VERSION ""

NS_ :

BS_:

BU_:

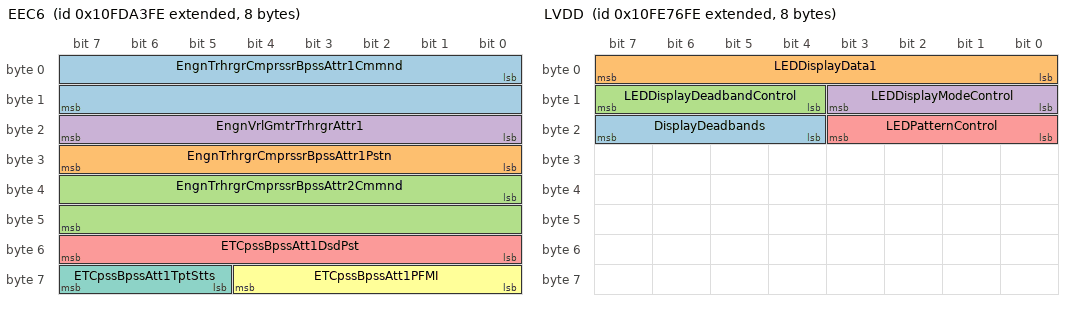
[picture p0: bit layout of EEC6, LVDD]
BO_ 2432541694 EEC6: 8 Vector__XXX
 SG_ EngnTrhrgrCmprssrBpssAttr1Cmmnd : 0|16@1+ (0.0025,0) [0|160.6375] "%" Vector__XXX
 SG_ EngnTrhrgrCmprssrBpssAttr1Pstn : 24|8@1+ (0.4,0) [0|100] "%" Vector__XXX
 SG_ EngnTrhrgrCmprssrBpssAttr2Cmmnd : 32|16@1+ (0.0025,0) [0|160.6375] "%" Vector__XXX
 SG_ EngnVrlGmtrTrhrgrAttr1 : 16|8@1+ (0.4,0) [0|100] "%" Vector__XXX
 SG_ ETCpssBpssAtt1DsdPst : 48|8@1+ (0.4,0) [0|100] "%" Vector__XXX
 SG_ ETCpssBpssAtt1PFMI : 56|5@1+ (1,0) [0|31] "binary" Vector__XXX
 SG_ ETCpssBpssAtt1TptStts : 61|3@1+ (1,0) [0|7] "" Vector__XXX

BO_ 2432593918 ACC1: 8 Vector__XXX
 SG_ ACCDistanceAlertSignal : 52|2@1+ (1,0) [0|3] "" Vector__XXX
 SG_ ACCSystemShutoffWarning : 50|2@1+ (1,0) [0|3] "" Vector__XXX
 SG_ ACCTargetDetected : 48|2@1+ (1,0) [0|3] "" Vector__XXX
 SG_ AdaptiveCruiseControlMode : 24|3@1+ (1,0) [0|7] "" Vector__XXX
 SG_ AdaptiveCruiseControlSetSpeed : 16|8@1+ (1,0) [0|250] "km/h" Vector__XXX
 SG_ Adptvrsntrlstdstnmd : 27|3@1+ (1,0) [0|7] "" Vector__XXX
 SG_ Distancetoforwardvehicle : 8|8@1+ (1,0) [0|250] "m" Vector__XXX
 SG_ ForwardCollisionWarning : 54|2@1+ (1,0) [0|3] "" Vector__XXX
 SG_ Roadcurvature : 32|16@1+ (0.0078125,-250) [-250|251.992] "1/km" Vector__XXX
 SG_ Speedofforwardvehicle : 0|8@1+ (1,0) [0|250] "km/h" Vector__XXX

BO_ 2432595710 LVDD: 8 Vector__XXX
 SG_ DisplayDeadbands : 20|4@1+ (1,0) [0|15] "" Vector__XXX
 SG_ LEDDisplayData1 : 0|8@1+ (1,0) [0|255] "" Vector__XXX
 SG_ LEDDisplayDeadbandControl : 12|4@1+ (1,0) [0|15] "" Vector__XXX
 SG_ LEDDisplayModeControl : 8|4@1+ (1,0) [0|15] "" Vector__XXX
 SG_ LEDPatternControl : 16|4@1+ (1,0) [0|15] "" Vector__XXX

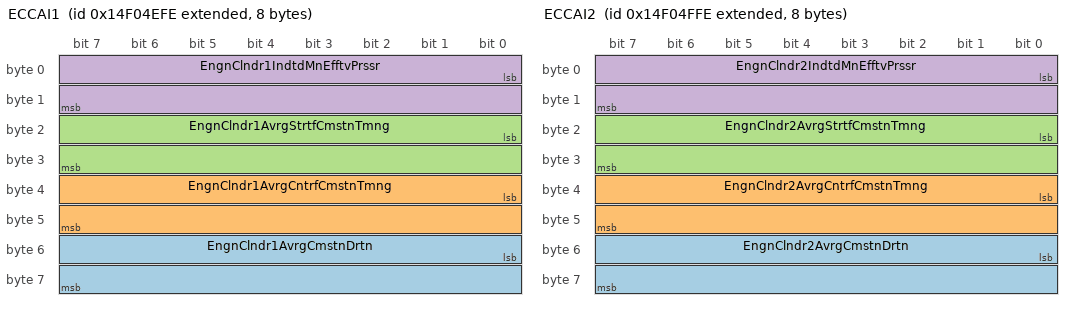
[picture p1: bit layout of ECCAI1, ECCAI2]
BO_ 2498776830 ECCAI1: 8 Vector__XXX
 SG_ EngnClndr1AvrgCmstnDrtn : 48|16@1+ (0.0078125,0) [0|501.99] "deg" Vector__XXX
 SG_ EngnClndr1AvrgCntrfCmstnTmng : 32|16@1+ (0.0078125,-250) [-250|250.992] "deg" Vector__XXX
 SG_ EngnClndr1AvrgStrtfCmstnTmng : 16|16@1+ (0.0078125,-250) [-250|250.992] "deg" Vector__XXX
 SG_ EngnClndr1IndtdMnEfftvPrssr : 0|16@1+ (0.0001220703125,-1) [-1|6.84362793] "MPa" Vector__XXX

BO_ 2498777086 ECCAI2: 8 Vector__XXX
 SG_ EngnClndr2AvrgCmstnDrtn : 48|16@1+ (0.0078125,0) [0|501.99] "deg" Vector__XXX
 SG_ EngnClndr2AvrgCntrfCmstnTmng : 32|16@1+ (0.0078125,-250) [-250|250.992] "deg" Vector__XXX
 SG_ EngnClndr2AvrgStrtfCmstnTmng : 16|16@1+ (0.0078125,-250) [-250|250.992] "deg" Vector__XXX
 SG_ EngnClndr2IndtdMnEfftvPrssr : 0|16@1+ (0.0001220703125,-1) [-1|6.84362793] "MPa" Vector__XXX

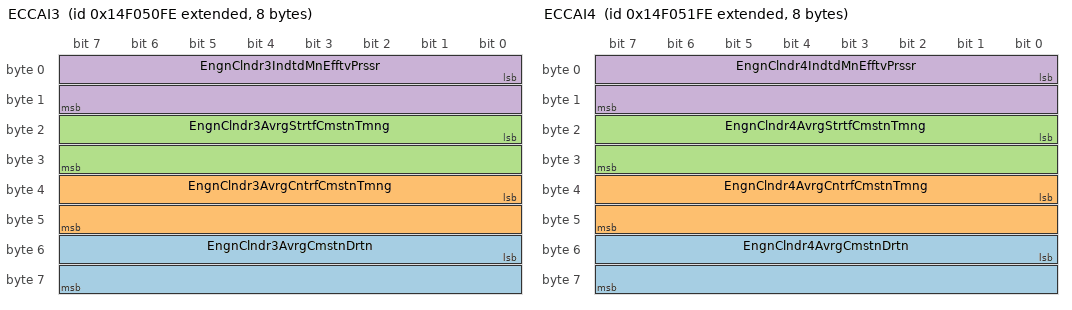
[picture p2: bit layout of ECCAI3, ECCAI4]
BO_ 2498777342 ECCAI3: 8 Vector__XXX
 SG_ EngnClndr3AvrgCmstnDrtn : 48|16@1+ (0.0078125,0) [0|501.99] "deg" Vector__XXX
 SG_ EngnClndr3AvrgCntrfCmstnTmng : 32|16@1+ (0.0078125,-250) [-250|250.992] "deg" Vector__XXX
 SG_ EngnClndr3AvrgStrtfCmstnTmng : 16|16@1+ (0.0078125,-250) [-250|250.992] "deg" Vector__XXX
 SG_ EngnClndr3IndtdMnEfftvPrssr : 0|16@1+ (0.0001220703125,-1) [-1|6.84362793] "MPa" Vector__XXX

BO_ 2498777598 ECCAI4: 8 Vector__XXX
 SG_ EngnClndr4AvrgCmstnDrtn : 48|16@1+ (0.0078125,0) [0|501.99] "deg" Vector__XXX
 SG_ EngnClndr4AvrgCntrfCmstnTmng : 32|16@1+ (0.0078125,-250) [-250|250.992] "deg" Vector__XXX
 SG_ EngnClndr4AvrgStrtfCmstnTmng : 16|16@1+ (0.0078125,-250) [-250|250.992] "deg" Vector__XXX
 SG_ EngnClndr4IndtdMnEfftvPrssr : 0|16@1+ (0.0001220703125,-1) [-1|6.84362793] "MPa" Vector__XXX

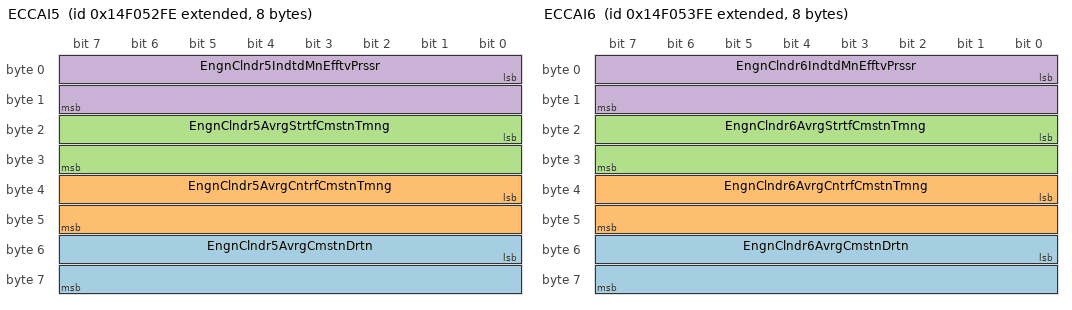
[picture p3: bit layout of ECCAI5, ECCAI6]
BO_ 2498777854 ECCAI5: 8 Vector__XXX
 SG_ EngnClndr5AvrgCmstnDrtn : 48|16@1+ (0.0078125,0) [0|501.99] "deg" Vector__XXX
 SG_ EngnClndr5AvrgCntrfCmstnTmng : 32|16@1+ (0.0078125,-250) [-250|250.992] "deg" Vector__XXX
 SG_ EngnClndr5AvrgStrtfCmstnTmng : 16|16@1+ (0.0078125,-250) [-250|250.992] "deg" Vector__XXX
 SG_ EngnClndr5IndtdMnEfftvPrssr : 0|16@1+ (0.0001220703125,-1) [-1|6.84362793] "MPa" Vector__XXX

BO_ 2498778110 ECCAI6: 8 Vector__XXX
 SG_ EngnClndr6AvrgCmstnDrtn : 48|16@1+ (0.0078125,0) [0|501.99] "deg" Vector__XXX
 SG_ EngnClndr6AvrgCntrfCmstnTmng : 32|16@1+ (0.0078125,-250) [-250|250.992] "deg" Vector__XXX
 SG_ EngnClndr6AvrgStrtfCmstnTmng : 16|16@1+ (0.0078125,-250) [-250|250.992] "deg" Vector__XXX
 SG_ EngnClndr6IndtdMnEfftvPrssr : 0|16@1+ (0.0001220703125,-1) [-1|6.84362793] "MPa" Vector__XXX

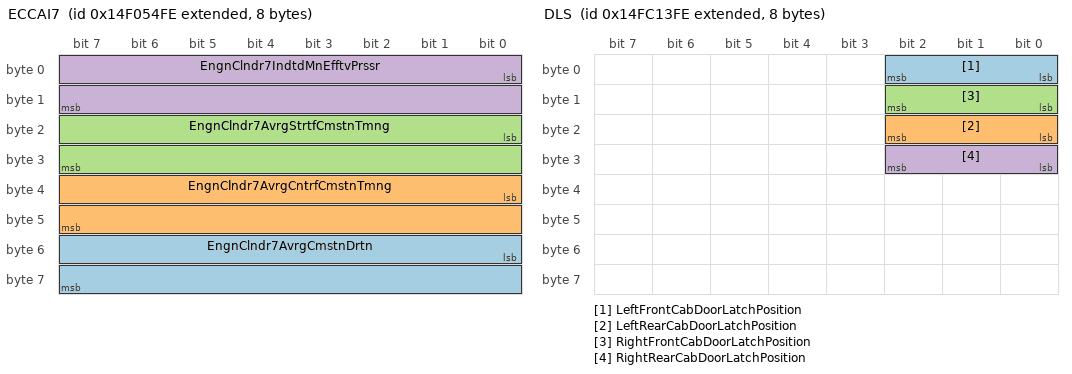
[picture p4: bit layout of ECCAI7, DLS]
BO_ 2498778366 ECCAI7: 8 Vector__XXX
 SG_ EngnClndr7AvrgCmstnDrtn : 48|16@1+ (0.0078125,0) [0|501.99] "deg" Vector__XXX
 SG_ EngnClndr7AvrgCntrfCmstnTmng : 32|16@1+ (0.0078125,-250) [-250|250.992] "deg" Vector__XXX
 SG_ EngnClndr7AvrgStrtfCmstnTmng : 16|16@1+ (0.0078125,-250) [-250|250.992] "deg" Vector__XXX
 SG_ EngnClndr7IndtdMnEfftvPrssr : 0|16@1+ (0.0001220703125,-1) [-1|6.84362793] "MPa" Vector__XXX

BO_ 2498778622 ECCAI8: 8 Vector__XXX
 SG_ EngnClndr8AvrgCmstnDrtn : 48|16@1+ (0.0078125,0) [0|501.99] "deg" Vector__XXX
 SG_ EngnClndr8AvrgCntrfCmstnTmng : 32|16@1+ (0.0078125,-250) [-250|250.992] "deg" Vector__XXX
 SG_ EngnClndr8AvrgStrtfCmstnTmng : 16|16@1+ (0.0078125,-250) [-250|250.992] "deg" Vector__XXX
 SG_ EngnClndr8IndtdMnEfftvPrssr : 0|16@1+ (0.0001220703125,-1) [-1|6.84362793] "MPa" Vector__XXX

BO_ 2498778878 ECCAI9: 8 Vector__XXX
 SG_ EngnClndr9AvrgCmstnDrtn : 48|16@1+ (0.0078125,0) [0|501.99] "deg" Vector__XXX
 SG_ EngnClndr9AvrgCntrfCmstnTmng : 32|16@1+ (0.0078125,-250) [-250|250.992] "deg" Vector__XXX
 SG_ EngnClndr9AvrgStrtfCmstnTmng : 16|16@1+ (0.0078125,-250) [-250|250.992] "deg" Vector__XXX
 SG_ EngnClndr9IndtdMnEfftvPrssr : 0|16@1+ (0.0001220703125,-1) [-1|6.84362793] "MPa" Vector__XXX

BO_ 2498779134 ECCAI10: 8 Vector__XXX
 SG_ EngnClndr10AvrgCmstnDrtn : 48|16@1+ (0.0078125,0) [0|501.99] "deg" Vector__XXX
 SG_ EngnClndr10AvrgCntrfCmstnTmng : 32|16@1+ (0.0078125,-250) [-250|250.992] "deg" Vector__XXX
 SG_ EngnClndr10AvrgStrtfCmstnTmng : 16|16@1+ (0.0078125,-250) [-250|250.992] "deg" Vector__XXX
 SG_ EngnClndr10IndtdMnEfftvPrssr : 0|16@1+ (0.0001220703125,-1) [-1|6.84362793] "MPa" Vector__XXX

BO_ 2498779390 ECCAI11: 8 Vector__XXX
 SG_ EngnClndr11AvrgCmstnDrtn : 48|16@1+ (0.0078125,0) [0|501.99] "deg" Vector__XXX
 SG_ EngnClndr11AvrgCntrfCmstnTmng : 32|16@1+ (0.0078125,-250) [-250|250.992] "deg" Vector__XXX
 SG_ EngnClndr11AvrgStrtfCmstnTmng : 16|16@1+ (0.0078125,-250) [-250|250.992] "deg" Vector__XXX
 SG_ EngnClndr11IndtdMnEfftvPrssr : 0|16@1+ (0.0001220703125,-1) [-1|6.84362793] "MPa" Vector__XXX

BO_ 2498779646 ECCAI12: 8 Vector__XXX
 SG_ EngnClndr12AvrgCmstnDrtn : 48|16@1+ (0.0078125,0) [0|501.99] "deg" Vector__XXX
 SG_ EngnClndr12AvrgCntrfCmstnTmng : 32|16@1+ (0.0078125,-250) [-250|250.992] "deg" Vector__XXX
 SG_ EngnClndr12AvrgStrtfCmstnTmng : 16|16@1+ (0.0078125,-250) [-250|250.992] "deg" Vector__XXX
 SG_ EngnClndr12IndtdMnEfftvPrssr : 0|16@1+ (0.0001220703125,-1) [-1|6.84362793] "MPa" Vector__XXX

BO_ 2498779902 ECCAI13: 8 Vector__XXX
 SG_ EngnClndr13AvrgCmstnDrtn : 48|16@1+ (0.0078125,0) [0|501.99] "deg" Vector__XXX
 SG_ EngnClndr13AvrgCntrfCmstnTmng : 32|16@1+ (0.0078125,-250) [-250|250.992] "deg" Vector__XXX
 SG_ EngnClndr13AvrgStrtfCmstnTmng : 16|16@1+ (0.0078125,-250) [-250|250.992] "deg" Vector__XXX
 SG_ EngnClndr13IndtdMnEfftvPrssr : 0|16@1+ (0.0001220703125,-1) [-1|6.84362793] "MPa" Vector__XXX

BO_ 2498780158 ECCAI14: 8 Vector__XXX
 SG_ EngnClndr14AvrgCmstnDrtn : 48|16@1+ (0.0078125,0) [0|501.99] "deg" Vector__XXX
 SG_ EngnClndr14AvrgCntrfCmstnTmng : 32|16@1+ (0.0078125,-250) [-250|250.992] "deg" Vector__XXX
 SG_ EngnClndr14AvrgStrtfCmstnTmng : 16|16@1+ (0.0078125,-250) [-250|250.992] "deg" Vector__XXX
 SG_ EngnClndr14IndtdMnEfftvPrssr : 0|16@1+ (0.0001220703125,-1) [-1|6.84362793] "MPa" Vector__XXX

BO_ 2498780414 ECCAI15: 8 Vector__XXX
 SG_ EngnClndr15AvrgCmstnDrtn : 48|16@1+ (0.0078125,0) [0|501.99] "deg" Vector__XXX
 SG_ EngnClndr15AvrgCntrfCmstnTmng : 32|16@1+ (0.0078125,-250) [-250|250.992] "deg" Vector__XXX
 SG_ EngnClndr15AvrgStrtfCmstnTmng : 16|16@1+ (0.0078125,-250) [-250|250.992] "deg" Vector__XXX
 SG_ EngnClndr15IndtdMnEfftvPrssr : 0|16@1+ (0.0001220703125,-1) [-1|6.84362793] "MPa" Vector__XXX

BO_ 2498780670 ECCAI16: 8 Vector__XXX
 SG_ EngnClndr16AvrgCmstnDrtn : 48|16@1+ (0.0078125,0) [0|501.99] "deg" Vector__XXX
 SG_ EngnClndr16AvrgCntrfCmstnTmng : 32|16@1+ (0.0078125,-250) [-250|250.992] "deg" Vector__XXX
 SG_ EngnClndr16AvrgStrtfCmstnTmng : 16|16@1+ (0.0078125,-250) [-250|250.992] "deg" Vector__XXX
 SG_ EngnClndr16IndtdMnEfftvPrssr : 0|16@1+ (0.0001220703125,-1) [-1|6.84362793] "MPa" Vector__XXX

BO_ 2498780926 ECCAI17: 8 Vector__XXX
 SG_ EngnClndr17AvrgCmstnDrtn : 48|16@1+ (0.0078125,0) [0|501.99] "deg" Vector__XXX
 SG_ EngnClndr17AvrgCntrfCmstnTmng : 32|16@1+ (0.0078125,-250) [-250|250.992] "deg" Vector__XXX
 SG_ EngnClndr17AvrgStrtfCmstnTmng : 16|16@1+ (0.0078125,-250) [-250|250.992] "deg" Vector__XXX
 SG_ EngnClndr17IndtdMnEfftvPrssr : 0|16@1+ (0.0001220703125,-1) [-1|6.84362793] "MPa" Vector__XXX

BO_ 2498781182 ECCAI18: 8 Vector__XXX
 SG_ EngnClndr18AvrgCmstnDrtn : 48|16@1+ (0.0078125,0) [0|501.99] "deg" Vector__XXX
 SG_ EngnClndr18AvrgCntrfCmstnTmng : 32|16@1+ (0.0078125,-250) [-250|250.992] "deg" Vector__XXX
 SG_ EngnClndr18AvrgStrtfCmstnTmng : 16|16@1+ (0.0078125,-250) [-250|250.992] "deg" Vector__XXX
 SG_ EngnClndr18IndtdMnEfftvPrssr : 0|16@1+ (0.0001220703125,-1) [-1|6.84362793] "MPa" Vector__XXX

BO_ 2498781438 ECCAI19: 8 Vector__XXX
 SG_ EngnClndr19AvrgCmstnDrtn : 48|16@1+ (0.0078125,0) [0|501.99] "deg" Vector__XXX
 SG_ EngnClndr19AvrgCntrfCmstnTmng : 32|16@1+ (0.0078125,-250) [-250|250.992] "deg" Vector__XXX
 SG_ EngnClndr19AvrgStrtfCmstnTmng : 16|16@1+ (0.0078125,-250) [-250|250.992] "deg" Vector__XXX
 SG_ EngnClndr19IndtdMnEfftvPrssr : 0|16@1+ (0.0001220703125,-1) [-1|6.84362793] "MPa" Vector__XXX

BO_ 2498781694 ECCAI20: 8 Vector__XXX
 SG_ EngnClndr20AvrgCmstnDrtn : 48|16@1+ (0.0078125,0) [0|501.99] "deg" Vector__XXX
 SG_ EngnClndr20AvrgCntrfCmstnTmng : 32|16@1+ (0.0078125,-250) [-250|250.992] "deg" Vector__XXX
 SG_ EngnClndr20AvrgStrtfCmstnTmng : 16|16@1+ (0.0078125,-250) [-250|250.992] "deg" Vector__XXX
 SG_ EngnClndr20IndtdMnEfftvPrssr : 0|16@1+ (0.0001220703125,-1) [-1|6.84362793] "MPa" Vector__XXX

BO_ 2498825982 DTBI1: 8 Vector__XXX
 SG_ DmpBdRsPstnRltvtRmmnddMxmm : 32|16@1+ (0.005,-150) [-150|171.275] "%" Vector__XXX
 SG_ DumpBodyEjectorBladePosition : 48|8@1+ (0.4,0) [0|100] "%" Vector__XXX
 SG_ DumpBodyRaiseAngle : 16|16@1+ (0.0078125,-200) [-200|301.99] "deg" Vector__XXX
 SG_ DumpBodyRollAngle : 0|16@1+ (0.0078125,-200) [-200|301.99] "deg" Vector__XXX

BO_ 2499547902 CDC: 8 Vector__XXX
 SG_ CabDoorsLockActuationCommand : 0|3@1+ (1,0) [0|7] "" Vector__XXX
 SG_ LeftFrontWindowPositionCommand : 16|3@1+ (1,0) [0|7] "" Vector__XXX
 SG_ LeftRearWindowPositionCommand : 24|3@1+ (1,0) [0|7] "" Vector__XXX
 SG_ MirrorLeft1HeatCommand : 48|2@1+ (1,0) [0|3] "" Vector__XXX
 SG_ MirrorLeft1HorizontalCommand : 32|2@1+ (1,0) [0|3] "" Vector__XXX
 SG_ MirrorLeft1VerticalCommand : 34|2@1+ (1,0) [0|3] "" Vector__XXX
 SG_ MirrorLeft2HeatCommand : 52|2@1+ (1,0) [0|3] "" Vector__XXX
 SG_ MirrorLeft2HorizontalCommand : 40|2@1+ (1,0) [0|3] "" Vector__XXX
 SG_ MirrorLeft2VerticalCommand : 42|2@1+ (1,0) [0|3] "" Vector__XXX
 SG_ MirrorRight1HeatCommand : 50|2@1+ (1,0) [0|3] "" Vector__XXX
 SG_ MirrorRight1HorizontalCommand : 36|2@1+ (1,0) [0|3] "" Vector__XXX
 SG_ MirrorRight1VerticalCommand : 38|2@1+ (1,0) [0|3] "" Vector__XXX
 SG_ MirrorRight2HeatCommand : 54|2@1+ (1,0) [0|3] "" Vector__XXX
 SG_ MirrorRight2HorizontalCommand : 44|2@1+ (1,0) [0|3] "" Vector__XXX
 SG_ MirrorRight2VerticalCommand : 46|2@1+ (1,0) [0|3] "" Vector__XXX
 SG_ RemoteCabDoorLockRequest : 8|3@1+ (1,0) [0|7] "" Vector__XXX
 SG_ RightFrontWindowPositionCommand : 19|3@1+ (1,0) [0|7] "" Vector__XXX
 SG_ RightRearWindowPositionCommand : 27|3@1+ (1,0) [0|7] "" Vector__XXX

BO_ 2499548158 DLS: 8 Vector__XXX
 SG_ LeftFrontCabDoorLatchPosition : 0|3@1+ (1,0) [0|7] "" Vector__XXX
 SG_ LeftRearCabDoorLatchPosition : 16|3@1+ (1,0) [0|7] "" Vector__XXX
 SG_ RightFrontCabDoorLatchPosition : 8|3@1+ (1,0) [0|7] "" Vector__XXX
 SG_ RightRearCabDoorLatchPosition : 24|3@1+ (1,0) [0|7] "" Vector__XXX

BO_ 2499548670 VEP6: 8 Vector__XXX
 SG_ BatteryPotentialPowerInput3 : 0|16@1+ (0.05,0) [0|3212.75] "V" Vector__XXX
 SG_ BatteryPotentialPowerInput4 : 16|16@1+ (0.05,0) [0|3212.75] "V" Vector__XXX
 SG_ SLIBattery3NetCurrent : 32|16@1+ (0.05,-1600) [-1600|1612.75] "A" Vector__XXX
 SG_ SLIBattery4NetCurrent : 48|16@1+ (0.05,-1600) [-1600|1612.75] "A" Vector__XXX

BO_ 2499548926 PLT2: 8 Vector__XXX
 SG_ PayloadTemperature5 : 0|16@1+ (0.03125,-273) [-273|1734.96875] "degC" Vector__XXX

BO_ 2499549182 PLT1: 8 Vector__XXX
 SG_ PayloadTemperature1 : 0|16@1+ (0.03125,-273) [-273|1734.96875] "degC" Vector__XXX
 SG_ PayloadTemperature2 : 16|16@1+ (0.03125,-273) [-273|1734.96875] "degC" Vector__XXX
 SG_ PayloadTemperature3 : 32|16@1+ (0.03125,-273) [-273|1734.96875] "degC" Vector__XXX
 SG_ PayloadTemperature4 : 48|16@1+ (0.03125,-273) [-273|1734.96875] "degC" Vector__XXX

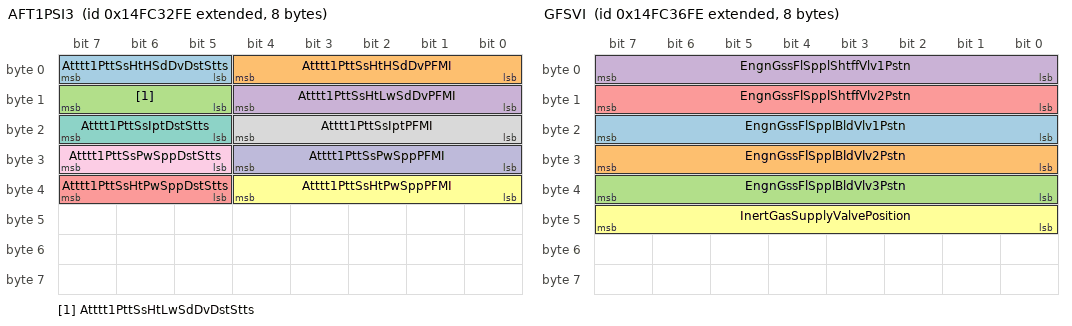
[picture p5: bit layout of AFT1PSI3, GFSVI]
BO_ 2499556094 AFT1PSI3: 8 Vector__XXX
 SG_ Atttt1PttSsHtHSdDvDstStts : 5|3@1+ (1,0) [0|7] "" Vector__XXX
 SG_ Atttt1PttSsHtHSdDvPFMI : 0|5@1+ (1,0) [0|31] "" Vector__XXX
 SG_ Atttt1PttSsHtLwSdDvDstStts : 13|3@1+ (1,0) [0|7] "" Vector__XXX
 SG_ Atttt1PttSsHtLwSdDvPFMI : 8|5@1+ (1,0) [0|31] "" Vector__XXX
 SG_ Atttt1PttSsHtPwSppDstStts : 37|3@1+ (1,0) [0|7] "" Vector__XXX
 SG_ Atttt1PttSsHtPwSppPFMI : 32|5@1+ (1,0) [0|31] "" Vector__XXX
 SG_ Atttt1PttSsIptDstStts : 21|3@1+ (1,0) [0|7] "" Vector__XXX
 SG_ Atttt1PttSsIptPFMI : 16|5@1+ (1,0) [0|31] "" Vector__XXX
 SG_ Atttt1PttSsPwSppDstStts : 29|3@1+ (1,0) [0|7] "" Vector__XXX
 SG_ Atttt1PttSsPwSppPFMI : 24|5@1+ (1,0) [0|31] "" Vector__XXX

BO_ 2499556350 EFIMRPI3: 8 Vector__XXX
 SG_ EngnFl1InjtrMtrngRl1DsrdPrssr : 0|16@1+ (5,0) [0|321275] "kPa" Vector__XXX
 SG_ EngnFl1InjtrMtrngRl2DsrdPrssr : 16|16@1+ (5,0) [0|321275] "kPa" Vector__XXX

BO_ 2499556606 EFIMRPI2: 8 Vector__XXX
 SG_ EF1ItMtR1Pss1ExtddR : 0|16@1+ (5,0) [0|321275] "kPa" Vector__XXX
 SG_ EF1ItMtR1Pss2ExtddR : 16|16@1+ (5,0) [0|321275] "kPa" Vector__XXX
 SG_ EF1ItMtR2Pss1ExtddR : 32|16@1+ (5,0) [0|321275] "kPa" Vector__XXX
 SG_ EF1ItMtR2Pss2ExtddR : 48|16@1+ (5,0) [0|321275] "kPa" Vector__XXX

BO_ 2499557118 GFSVI: 8 Vector__XXX
 SG_ EngnGssFlSpplBldVlv1Pstn : 16|8@1+ (0.4,0) [0|100] "%" Vector__XXX
 SG_ EngnGssFlSpplBldVlv2Pstn : 24|8@1+ (0.4,0) [0|100] "%" Vector__XXX
 SG_ EngnGssFlSpplBldVlv3Pstn : 32|8@1+ (0.4,0) [0|100] "%" Vector__XXX
 SG_ EngnGssFlSpplShtffVlv1Pstn : 0|8@1+ (0.4,0) [0|100] "%" Vector__XXX
 SG_ EngnGssFlSpplShtffVlv2Pstn : 8|8@1+ (0.4,0) [0|100] "%" Vector__XXX
 SG_ InertGasSupplyValvePosition : 40|8@1+ (0.4,0) [0|100] "%" Vector__XXX

BO_ 2499557374 EOMDI2: 8 Vector__XXX
 SG_ EngineOilMist10Concentration : 8|8@1+ (1,0) [0|250] "%" Vector__XXX
 SG_ EngineOilMist9Concentration : 0|8@1+ (1,0) [0|250] "%" Vector__XXX

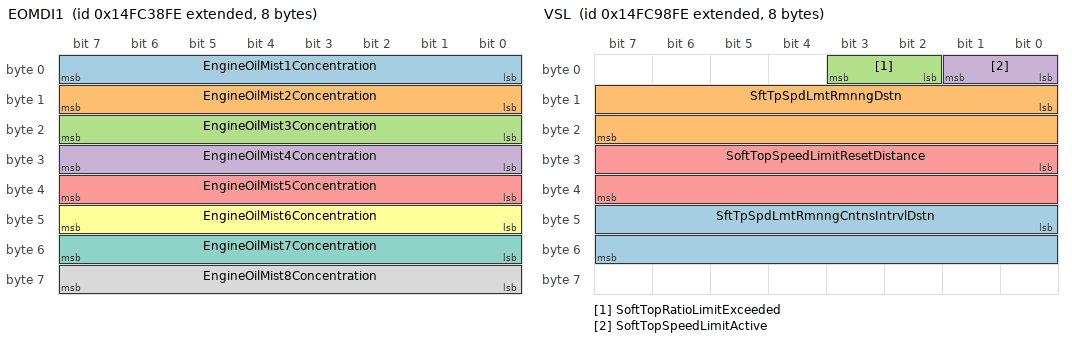
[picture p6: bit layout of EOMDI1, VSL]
BO_ 2499557630 EOMDI1: 8 Vector__XXX
 SG_ EngineOilMist1Concentration : 0|8@1+ (1,0) [0|250] "%" Vector__XXX
 SG_ EngineOilMist2Concentration : 8|8@1+ (1,0) [0|250] "%" Vector__XXX
 SG_ EngineOilMist3Concentration : 16|8@1+ (1,0) [0|250] "%" Vector__XXX
 SG_ EngineOilMist4Concentration : 24|8@1+ (1,0) [0|250] "%" Vector__XXX
 SG_ EngineOilMist5Concentration : 32|8@1+ (1,0) [0|250] "%" Vector__XXX
 SG_ EngineOilMist6Concentration : 40|8@1+ (1,0) [0|250] "%" Vector__XXX
 SG_ EngineOilMist7Concentration : 48|8@1+ (1,0) [0|250] "%" Vector__XXX
 SG_ EngineOilMist8Concentration : 56|8@1+ (1,0) [0|250] "%" Vector__XXX

BO_ 2499557886 GFSP2: 8 Vector__XXX
 SG_ PlntGssFlSpplOtltPrssr : 0|16@1+ (0.5,0) [0|32127.5] "kPa" Vector__XXX
 SG_ PlntInrtGsSpplOtltPrssr : 16|16@1+ (0.5,0) [0|32127.5] "kPa" Vector__XXX

BO_ 2499558142 GFSP1: 8 Vector__XXX
 SG_ EngnGssFlSpplPrssr2 : 0|16@1+ (0.5,0) [0|32127.5] "kPa" Vector__XXX
 SG_ EngnGssFlSpplShtffVlv1IntkPrssr : 32|16@1+ (0.5,0) [0|32127.5] "kPa" Vector__XXX
 SG_ EngnGssFlSpplShtffVlv2IntkPrssr : 48|16@1+ (0.5,0) [0|32127.5] "kPa" Vector__XXX
 SG_ EngnGssFlSpplUntIntkPrssr : 16|16@1+ (0.5,0) [0|32127.5] "kPa" Vector__XXX

BO_ 2499580158 EFIMRPI1: 8 Vector__XXX
 SG_ EngnFl1InjtrMtrngRl1Prssr1 : 0|16@1+ (0.00390625,0) [0|250.996] "MPa" Vector__XXX
 SG_ EngnFl1InjtrMtrngRl1Prssr2 : 16|16@1+ (0.00390625,0) [0|250.996] "MPa" Vector__XXX
 SG_ EngnFl1InjtrMtrngRl2Prssr1 : 32|16@1+ (0.00390625,0) [0|250.996] "MPa" Vector__XXX
 SG_ EngnFl1InjtrMtrngRl2Prssr2 : 48|16@1+ (0.00390625,0) [0|250.996] "MPa" Vector__XXX

BO_ 2499582206 VSL: 8 Vector__XXX
 SG_ SftTpSpdLmtRmnngCntnsIntrvlDstn : 40|16@1+ (1,0) [0|64255] "km" Vector__XXX
 SG_ SftTpSpdLmtRmnngDstn : 8|16@1+ (1,0) [0|64255] "km" Vector__XXX
 SG_ SoftTopRatioLimitExceeded : 2|2@1+ (1,0) [0|3] "" Vector__XXX
 SG_ SoftTopSpeedLimitActive : 0|2@1+ (1,0) [0|3] "" Vector__XXX
 SG_ SoftTopSpeedLimitResetDistance : 24|16@1+ (1,0) [0|64255] "km" Vector__XXX

BO_ 2499583486 ETAPC: 8 Vector__XXX
 SG_ EngnTmngAttr1PstnCmmnd : 0|3@1+ (1,0) [0|7] "" Vector__XXX
 SG_ EngnTmngAttr2PstnCmmnd : 3|3@1+ (1,0) [0|7] "" Vector__XXX

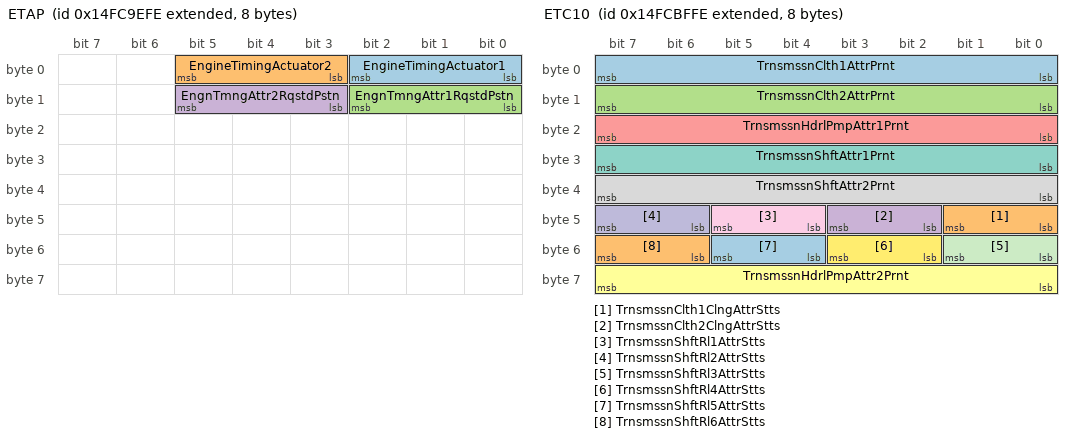
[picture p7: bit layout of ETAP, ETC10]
BO_ 2499583742 ETAP: 8 Vector__XXX
 SG_ EngineTimingActuator1 : 0|3@1+ (1,0) [0|7] "" Vector__XXX
 SG_ EngineTimingActuator2 : 3|3@1+ (1,0) [0|7] "" Vector__XXX
 SG_ EngnTmngAttr1RqstdPstn : 8|3@1+ (1,0) [0|7] "" Vector__XXX
 SG_ EngnTmngAttr2RqstdPstn : 11|3@1+ (1,0) [0|7] "" Vector__XXX

BO_ 2499592190 ETC10: 8 Vector__XXX
 SG_ TrnsmssnClth1AttrPrnt : 0|8@1+ (0.4,0) [0|100] "%" Vector__XXX
 SG_ TrnsmssnClth1ClngAttrStts : 40|2@1+ (1,0) [0|3] "" Vector__XXX
 SG_ TrnsmssnClth2AttrPrnt : 8|8@1+ (0.4,0) [0|100] "%" Vector__XXX
 SG_ TrnsmssnClth2ClngAttrStts : 42|2@1+ (1,0) [0|3] "" Vector__XXX
 SG_ TrnsmssnHdrlPmpAttr1Prnt : 16|8@1+ (0.4,0) [0|100] "%" Vector__XXX
 SG_ TrnsmssnHdrlPmpAttr2Prnt : 56|8@1+ (0.4,0) [0|100] "%" Vector__XXX
 SG_ TrnsmssnShftAttr1Prnt : 24|8@1+ (0.4,0) [0|100] "%" Vector__XXX
 SG_ TrnsmssnShftAttr2Prnt : 32|8@1+ (0.4,0) [0|100] "%" Vector__XXX
 SG_ TrnsmssnShftRl1AttrStts : 44|2@1+ (1,0) [0|3] "" Vector__XXX
 SG_ TrnsmssnShftRl2AttrStts : 46|2@1+ (1,0) [0|3] "" Vector__XXX
 SG_ TrnsmssnShftRl3AttrStts : 48|2@1+ (1,0) [0|3] "" Vector__XXX
 SG_ TrnsmssnShftRl4AttrStts : 50|2@1+ (1,0) [0|3] "" Vector__XXX
 SG_ TrnsmssnShftRl5AttrStts : 52|2@1+ (1,0) [0|3] "" Vector__XXX
 SG_ TrnsmssnShftRl6AttrStts : 54|2@1+ (1,0) [0|3] "" Vector__XXX

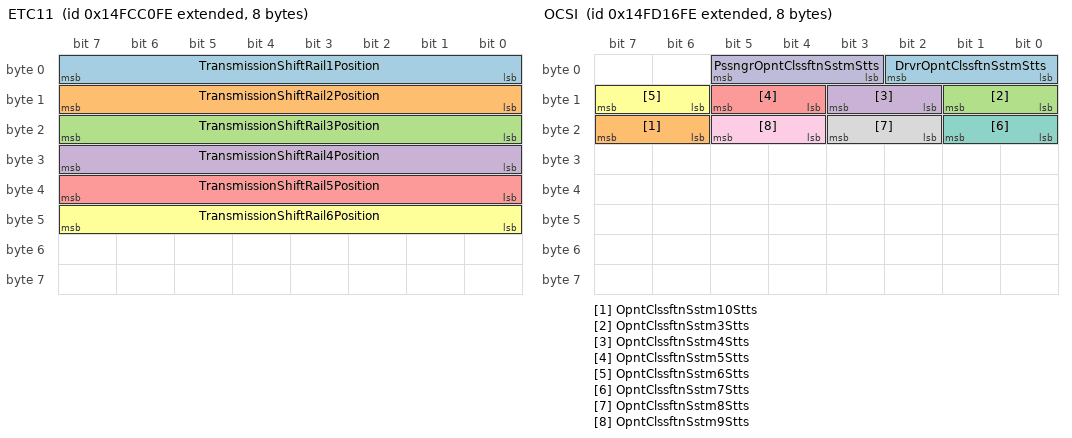
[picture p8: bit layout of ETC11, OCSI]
BO_ 2499592446 ETC11: 8 Vector__XXX
 SG_ TransmissionShiftRail1Position : 0|8@1+ (0.4,0) [0|100] "%" Vector__XXX
 SG_ TransmissionShiftRail2Position : 8|8@1+ (0.4,0) [0|100] "%" Vector__XXX
 SG_ TransmissionShiftRail3Position : 16|8@1+ (0.4,0) [0|100] "%" Vector__XXX
 SG_ TransmissionShiftRail4Position : 24|8@1+ (0.4,0) [0|100] "%" Vector__XXX
 SG_ TransmissionShiftRail5Position : 32|8@1+ (0.4,0) [0|100] "%" Vector__XXX
 SG_ TransmissionShiftRail6Position : 40|8@1+ (0.4,0) [0|100] "%" Vector__XXX

BO_ 2499604222 LLRE: 8 Vector__XXX
 SG_ BladeElevationDeviationLeft : 0|16@1+ (1,-32000) [-32000|32255] "mm" Vector__XXX
 SG_ BladeElevationDeviationRight : 16|16@1+ (1,-32000) [-32000|32255] "mm" Vector__XXX
 SG_ BldRfrnElvtnOffstLft : 32|16@1+ (1,-32000) [-32000|32255] "mm" Vector__XXX
 SG_ BldRfrnElvtnOffstRght : 48|16@1+ (1,-32000) [-32000|32255] "mm" Vector__XXX

BO_ 2499604478 EFLP11: 8 Vector__XXX
 SG_ EExstGsRt1OttAstPssHRst : 16|16@1+ (0.1,0) [0|6425.5] "kPa" Vector__XXX
 SG_ EFDvPssHRstExtddR : 48|16@1+ (0.1,0) [0|6425.5] "kPa" Vector__XXX
 SG_ EngnExhstGsRrltn1IntkAsltPrssr : 0|16@1+ (0.1,0) [0|6425.5] "kPa" Vector__XXX
 SG_ EngnOlPrssrHghRsltnExtnddRng : 32|16@1+ (0.1,0) [0|6425.5] "kPa" Vector__XXX

BO_ 2499607550 EMAP: 8 Vector__XXX
 SG_ EExstMdB1FwBVvAttPst : 0|16@1+ (0.0025,0) [0|160.6375] "%" Vector__XXX
 SG_ EExstMdB2FwBVvAttPst : 16|16@1+ (0.0025,0) [0|160.6375] "%" Vector__XXX

BO_ 2499614462 OCSI: 8 Vector__XXX
 SG_ DrvrOpntClssftnSstmStts : 0|3@1+ (1,0) [0|7] "" Vector__XXX
 SG_ OpntClssftnSstm10Stts : 22|2@1+ (1,0) [0|3] "" Vector__XXX
 SG_ OpntClssftnSstm3Stts : 8|2@1+ (1,0) [0|3] "" Vector__XXX
 SG_ OpntClssftnSstm4Stts : 10|2@1+ (1,0) [0|3] "" Vector__XXX
 SG_ OpntClssftnSstm5Stts : 12|2@1+ (1,0) [0|3] "" Vector__XXX
 SG_ OpntClssftnSstm6Stts : 14|2@1+ (1,0) [0|3] "" Vector__XXX
 SG_ OpntClssftnSstm7Stts : 16|2@1+ (1,0) [0|3] "" Vector__XXX
 SG_ OpntClssftnSstm8Stts : 18|2@1+ (1,0) [0|3] "" Vector__XXX
 SG_ OpntClssftnSstm9Stts : 20|2@1+ (1,0) [0|3] "" Vector__XXX
 SG_ PssngrOpntClssftnSstmStts : 3|3@1+ (1,0) [0|7] "" Vector__XXX

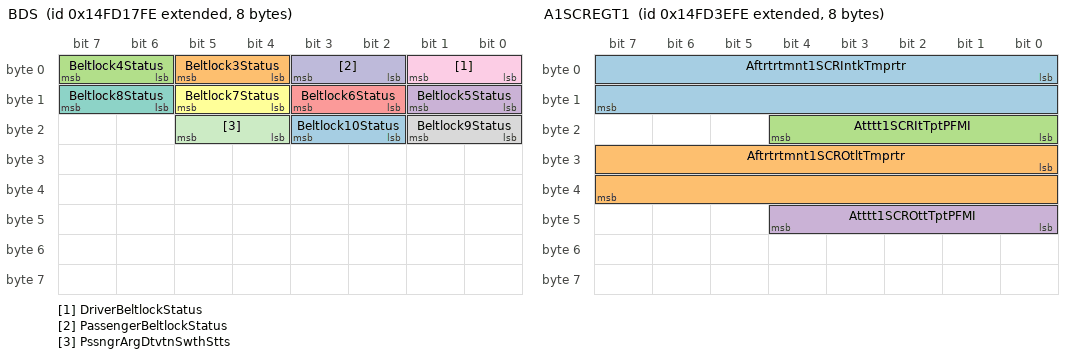
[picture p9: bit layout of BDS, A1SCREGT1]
BO_ 2499614718 BDS: 8 Vector__XXX
 SG_ Beltlock10Status : 18|2@1+ (1,0) [0|3] "" Vector__XXX
 SG_ Beltlock3Status : 4|2@1+ (1,0) [0|3] "" Vector__XXX
 SG_ Beltlock4Status : 6|2@1+ (1,0) [0|3] "" Vector__XXX
 SG_ Beltlock5Status : 8|2@1+ (1,0) [0|3] "" Vector__XXX
 SG_ Beltlock6Status : 10|2@1+ (1,0) [0|3] "" Vector__XXX
 SG_ Beltlock7Status : 12|2@1+ (1,0) [0|3] "" Vector__XXX
 SG_ Beltlock8Status : 14|2@1+ (1,0) [0|3] "" Vector__XXX
 SG_ Beltlock9Status : 16|2@1+ (1,0) [0|3] "" Vector__XXX
 SG_ DriverBeltlockStatus : 0|2@1+ (1,0) [0|3] "" Vector__XXX
 SG_ PassengerBeltlockStatus : 2|2@1+ (1,0) [0|3] "" Vector__XXX
 SG_ PssngrArgDtvtnSwthStts : 20|2@1+ (1,0) [0|3] "" Vector__XXX

BO_ 2499624702 A1SCREGT1: 8 Vector__XXX
 SG_ Aftrtrtmnt1SCRIntkTmprtr : 0|16@1+ (0.03125,-273) [-273|1734.96875] "degC" Vector__XXX
 SG_ Aftrtrtmnt1SCROtltTmprtr : 24|16@1+ (0.03125,-273) [-273|1734.96875] "degC" Vector__XXX
 SG_ Atttt1SCRItTptPFMI : 16|5@1+ (1,0) [0|31] "" Vector__XXX
 SG_ Atttt1SCROttTptPFMI : 40|5@1+ (1,0) [0|31] "" Vector__XXX

BO_ 2499630078 EAI: 8 Vector__XXX
 SG_ EngineExhaustTemperatureAverage : 0|16@1+ (0.03125,-273) [-273|1734.96875] "degC" Vector__XXX
 SG_ EngnExhstBnk1TmprtrAvrg : 16|16@1+ (0.03125,-273) [-273|1734.96875] "degC" Vector__XXX
 SG_ EngnExhstBnk2TmprtrAvrg : 32|16@1+ (0.03125,-273) [-273|1734.96875] "degC" Vector__XXX

BO_ 2499635454 GCVW: 8 Vector__XXX
 SG_ GrossCombinationWeight : 0|24@1+ (2,0) [0|3E+07] "kg" Vector__XXX
 SG_ NetVehicleWeightChange : 24|24@1+ (2,-16449535) [-16449535|1.64495E+07] "kg" Vector__XXX

BO_ 2499635966 AGW: 8 Vector__XXX
 SG_ AdditionalAxleGroupLocation : 4|4@1+ (1,0) [0|15] "" Vector__XXX
 SG_ AxleGroupLocation : 0|4@1+ (1,0) [0|15] "" Vector__XXX
 SG_ AxleGroupWeight : 8|16@1+ (2,0) [0|128510] "kg" Vector__XXX

BO_ 2499641854 EGRBV: 8 Vector__XXX
 SG_ EExstGsRt1CBpssAttPst : 0|8@1+ (0.4,0) [0|100] "%" Vector__XXX

BO_ 2550660862 GPV4: 8 Vector__XXX
 SG_ ValveAssemblyLoadsensePressure : 24|16@1+ (5,0) [0|321275] "kPa" Vector__XXX
 SG_ ValveAssemblySupplyPressure : 40|16@1+ (5,0) [0|321275] "kPa" Vector__XXX
 SG_ ValveLoadSensePressure : 0|16@1+ (5,0) [0|321275] "kPa" Vector__XXX
 SG_ ValvePilotPressure : 16|8@1+ (16,0) [0|4000] "kPa" Vector__XXX

BO_ 2550988542 EEC16: 8 Vector__XXX
 SG_ EngineClutchEngageRequestStatus : 10|2@1+ (1,0) [0|3] "" Vector__XXX
 SG_ ReadyForClutchEngagementStatus : 8|2@1+ (1,0) [0|3] "" Vector__XXX
 SG_ AcceleratorPedal3Position : 0|8@1+ (0.4,0) [0|100] "%" Vector__XXX

BO_ 2557214462 WSPSCC: 8 Vector__XXX
 SG_ WSttPpDsPssCtStPtCd : 8|4@1+ (1,0) [0|15] "" Vector__XXX
 SG_ WSttPpStPssCtStPtCd : 0|4@1+ (1,0) [0|15] "" Vector__XXX

BO_ 2557345534 WSPT1: 19 Vector__XXX
 SG_ WllStmltnPmpPlngrFrngOrdr : 144|4@1+ (1,0) [0|15] "" Vector__XXX
 SG_ WllStmltnPmpRdLdHghThrshld : 128|16@1+ (5,0) [0|321275] "kN" Vector__XXX
 SG_ WllStmltnPmpStnPrssrHghThrshld : 64|16@1+ (0.1,-3212.7) [-3212.7|3212.8] "kPa" Vector__XXX
 SG_ WllStmltnPmpStnPrssrLwThrshld : 48|16@1+ (0.1,-3212.7) [-3212.7|3212.8] "kPa" Vector__XXX
 SG_ WSttPpCstSpdHTsd : 112|16@1+ (0.125,0) [0|8031.875] "rpm" Vector__XXX
 SG_ WSttPpCstSpdLwTsd : 96|16@1+ (0.125,0) [0|8031.875] "rpm" Vector__XXX
 SG_ WSttPpDsPssHTsd : 80|16@1+ (5,0) [0|321275] "kPa" Vector__XXX
 SG_ WSttPpGBxOPssHTsd : 16|16@1+ (0.1,0) [0|6425.5] "kPa" Vector__XXX
 SG_ WSttPpGBxOPssLwTsd : 0|16@1+ (0.1,0) [0|6425.5] "kPa" Vector__XXX
 SG_ WSttPpGBxOTptHTsd : 40|8@1+ (1,-40) [-40|210] "degC" Vector__XXX
 SG_ WSttPpGBxOTptLwTsd : 32|8@1+ (1,-40) [-40|210] "degC" Vector__XXX

BO_ 2557673214 ODMCC: 37 Vector__XXX
 SG_ OlDrsMntrCnfgrtnIdntftnNmr : 0|8@1+ (1,0) [0|250] "count" Vector__XXX
 SG_ OlDrsMntrFrrsBn1CntCmmnd : 8|24@1+ (1,0) [0|1.64495E+07] "count" Vector__XXX
 SG_ OlDrsMntrFrrsBn2CntCmmnd : 32|24@1+ (1,0) [0|1.64495E+07] "count" Vector__XXX
 SG_ OlDrsMntrFrrsBn3CntCmmnd : 56|24@1+ (1,0) [0|1.64495E+07] "count" Vector__XXX
 SG_ OlDrsMntrFrrsBn4CntCmmnd : 80|24@1+ (1,0) [0|1.64495E+07] "count" Vector__XXX
 SG_ OlDrsMntrFrrsBn5CntCmmnd : 104|24@1+ (1,0) [0|1.64495E+07] "count" Vector__XXX
 SG_ OlDrsMntrFrrsBn6CntCmmnd : 128|24@1+ (1,0) [0|1.64495E+07] "count" Vector__XXX
 SG_ OlDrsMntrNnFrrsBn1CntCmmnd : 152|24@1+ (1,0) [0|1.64495E+07] "count" Vector__XXX
 SG_ OlDrsMntrNnFrrsBn2CntCmmnd : 176|24@1+ (1,0) [0|1.64495E+07] "count" Vector__XXX
 SG_ OlDrsMntrNnFrrsBn3CntCmmnd : 200|24@1+ (1,0) [0|1.64495E+07] "count" Vector__XXX
 SG_ OlDrsMntrNnFrrsBn4CntCmmnd : 224|24@1+ (1,0) [0|1.64495E+07] "count" Vector__XXX
 SG_ OlDrsMntrNnFrrsBn5CntCmmnd : 248|24@1+ (1,0) [0|1.64495E+07] "count" Vector__XXX
 SG_ OlDrsMntrNnFrrsBn6CntCmmnd : 272|24@1+ (1,0) [0|1.64495E+07] "count" Vector__XXX

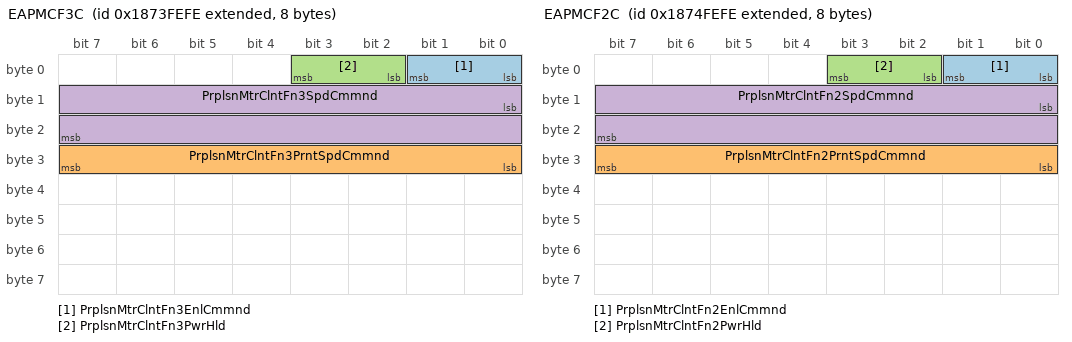
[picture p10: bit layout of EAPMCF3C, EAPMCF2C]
BO_ 2557738750 EAPMCF3C: 8 Vector__XXX
 SG_ PrplsnMtrClntFn3EnlCmmnd : 0|2@1+ (1,0) [0|3] "" Vector__XXX
 SG_ PrplsnMtrClntFn3PrntSpdCmmnd : 24|8@1+ (0.5,0) [0|125] "%" Vector__XXX
 SG_ PrplsnMtrClntFn3PwrHld : 2|2@1+ (1,0) [0|3] "" Vector__XXX
 SG_ PrplsnMtrClntFn3SpdCmmnd : 8|16@1+ (0.5,0) [0|32127.5] "rpm" Vector__XXX

BO_ 2557804286 EAPMCF2C: 8 Vector__XXX
 SG_ PrplsnMtrClntFn2EnlCmmnd : 0|2@1+ (1,0) [0|3] "" Vector__XXX
 SG_ PrplsnMtrClntFn2PrntSpdCmmnd : 24|8@1+ (0.5,0) [0|125] "%" Vector__XXX
 SG_ PrplsnMtrClntFn2PwrHld : 2|2@1+ (1,0) [0|3] "" Vector__XXX
 SG_ PrplsnMtrClntFn2SpdCmmnd : 8|16@1+ (0.5,0) [0|32127.5] "rpm" Vector__XXX

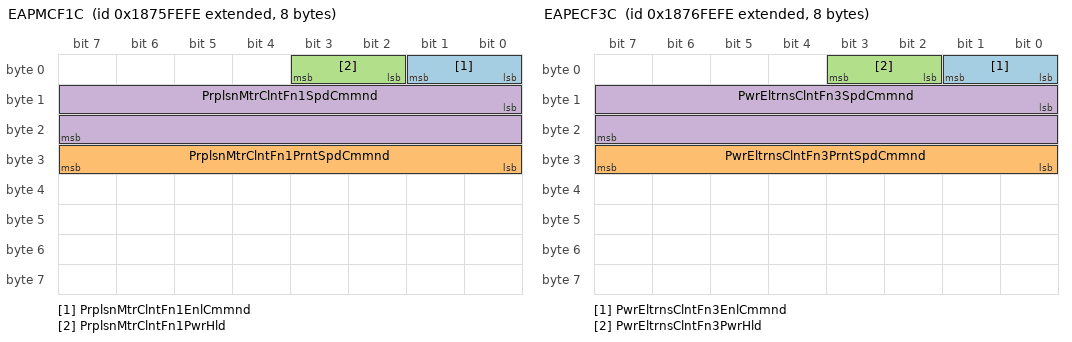
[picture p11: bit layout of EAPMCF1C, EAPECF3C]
BO_ 2557869822 EAPMCF1C: 8 Vector__XXX
 SG_ PrplsnMtrClntFn1EnlCmmnd : 0|2@1+ (1,0) [0|3] "" Vector__XXX
 SG_ PrplsnMtrClntFn1PrntSpdCmmnd : 24|8@1+ (0.5,0) [0|125] "%" Vector__XXX
 SG_ PrplsnMtrClntFn1PwrHld : 2|2@1+ (1,0) [0|3] "" Vector__XXX
 SG_ PrplsnMtrClntFn1SpdCmmnd : 8|16@1+ (0.5,0) [0|32127.5] "rpm" Vector__XXX

BO_ 2557935358 EAPECF3C: 8 Vector__XXX
 SG_ PwrEltrnsClntFn3EnlCmmnd : 0|2@1+ (1,0) [0|3] "" Vector__XXX
 SG_ PwrEltrnsClntFn3PrntSpdCmmnd : 24|8@1+ (0.5,0) [0|125] "%" Vector__XXX
 SG_ PwrEltrnsClntFn3PwrHld : 2|2@1+ (1,0) [0|3] "" Vector__XXX
 SG_ PwrEltrnsClntFn3SpdCmmnd : 8|16@1+ (0.5,0) [0|32127.5] "rpm" Vector__XXX

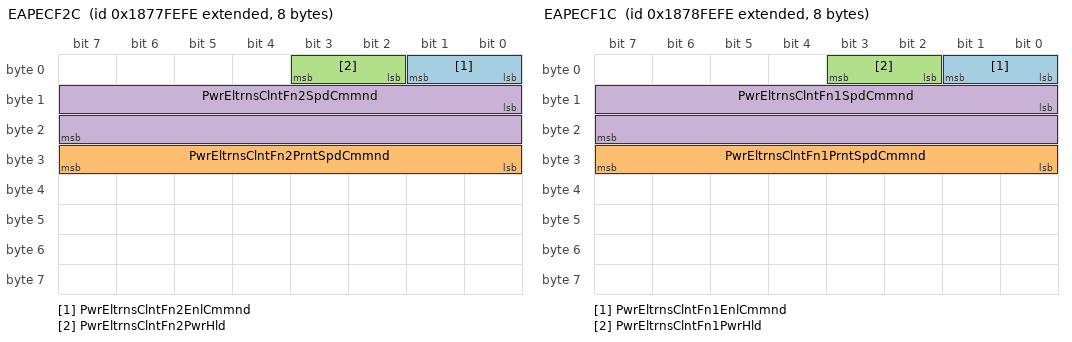
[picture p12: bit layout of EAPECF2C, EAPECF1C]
BO_ 2558000894 EAPECF2C: 8 Vector__XXX
 SG_ PwrEltrnsClntFn2EnlCmmnd : 0|2@1+ (1,0) [0|3] "" Vector__XXX
 SG_ PwrEltrnsClntFn2PrntSpdCmmnd : 24|8@1+ (0.5,0) [0|125] "%" Vector__XXX
 SG_ PwrEltrnsClntFn2PwrHld : 2|2@1+ (1,0) [0|3] "" Vector__XXX
 SG_ PwrEltrnsClntFn2SpdCmmnd : 8|16@1+ (0.5,0) [0|32127.5] "rpm" Vector__XXX

BO_ 2558066430 EAPECF1C: 8 Vector__XXX
 SG_ PwrEltrnsClntFn1EnlCmmnd : 0|2@1+ (1,0) [0|3] "" Vector__XXX
 SG_ PwrEltrnsClntFn1PrntSpdCmmnd : 24|8@1+ (0.5,0) [0|125] "%" Vector__XXX
 SG_ PwrEltrnsClntFn1PwrHld : 2|2@1+ (1,0) [0|3] "" Vector__XXX
 SG_ PwrEltrnsClntFn1SpdCmmnd : 8|16@1+ (0.5,0) [0|32127.5] "rpm" Vector__XXX

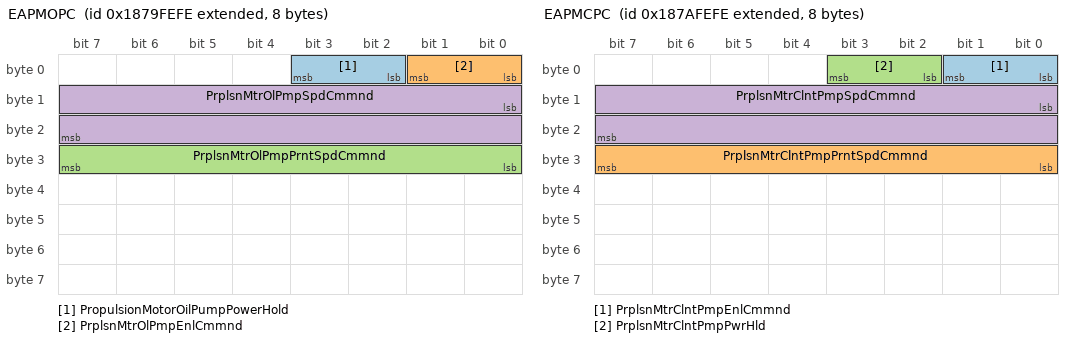
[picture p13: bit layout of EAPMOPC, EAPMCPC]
BO_ 2558131966 EAPMOPC: 8 Vector__XXX
 SG_ PropulsionMotorOilPumpPowerHold : 2|2@1+ (1,0) [0|3] "" Vector__XXX
 SG_ PrplsnMtrOlPmpEnlCmmnd : 0|2@1+ (1,0) [0|3] "" Vector__XXX
 SG_ PrplsnMtrOlPmpPrntSpdCmmnd : 24|8@1+ (0.5,0) [0|125] "%" Vector__XXX
 SG_ PrplsnMtrOlPmpSpdCmmnd : 8|16@1+ (0.5,0) [0|32127.5] "rpm" Vector__XXX

BO_ 2558197502 EAPMCPC: 8 Vector__XXX
 SG_ PrplsnMtrClntPmpEnlCmmnd : 0|2@1+ (1,0) [0|3] "" Vector__XXX
 SG_ PrplsnMtrClntPmpPrntSpdCmmnd : 24|8@1+ (0.5,0) [0|125] "%" Vector__XXX
 SG_ PrplsnMtrClntPmpPwrHld : 2|2@1+ (1,0) [0|3] "" Vector__XXX
 SG_ PrplsnMtrClntPmpSpdCmmnd : 8|16@1+ (0.5,0) [0|32127.5] "rpm" Vector__XXX

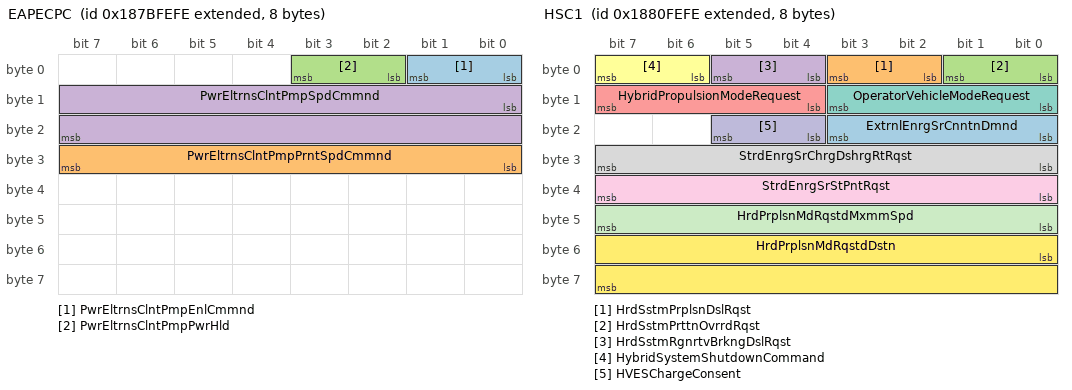
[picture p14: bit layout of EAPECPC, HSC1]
BO_ 2558263038 EAPECPC: 8 Vector__XXX
 SG_ PwrEltrnsClntPmpEnlCmmnd : 0|2@1+ (1,0) [0|3] "" Vector__XXX
 SG_ PwrEltrnsClntPmpPrntSpdCmmnd : 24|8@1+ (0.5,0) [0|125] "%" Vector__XXX
 SG_ PwrEltrnsClntPmpPwrHld : 2|2@1+ (1,0) [0|3] "" Vector__XXX
 SG_ PwrEltrnsClntPmpSpdCmmnd : 8|16@1+ (0.5,0) [0|32127.5] "rpm" Vector__XXX

BO_ 2558394110 EAMC: 8 Vector__XXX
 SG_ EltrfdAssrMtrEnlCmmnd : 0|2@1+ (1,0) [0|3] "" Vector__XXX
 SG_ EltrfdAssrMtrPrntSpdCmmnd : 24|8@1+ (0.5,0) [0|125] "%" Vector__XXX
 SG_ EltrfdAssrMtrPwrHld : 2|2@1+ (1,0) [0|3] "" Vector__XXX
 SG_ EltrfdAssrMtrSpdCmmnd : 8|16@1+ (0.5,0) [0|32127.5] "rpm" Vector__XXX
 SG_ ElectrifiedAccessoryMotor1 : 32|1@1+ (1,0) [0|1] "" Vector__XXX
 SG_ ElectrifiedAccessoryMotor2 : 33|1@1+ (1,0) [0|1] "" Vector__XXX
 SG_ ElectrifiedAccessoryMotor3 : 34|1@1+ (1,0) [0|1] "" Vector__XXX
 SG_ ElectrifiedAccessoryMotor4 : 35|1@1+ (1,0) [0|1] "" Vector__XXX
 SG_ ElectrifiedAccessoryMotor5 : 36|1@1+ (1,0) [0|1] "" Vector__XXX
 SG_ ElectrifiedAccessoryMotor6 : 37|1@1+ (1,0) [0|1] "" Vector__XXX
 SG_ ElectrifiedAccessoryMotor7 : 38|1@1+ (1,0) [0|1] "" Vector__XXX
 SG_ ElectrifiedAccessoryMotor8 : 39|1@1+ (1,0) [0|1] "" Vector__XXX
 SG_ ElectrifiedAccessoryMotor9 : 40|1@1+ (1,0) [0|1] "" Vector__XXX
 SG_ ElectrifiedAccessoryMotor10 : 41|1@1+ (1,0) [0|1] "" Vector__XXX
 SG_ ElectrifiedAccessoryMotor11 : 42|1@1+ (1,0) [0|1] "" Vector__XXX
 SG_ ElectrifiedAccessoryMotor12 : 43|1@1+ (1,0) [0|1] "" Vector__XXX
 SG_ ElectrifiedAccessoryMotor13 : 44|1@1+ (1,0) [0|1] "" Vector__XXX
 SG_ ElectrifiedAccessoryMotor14 : 45|1@1+ (1,0) [0|1] "" Vector__XXX
 SG_ ElectrifiedAccessoryMotor15 : 46|1@1+ (1,0) [0|1] "" Vector__XXX

BO_ 2558459646 ESRRBR: 8 Vector__XXX
 SG_ RqstdEngnSpdAlrtnRtLmt : 0|16@1+ (1,0) [0|64255] "rpm/s" Vector__XXX
 SG_ RqstdEngnSpdDlrtnRtLmt : 16|16@1+ (1,0) [0|64255] "rpm/s" Vector__XXX

BO_ 2558525182 TSIC: 200 Vector__XXX
 SG_ NumberofTireSensors : 0|8@1+ (1,0) [0|250] "count" Vector__XXX
 SG_ TireLocation : 16|8@1+ (8,0) [0|0] "bit-mapped" Vector__XXX
 SG_ TireNumber : 8|8@1+ (1,0) [0|250] "count" Vector__XXX
 SG_ TireSensorIdentificationNumber : 24|8@1+ (1,0) [0|255] "ASCII" Vector__XXX

BO_ 2558590718 HSC1: 8 Vector__XXX
 SG_ ExtrnlEnrgSrCnntnDmnd : 16|4@1+ (1,0) [0|15] "" Vector__XXX
 SG_ HrdSstmPrplsnDslRqst : 2|2@1+ (1,0) [0|3] "" Vector__XXX
 SG_ HrdSstmPrttnOvrrdRqst : 0|2@1+ (1,0) [0|3] "" Vector__XXX
 SG_ HrdSstmRgnrtvBrkngDslRqst : 4|2@1+ (1,0) [0|3] "" Vector__XXX
 SG_ HybridPropulsionModeRequest : 12|4@1+ (1,0) [0|15] "" Vector__XXX
 SG_ HybridSystemShutdownCommand : 6|2@1+ (1,0) [0|3] "" Vector__XXX
 SG_ OperatorVehicleModeRequest : 8|4@1+ (1,0) [0|15] "" Vector__XXX
 SG_ StrdEnrgSrChrgDshrgRtRqst : 24|8@1+ (0.4,0) [0|100] "%" Vector__XXX
 SG_ StrdEnrgSrStPntRqst : 32|8@1+ (0.4,0) [0|100] "%" Vector__XXX
 SG_ HVESChargeConsent : 20|2@1+ (1,0) [0|3] "" Vector__XXX
 SG_ HrdPrplsnMdRqstdMxmmSpd : 40|8@1+ (1,0) [0|250] "km/h" Vector__XXX
 SG_ HrdPrplsnMdRqstdDstn : 48|16@1+ (0.03125,0) [0|2007.96875] "km" Vector__XXX

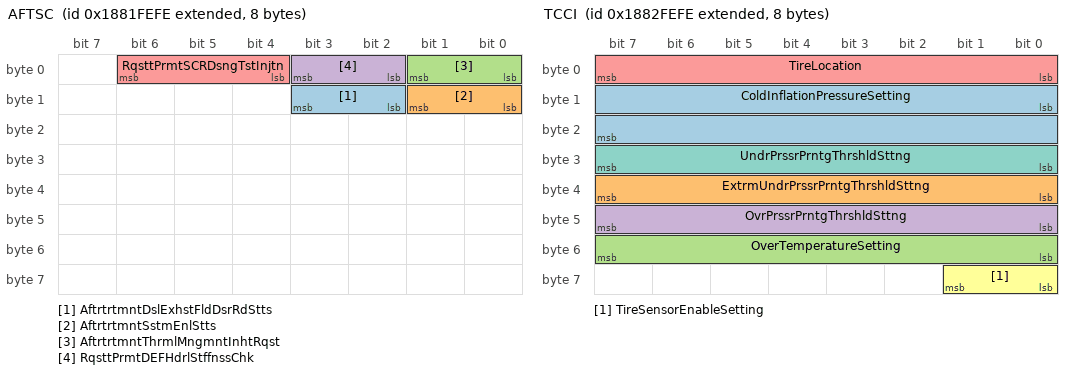
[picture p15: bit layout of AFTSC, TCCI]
BO_ 2558656254 AFTSC: 8 Vector__XXX
 SG_ AftrtrtmntDslExhstFldDsrRdStts : 10|2@1+ (1,0) [0|3] "" Vector__XXX
 SG_ AftrtrtmntSstmEnlStts : 8|2@1+ (1,0) [0|3] "" Vector__XXX
 SG_ AftrtrtmntThrmlMngmntInhtRqst : 0|2@1+ (1,0) [0|3] "" Vector__XXX
 SG_ RqsttPrmtDEFHdrlStffnssChk : 2|2@1+ (1,0) [0|3] "" Vector__XXX
 SG_ RqsttPrmtSCRDsngTstInjtn : 4|3@1+ (1,0) [0|7] "" Vector__XXX

BO_ 2558721790 TCCI: 8 Vector__XXX
 SG_ ColdInflationPressureSetting : 8|16@1+ (1,0) [0|64255] "kPa" Vector__XXX
 SG_ ExtrmUndrPrssrPrntgThrshldSttng : 32|8@1+ (0.5,0) [0|125] "%" Vector__XXX
 SG_ OverTemperatureSetting : 48|8@1+ (1,-40) [-40|210] "degC" Vector__XXX
 SG_ OvrPrssrPrntgThrshldSttng : 40|8@1+ (0.5,0) [0|125] "%" Vector__XXX
 SG_ TireLocation : 0|8@1+ (8,0) [0|0] "bit-mapped" Vector__XXX
 SG_ TireSensorEnableSetting : 56|2@1+ (1,0) [0|3] "" Vector__XXX
 SG_ UndrPrssrPrntgThrshldSttng : 24|8@1+ (0.5,0) [0|125] "%" Vector__XXX

BO_ 2558787326 PCIC: 8 Vector__XXX
 SG_ PayloadCorrectionFactorCommand : 24|8@1+ (1,-125) [-125|125] "%" Vector__XXX
 SG_ PldClrtnCmmnddWght : 8|16@1+ (2,0) [0|128510] "kg" Vector__XXX
 SG_ PldClrtnStPntCmmnd : 0|4@1+ (1,0) [0|15] "" Vector__XXX

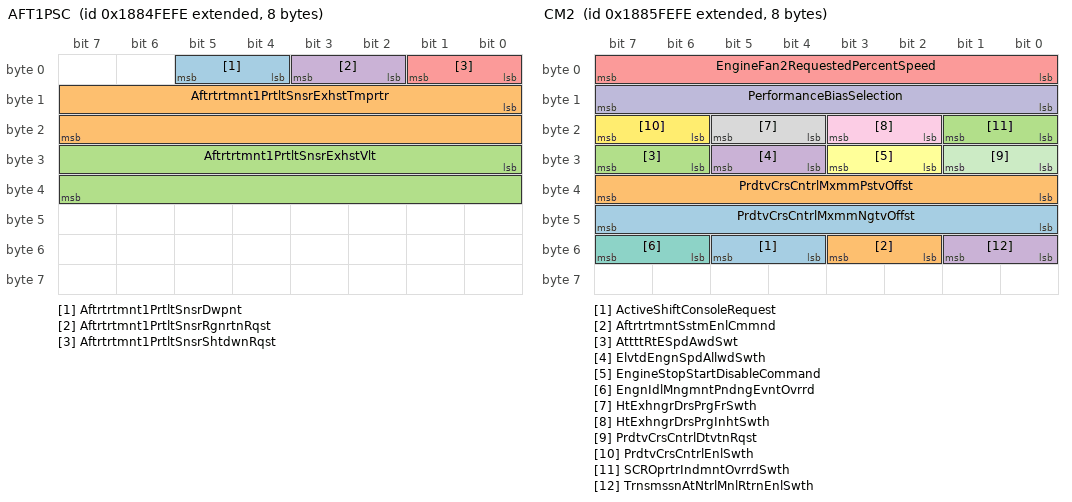
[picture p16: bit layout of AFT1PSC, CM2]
BO_ 2558852862 AFT1PSC: 8 Vector__XXX
 SG_ Aftrtrtmnt1PrtltSnsrDwpnt : 4|2@1+ (1,0) [0|3] "" Vector__XXX
 SG_ Aftrtrtmnt1PrtltSnsrExhstTmprtr : 8|16@1+ (0.03125,-273) [-273|1734.96875] "degC" Vector__XXX
 SG_ Aftrtrtmnt1PrtltSnsrExhstVlt : 24|16@1+ (0.00390625,0) [0|250.996] "km/h" Vector__XXX
 SG_ Aftrtrtmnt1PrtltSnsrRgnrtnRqst : 2|2@1+ (1,0) [0|3] "" Vector__XXX
 SG_ Aftrtrtmnt1PrtltSnsrShtdwnRqst : 0|2@1+ (1,0) [0|3] "" Vector__XXX

BO_ 2558918398 CM2: 8 Vector__XXX
 SG_ ActiveShiftConsoleRequest : 52|2@1+ (1,0) [0|3] "" Vector__XXX
 SG_ AftrtrtmntSstmEnlCmmnd : 50|2@1+ (1,0) [0|3] "" Vector__XXX
 SG_ AttttRtESpdAwdSwt : 30|2@1+ (1,0) [0|3] "" Vector__XXX
 SG_ ElvtdEngnSpdAllwdSwth : 28|2@1+ (1,0) [0|3] "" Vector__XXX
 SG_ EngineFan2RequestedPercentSpeed : 0|8@1+ (0.4,0) [0|100] "%" Vector__XXX
 SG_ EngineStopStartDisableCommand : 26|2@1+ (1,0) [0|3] "" Vector__XXX
 SG_ EngnIdlMngmntPndngEvntOvrrd : 54|2@1+ (1,0) [0|3] "" Vector__XXX
 SG_ HtExhngrDrsPrgFrSwth : 20|2@1+ (1,0) [0|3] "" Vector__XXX
 SG_ HtExhngrDrsPrgInhtSwth : 18|2@1+ (1,0) [0|3] "" Vector__XXX
 SG_ PerformanceBiasSelection : 8|8@1+ (0.4,0) [0|100] "%" Vector__XXX
 SG_ PrdtvCrsCntrlDtvtnRqst : 24|2@1+ (1,0) [0|3] "" Vector__XXX
 SG_ PrdtvCrsCntrlEnlSwth : 22|2@1+ (1,0) [0|3] "" Vector__XXX
 SG_ PrdtvCrsCntrlMxmmNgtvOffst : 40|8@1+ (0.125,-31.25) [-31.25|0] "km/h" Vector__XXX
 SG_ PrdtvCrsCntrlMxmmPstvOffst : 32|8@1+ (0.125,0) [0|31.25] "km/h" Vector__XXX
 SG_ SCROprtrIndmntOvrrdSwth : 16|2@1+ (1,0) [0|3] "" Vector__XXX
 SG_ TrnsmssnAtNtrlMnlRtrnEnlSwth : 48|2@1+ (1,0) [0|3] "" Vector__XXX

BO_ 2558983934 SPOC: 8 Vector__XXX
 SG_ SwitchedPowerOutput10Command : 20|2@1+ (1,0) [0|3] "" Vector__XXX
 SG_ SwitchedPowerOutput11Command : 18|2@1+ (1,0) [0|3] "" Vector__XXX
 SG_ SwitchedPowerOutput12Command : 16|2@1+ (1,0) [0|3] "" Vector__XXX
 SG_ SwitchedPowerOutput13Command : 30|2@1+ (1,0) [0|3] "" Vector__XXX
 SG_ SwitchedPowerOutput14Command : 28|2@1+ (1,0) [0|3] "" Vector__XXX
 SG_ SwitchedPowerOutput15Command : 26|2@1+ (1,0) [0|3] "" Vector__XXX
 SG_ SwitchedPowerOutput16Command : 24|2@1+ (1,0) [0|3] "" Vector__XXX
 SG_ SwitchedPowerOutput17Command : 38|2@1+ (1,0) [0|3] "" Vector__XXX
 SG_ SwitchedPowerOutput18Command : 36|2@1+ (1,0) [0|3] "" Vector__XXX
 SG_ SwitchedPowerOutput19Command : 34|2@1+ (1,0) [0|3] "" Vector__XXX
 SG_ SwitchedPowerOutput1Command : 6|2@1+ (1,0) [0|3] "" Vector__XXX
 SG_ SwitchedPowerOutput20Command : 32|2@1+ (1,0) [0|3] "" Vector__XXX
 SG_ SwitchedPowerOutput21Command : 46|2@1+ (1,0) [0|3] "" Vector__XXX
 SG_ SwitchedPowerOutput22Command : 44|2@1+ (1,0) [0|3] "" Vector__XXX
 SG_ SwitchedPowerOutput23Command : 42|2@1+ (1,0) [0|3] "" Vector__XXX
 SG_ SwitchedPowerOutput24Command : 40|2@1+ (1,0) [0|3] "" Vector__XXX
 SG_ SwitchedPowerOutput25Command : 54|2@1+ (1,0) [0|3] "" Vector__XXX
 SG_ SwitchedPowerOutput26Command : 52|2@1+ (1,0) [0|3] "" Vector__XXX
 SG_ SwitchedPowerOutput27Command : 50|2@1+ (1,0) [0|3] "" Vector__XXX
 SG_ SwitchedPowerOutput28Command : 48|2@1+ (1,0) [0|3] "" Vector__XXX
 SG_ SwitchedPowerOutput29Command : 62|2@1+ (1,0) [0|3] "" Vector__XXX
 SG_ SwitchedPowerOutput2Command : 4|2@1+ (1,0) [0|3] "" Vector__XXX
 SG_ SwitchedPowerOutput30Command : 60|2@1+ (1,0) [0|3] "" Vector__XXX
 SG_ SwitchedPowerOutput31Command : 58|2@1+ (1,0) [0|3] "" Vector__XXX
 SG_ SwitchedPowerOutput32Command : 56|2@1+ (1,0) [0|3] "" Vector__XXX
 SG_ SwitchedPowerOutput3Command : 2|2@1+ (1,0) [0|3] "" Vector__XXX
 SG_ SwitchedPowerOutput4Command : 0|2@1+ (1,0) [0|3] "" Vector__XXX
 SG_ SwitchedPowerOutput5Command : 14|2@1+ (1,0) [0|3] "" Vector__XXX
 SG_ SwitchedPowerOutput6Command : 12|2@1+ (1,0) [0|3] "" Vector__XXX
 SG_ SwitchedPowerOutput7Command : 10|2@1+ (1,0) [0|3] "" Vector__XXX
 SG_ SwitchedPowerOutput8Command : 8|2@1+ (1,0) [0|3] "" Vector__XXX
 SG_ SwitchedPowerOutput9Command : 22|2@1+ (1,0) [0|3] "" Vector__XXX

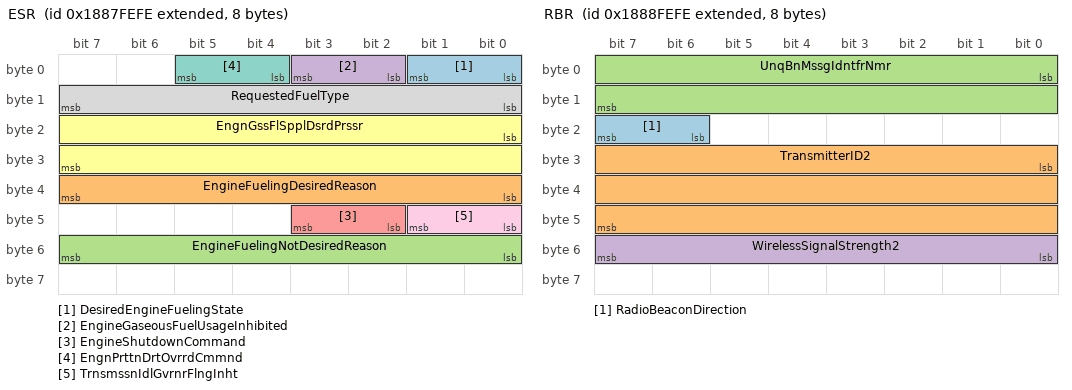
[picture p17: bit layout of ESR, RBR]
BO_ 2559049470 ESR: 8 Vector__XXX
 SG_ DesiredEngineFuelingState : 0|2@1+ (1,0) [0|3] "" Vector__XXX
 SG_ EngineFuelingDesiredReason : 32|8@1+ (1,0) [0|255] "" Vector__XXX
 SG_ EngineFuelingNotDesiredReason : 48|8@1+ (1,0) [0|255] "" Vector__XXX
 SG_ EngineGaseousFuelUsageInhibited : 2|2@1+ (1,0) [0|3] "" Vector__XXX
 SG_ EngineShutdownCommand : 42|2@1+ (1,0) [0|3] "" Vector__XXX
 SG_ EngnGssFlSpplDsrdPrssr : 16|16@1+ (0.5,0) [0|32127.5] "kPa" Vector__XXX
 SG_ EngnPrttnDrtOvrrdCmmnd : 4|2@1+ (1,0) [0|3] "" Vector__XXX
 SG_ RequestedFuelType : 8|8@1+ (1,0) [0|255] "" Vector__XXX
 SG_ TrnsmssnIdlGvrnrFlngInht : 40|2@1+ (1,0) [0|3] "" Vector__XXX

BO_ 2559115006 RBR: 8 Vector__XXX
 SG_ RadioBeaconDirection : 22|2@1+ (1,0) [0|3] "" Vector__XXX
 SG_ TransmitterID2 : 24|24@1+ (1,0) [0|1.64496E+07] "ID" Vector__XXX
 SG_ UnqBnMssgIdntfrNmr : 0|16@1+ (1,0) [0|64255] "count" Vector__XXX
 SG_ WirelessSignalStrength2 : 48|8@1+ (0.5,-125) [-125|0] "dBm" Vector__XXX

BO_ 2559573758 ECC: 8 Vector__XXX
 SG_ CtLvEPttStdwOvdCd : 0|2@1+ (1,0) [0|3] "" Vector__XXX

BO_ 2559639294 SFC: 8 Vector__XXX
 SG_ SupplementalFanDirectionCommand : 2|2@1+ (1,0) [0|3] "" Vector__XXX
 SG_ SupplementalFanEnableCommand : 0|2@1+ (1,0) [0|3] "" Vector__XXX
 SG_ SupplementalFanPowerHold : 24|2@1+ (1,0) [0|3] "" Vector__XXX
 SG_ SupplementalFanSpeedCommand : 8|16@1+ (0.5,0) [0|32127.5] "rpm" Vector__XXX

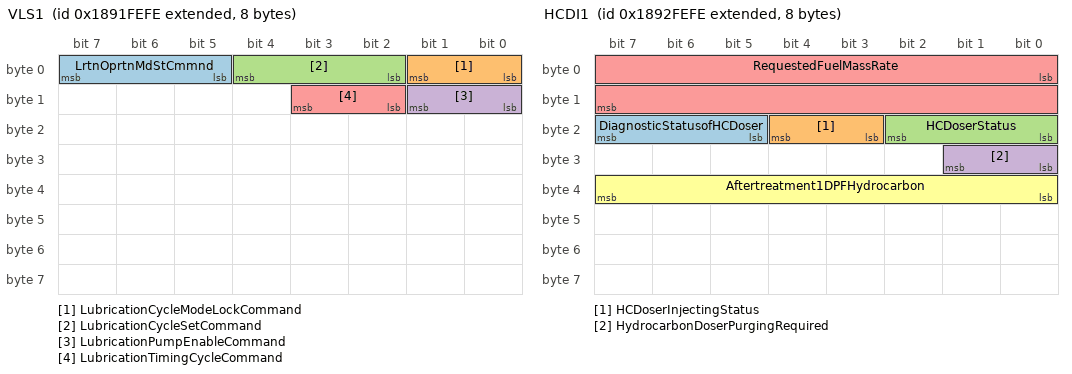
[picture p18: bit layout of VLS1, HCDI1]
BO_ 2559704830 VLS1: 8 Vector__XXX
 SG_ LrtnOprtnMdStCmmnd : 5|3@1+ (1,0) [0|7] "" Vector__XXX
 SG_ LubricationCycleModeLockCommand : 0|2@1+ (1,0) [0|3] "" Vector__XXX
 SG_ LubricationCycleSetCommand : 2|3@1+ (1,0) [0|7] "" Vector__XXX
 SG_ LubricationPumpEnableCommand : 8|2@1+ (1,0) [0|3] "" Vector__XXX
 SG_ LubricationTimingCycleCommand : 10|2@1+ (1,0) [0|3] "" Vector__XXX

BO_ 2559770366 HCDI1: 8 Vector__XXX
 SG_ DiagnosticStatusofHCDoser : 21|3@1+ (1,0) [0|7] "" Vector__XXX
 SG_ HCDoserInjectingStatus : 19|2@1+ (1,0) [0|3] "" Vector__XXX
 SG_ HCDoserStatus : 16|3@1+ (1,0) [0|7] "" Vector__XXX
 SG_ HydrocarbonDoserPurgingRequired : 24|2@1+ (1,0) [0|3] "" Vector__XXX
 SG_ RequestedFuelMassRate : 0|16@1+ (0.05,0) [0|3212.75] "g/min" Vector__XXX
 SG_ Aftertreatment1DPFHydrocarbon : 32|8@1+ (0.5,0) [0|125] "%" Vector__XXX

BO_ 2559901438 AT1DPFSSC: 8 Vector__XXX
 SG_ Atttt1DsPttFtStMCtOst : 0|16@1+ (0.0025,0) [0|160.6375] "%" Vector__XXX
 SG_ Atttt1DsPttFtStStddDvtCtOst : 16|16@1+ (0.0025,0) [0|160.6375] "%" Vector__XXX

BO_ 2559966974 AT2DPFSSC: 8 Vector__XXX
 SG_ Atttt2DsPttFtStMCtOst : 0|16@1+ (0.0025,0) [0|160.6375] "%" Vector__XXX
 SG_ Atttt2DsPttFtStStddDvtCtOst : 16|16@1+ (0.0025,0) [0|160.6375] "%" Vector__XXX

BO_ 2560032510 LVDSOM: 8 Vector__XXX
 SG_ LwVltgDsnntDsrdOprtngMd : 0|4@1+ (1,0) [0|15] "" Vector__XXX

BO_ 2560098046 NCS: 8 Vector__XXX
 SG_ CabNoiseControlStatus : 0|2@1+ (1,0) [0|3] "" Vector__XXX
 SG_ CabNoiseControlTuningStatus : 2|4@1+ (1,0) [0|15] "" Vector__XXX

BO_ 2560163582 NC1: 8 Vector__XXX
 SG_ CabNoiseControlCommand : 0|2@1+ (1,0) [0|3] "" Vector__XXX
 SG_ CabNoiseControlTuningCommand : 2|3@1+ (1,0) [0|7] "" Vector__XXX

BO_ 2560360190 PMI: 8 Vector__XXX
 SG_ DataDictionaryManufacturerCode : 0|11@1+ (1,0) [0|2047] "" Vector__XXX
 SG_ DataDictionaryMethod : 11|21@1+ (1,0) [0|2.09715E+06] "" Vector__XXX

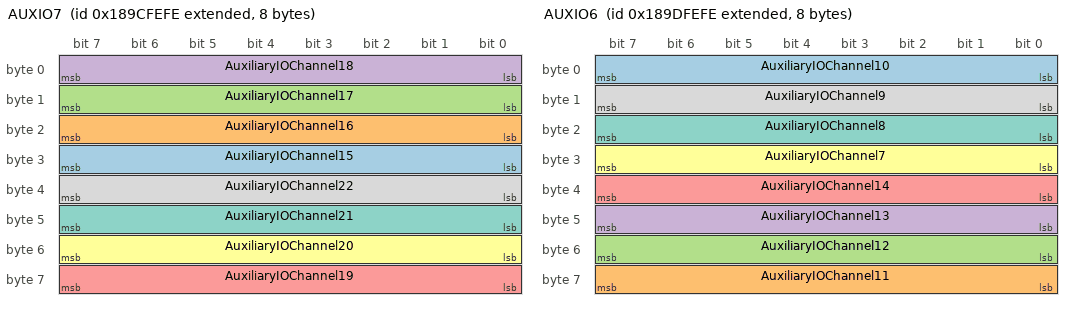
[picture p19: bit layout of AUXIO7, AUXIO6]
BO_ 2560425726 AUXIO7: 8 Vector__XXX
 SG_ AuxiliaryIOChannel15 : 24|8@1+ (1,0) [0|250] "count" Vector__XXX
 SG_ AuxiliaryIOChannel16 : 16|8@1+ (1,0) [0|250] "count" Vector__XXX
 SG_ AuxiliaryIOChannel17 : 8|8@1+ (1,0) [0|250] "count" Vector__XXX
 SG_ AuxiliaryIOChannel18 : 0|8@1+ (1,0) [0|250] "count" Vector__XXX
 SG_ AuxiliaryIOChannel19 : 56|8@1+ (1,0) [0|250] "count" Vector__XXX
 SG_ AuxiliaryIOChannel20 : 48|8@1+ (1,0) [0|250] "count" Vector__XXX
 SG_ AuxiliaryIOChannel21 : 40|8@1+ (1,0) [0|250] "count" Vector__XXX
 SG_ AuxiliaryIOChannel22 : 32|8@1+ (1,0) [0|250] "count" Vector__XXX

BO_ 2560491262 AUXIO6: 8 Vector__XXX
 SG_ AuxiliaryIOChannel10 : 0|8@1+ (1,0) [0|250] "count" Vector__XXX
 SG_ AuxiliaryIOChannel11 : 56|8@1+ (1,0) [0|250] "count" Vector__XXX
 SG_ AuxiliaryIOChannel12 : 48|8@1+ (1,0) [0|250] "count" Vector__XXX
 SG_ AuxiliaryIOChannel13 : 40|8@1+ (1,0) [0|250] "count" Vector__XXX
 SG_ AuxiliaryIOChannel14 : 32|8@1+ (1,0) [0|250] "count" Vector__XXX
 SG_ AuxiliaryIOChannel7 : 24|8@1+ (1,0) [0|250] "count" Vector__XXX
 SG_ AuxiliaryIOChannel8 : 16|8@1+ (1,0) [0|250] "count" Vector__XXX
 SG_ AuxiliaryIOChannel9 : 8|8@1+ (1,0) [0|250] "count" Vector__XXX

BO_ 2561015550 AUXIO4: 8 Vector__XXX
 SG_ AuxiliaryIO100 : 32|2@1+ (1,0) [0|3] "" Vector__XXX
 SG_ AuxiliaryIO101 : 46|2@1+ (1,0) [0|3] "" Vector__XXX
 SG_ AuxiliaryIO102 : 44|2@1+ (1,0) [0|3] "" Vector__XXX
 SG_ AuxiliaryIO103 : 42|2@1+ (1,0) [0|3] "" Vector__XXX
 SG_ AuxiliaryIO104 : 40|2@1+ (1,0) [0|3] "" Vector__XXX
 SG_ AuxiliaryIO105 : 54|2@1+ (1,0) [0|3] "" Vector__XXX
 SG_ AuxiliaryIO106 : 52|2@1+ (1,0) [0|3] "" Vector__XXX
 SG_ AuxiliaryIO107 : 50|2@1+ (1,0) [0|3] "" Vector__XXX
 SG_ AuxiliaryIO108 : 48|2@1+ (1,0) [0|3] "" Vector__XXX
 SG_ AuxiliaryIO109 : 62|2@1+ (1,0) [0|3] "" Vector__XXX
 SG_ AuxiliaryIO110 : 60|2@1+ (1,0) [0|3] "" Vector__XXX
 SG_ AuxiliaryIO111 : 58|2@1+ (1,0) [0|3] "" Vector__XXX
 SG_ AuxiliaryIO112 : 56|2@1+ (1,0) [0|3] "" Vector__XXX
 SG_ AuxiliaryIO81 : 6|2@1+ (1,0) [0|3] "" Vector__XXX
 SG_ AuxiliaryIO82 : 4|2@1+ (1,0) [0|3] "" Vector__XXX
 SG_ AuxiliaryIO83 : 2|2@1+ (1,0) [0|3] "" Vector__XXX
 SG_ AuxiliaryIO84 : 0|2@1+ (1,0) [0|3] "" Vector__XXX
 SG_ AuxiliaryIO85 : 14|2@1+ (1,0) [0|3] "" Vector__XXX
 SG_ AuxiliaryIO86 : 12|2@1+ (1,0) [0|3] "" Vector__XXX
 SG_ AuxiliaryIO87 : 10|2@1+ (1,0) [0|3] "" Vector__XXX
 SG_ AuxiliaryIO88 : 8|2@1+ (1,0) [0|3] "" Vector__XXX
 SG_ AuxiliaryIO89 : 22|2@1+ (1,0) [0|3] "" Vector__XXX
 SG_ AuxiliaryIO90 : 20|2@1+ (1,0) [0|3] "" Vector__XXX
 SG_ AuxiliaryIO91 : 18|2@1+ (1,0) [0|3] "" Vector__XXX
 SG_ AuxiliaryIO92 : 16|2@1+ (1,0) [0|3] "" Vector__XXX
 SG_ AuxiliaryIO93 : 30|2@1+ (1,0) [0|3] "" Vector__XXX
 SG_ AuxiliaryIO94 : 28|2@1+ (1,0) [0|3] "" Vector__XXX
 SG_ AuxiliaryIO95 : 26|2@1+ (1,0) [0|3] "" Vector__XXX
 SG_ AuxiliaryIO96 : 24|2@1+ (1,0) [0|3] "" Vector__XXX
 SG_ AuxiliaryIO97 : 38|2@1+ (1,0) [0|3] "" Vector__XXX
 SG_ AuxiliaryIO98 : 36|2@1+ (1,0) [0|3] "" Vector__XXX
 SG_ AuxiliaryIO99 : 34|2@1+ (1,0) [0|3] "" Vector__XXX

BO_ 2561081086 AUXIO3: 8 Vector__XXX
 SG_ AuxiliaryIO49 : 6|2@1+ (1,0) [0|3] "" Vector__XXX
 SG_ AuxiliaryIO50 : 4|2@1+ (1,0) [0|3] "" Vector__XXX
 SG_ AuxiliaryIO51 : 2|2@1+ (1,0) [0|3] "" Vector__XXX
 SG_ AuxiliaryIO52 : 0|2@1+ (1,0) [0|3] "" Vector__XXX
 SG_ AuxiliaryIO53 : 14|2@1+ (1,0) [0|3] "" Vector__XXX
 SG_ AuxiliaryIO54 : 12|2@1+ (1,0) [0|3] "" Vector__XXX
 SG_ AuxiliaryIO55 : 10|2@1+ (1,0) [0|3] "" Vector__XXX
 SG_ AuxiliaryIO56 : 8|2@1+ (1,0) [0|3] "" Vector__XXX
 SG_ AuxiliaryIO57 : 22|2@1+ (1,0) [0|3] "" Vector__XXX
 SG_ AuxiliaryIO58 : 20|2@1+ (1,0) [0|3] "" Vector__XXX
 SG_ AuxiliaryIO59 : 18|2@1+ (1,0) [0|3] "" Vector__XXX
 SG_ AuxiliaryIO60 : 16|2@1+ (1,0) [0|3] "" Vector__XXX
 SG_ AuxiliaryIO61 : 30|2@1+ (1,0) [0|3] "" Vector__XXX
 SG_ AuxiliaryIO62 : 28|2@1+ (1,0) [0|3] "" Vector__XXX
 SG_ AuxiliaryIO63 : 26|2@1+ (1,0) [0|3] "" Vector__XXX
 SG_ AuxiliaryIO64 : 24|2@1+ (1,0) [0|3] "" Vector__XXX
 SG_ AuxiliaryIO65 : 38|2@1+ (1,0) [0|3] "" Vector__XXX
 SG_ AuxiliaryIO66 : 36|2@1+ (1,0) [0|3] "" Vector__XXX
 SG_ AuxiliaryIO67 : 34|2@1+ (1,0) [0|3] "" Vector__XXX
 SG_ AuxiliaryIO68 : 32|2@1+ (1,0) [0|3] "" Vector__XXX
 SG_ AuxiliaryIO69 : 46|2@1+ (1,0) [0|3] "" Vector__XXX
 SG_ AuxiliaryIO70 : 44|2@1+ (1,0) [0|3] "" Vector__XXX
 SG_ AuxiliaryIO71 : 42|2@1+ (1,0) [0|3] "" Vector__XXX
 SG_ AuxiliaryIO72 : 40|2@1+ (1,0) [0|3] "" Vector__XXX
 SG_ AuxiliaryIO73 : 54|2@1+ (1,0) [0|3] "" Vector__XXX
 SG_ AuxiliaryIO74 : 52|2@1+ (1,0) [0|3] "" Vector__XXX
 SG_ AuxiliaryIO75 : 50|2@1+ (1,0) [0|3] "" Vector__XXX
 SG_ AuxiliaryIO76 : 48|2@1+ (1,0) [0|3] "" Vector__XXX
 SG_ AuxiliaryIO77 : 62|2@1+ (1,0) [0|3] "" Vector__XXX
 SG_ AuxiliaryIO78 : 60|2@1+ (1,0) [0|3] "" Vector__XXX
 SG_ AuxiliaryIO79 : 58|2@1+ (1,0) [0|3] "" Vector__XXX
 SG_ AuxiliaryIO80 : 56|2@1+ (1,0) [0|3] "" Vector__XXX

CM_ BO_ 2432541694 "Electronic Engine Controller 6";
CM_ SG_ 2432541694 EngnTrhrgrCmprssrBpssAttr1Cmmnd "The command to a compressor bypass actuator, normalized to percent, where 0% nominally represents fully closed and 100% represents fully open.  Typically, the t…";
CM_ SG_ 2432541694 EngnTrhrgrCmprssrBpssAttr1Pstn "Measures the position of the turbocharger compressor bypass actuator, where 0% represents bypass fully closed and 100% represents bypass fully open.  Typically,…";
CM_ SG_ 2432541694 EngnTrhrgrCmprssrBpssAttr2Cmmnd "The command to a compressor bypass actuator 2, normalized to percent, where 0% nominally represents fully closed and 100% represents fully open. Typically, the …";
CM_ SG_ 2432541694 EngnVrlGmtrTrhrgrAttr1 "Actuator that controls the variable geometry turbocharger geometry.The control command to the actuator, normalized to percent, where 0% nominally represents ful…";
CM_ SG_ 2432541694 ETCpssBpssAtt1DsdPst "The requested position of the Engine Turbocharger Compressor Bypass actuator by the engine ECU, where 0% represents bypass fully closed and 100% represents bypa…";
CM_ SG_ 2432541694 ETCpssBpssAtt1PFMI "Used to identify the applicable J1939-73 FMI detected in the Engine Turbocharger Compressor Bypass Actuator 1 by the manufacturers software.  When there is mult…";
CM_ SG_ 2432541694 ETCpssBpssAtt1TptStts "Used to identify the status of the Engine Turbocharger Compresssor Bypass Actuator 1 drive circuitry temperature.  Temperature excursions may affect the torque …";
CM_ BO_ 2432593918 "Adaptive Cruise Control 1";
CM_ SG_ 2432593918 ACCDistanceAlertSignal "Signal to indicate to the operator that the ACC system is not able to maintain the distance to the target. Example: Target stopping rapidly. This signal may be …";
CM_ SG_ 2432593918 ACCSystemShutoffWarning "Signal to warn the driver of system deactivation due to non-driver actions. Example: Attempting to control vehicle speed below or above limits of ACC. This sign…";
CM_ SG_ 2432593918 ACCTargetDetected "Signal to indicate to the driver that the ACC system has detected a target. 00b = No targets detected01b = Target detected10b = Reserved11b = Take no action…";
CM_ SG_ 2432593918 AdaptiveCruiseControlMode "This parameter is used to indicate the current state, or mode, of operation by the Adaptive Cruise Control (ACC) device. The states characterize independent sys…";
CM_ SG_ 2432593918 AdaptiveCruiseControlSetSpeed "Value of the desired (chosen) velocity of the adaptive cruise control system.…";
CM_ SG_ 2432593918 Adptvrsntrlstdstnmd "Selected distance mode for adaptive cruise control. 000b = ACC Distance mode #1 (largest distance)001b = ACC Distance mode #2010b = ACC Distance mode #3011b = A…";
CM_ SG_ 2432593918 Distancetoforwardvehicle "Distance to the preceding vehicle situated within 250 m in the same lane and moving in the same direction.…";
CM_ SG_ 2432593918 ForwardCollisionWarning "This parameter indicates if a collision is imminent and strong driver reaction either by braking hard or by an avoidance maneuver are imperative to prevent a co…";
CM_ SG_ 2432593918 Roadcurvature "Estimated value of the current road curvature for use by the adaptive cruise control system.  Positive values are used for left curves.  Curvature is the invers…";
CM_ SG_ 2432593918 Speedofforwardvehicle "Absolute velocity of the preceding vehicle situated within 250 m in the same lane and moving in the same direction.…";
CM_ BO_ 2432595710 "Laser Leveling System Vertical Position Display Data";
CM_ SG_ 2432595710 DisplayDeadbands "Sets Display Deadbands mode.0000b = Narrow = +/- 4.5mm0001b = Standard = +/- 12mm0010b = Wide = +/- 24mm0011b to 1110b = Reserved1111b = Not Available…";
CM_ SG_ 2432595710 LEDDisplayData1 "Informs display devices how to display the current vertical position.Values which are less than 128 decimal are bit-mapped values and any combination of these v…";
CM_ SG_ 2432595710 LEDDisplayDeadbandControl "This parameter informs the system what the selected Display deadband will be.0000b = +/- 4.5 mm  (0.015 feet, 0.18 inches)0001b = +/- 12 mm   (0.040 feet, 0.45 …";
CM_ SG_ 2432595710 LEDDisplayModeControl "This parameter informs the system what the selected Display mode will be.0000b = Center On-Grade Display Mode 1 ( 5 CHANNEL )0001b = Offset On-Grade Display Mod…";
CM_ SG_ 2432595710 LEDPatternControl "Sets LED Pattern control mode on laser leveling systems.0000b = 5 Channel0001b = Offset0010b = 7 Channel0011b to 1110b = Reserved1111b = Not Available…";
CM_ BO_ 2498776830 "Engine Cylinder 1 Combustion Average Information";
CM_ SG_ 2498776830 EngnClndr1AvrgCmstnDrtn "Average duration of combustion calculated over defined number of combustion cycles for engine cylinder 1 with reference to the crank angle.  Combustion duration…";
CM_ SG_ 2498776830 EngnClndr1AvrgCntrfCmstnTmng "Average timing calculated over defined number of combustion cycles for the center of combustion in engine cylinder 1 with reference to the crank angle.  Center …";
CM_ SG_ 2498776830 EngnClndr1AvrgStrtfCmstnTmng "Average start of combustion timing calculated over defined number of combustion cycles for engine cylinder 1 with reference to the crank angle.  When the combus…";
CM_ SG_ 2498776830 EngnClndr1IndtdMnEfftvPrssr "Average cylinder pressure calculated over defined number of combustion cycles for engine cylinder 1.   Negative range is to cover thermodynamic behavior during …";
CM_ BO_ 2498777086 "Engine Cylinder 2 Combustion Average Information";
CM_ SG_ 2498777086 EngnClndr2AvrgCmstnDrtn "Average duration of combustion calculated over defined number of combustion cycles for engine cylinder 2 with reference to the crank angle.  Combustion duration…";
CM_ SG_ 2498777086 EngnClndr2AvrgCntrfCmstnTmng "Average timing calculated over defined number of combustion cycles for the center of combustion in engine cylinder 2 with reference to the crank angle.  Center …";
CM_ SG_ 2498777086 EngnClndr2AvrgStrtfCmstnTmng "Average start of combustion timing calculated over defined number of combustion cycles for engine cylinder 2 with reference to the crank angle.  When the combus…";
CM_ SG_ 2498777086 EngnClndr2IndtdMnEfftvPrssr "Average cylinder pressure calculated over defined number of combustion cycles for engine cylinder 2.  Negative range is to cover thermodynamic behavior during m…";
CM_ BO_ 2498777342 "Engine Cylinder 3 Combustion Average Information";
CM_ SG_ 2498777342 EngnClndr3AvrgCmstnDrtn "Average duration of combustion calculated over defined number of combustion cycles for engine cylinder 3 with reference to the crank angle.  Combustion duration…";
CM_ SG_ 2498777342 EngnClndr3AvrgCntrfCmstnTmng "Average timing calculated over defined number of combustion cycles for the center of combustion in engine cylinder 3 with reference to the crank angle.  Center …";
CM_ SG_ 2498777342 EngnClndr3AvrgStrtfCmstnTmng "Average start of combustion timing calculated over defined number of combustion cycles for engine cylinder 3 with reference to the crank angle.  When the combus…";
CM_ SG_ 2498777342 EngnClndr3IndtdMnEfftvPrssr "Average cylinder pressure calculated over defined number of combustion cycles for engine cylinder 3.  Negative range is to cover thermodynamic behavior during m…";
CM_ BO_ 2498777598 "Engine Cylinder 4 Combustion Average Information";
CM_ SG_ 2498777598 EngnClndr4AvrgCmstnDrtn "Average duration of combustion calculated over defined number of combustion cycles for engine cylinder 4 with reference to the crank angle.  Combustion duration…";
CM_ SG_ 2498777598 EngnClndr4AvrgCntrfCmstnTmng "Average timing calculated over defined number of combustion cycles for the center of combustion in engine cylinder 4 with reference to the crank angle.  Center …";
CM_ SG_ 2498777598 EngnClndr4AvrgStrtfCmstnTmng "Average start of combustion timing calculated over defined number of combustion cycles for engine cylinder 4 with reference to the crank angle.  When the combus…";
CM_ SG_ 2498777598 EngnClndr4IndtdMnEfftvPrssr "Average cylinder pressure calculated over defined number of combustion cycles for engine cylinder 4.  Negative range is to cover thermodynamic behavior during m…";
CM_ BO_ 2498777854 "Engine Cylinder 5 Combustion Average Information";
CM_ SG_ 2498777854 EngnClndr5AvrgCmstnDrtn "Average duration of combustion calculated over defined number of combustion cycles for engine cylinder 5 with reference to the crank angle.  Combustion duration…";
CM_ SG_ 2498777854 EngnClndr5AvrgCntrfCmstnTmng "Average timing calculated over defined number of combustion cycles for the center of combustion in engine cylinder 5 with reference to the crank angle.  Center …";
CM_ SG_ 2498777854 EngnClndr5AvrgStrtfCmstnTmng "Average start of combustion timing calculated over defined number of combustion cycles for engine cylinder 5 with reference to the crank angle.  When the combus…";
CM_ SG_ 2498777854 EngnClndr5IndtdMnEfftvPrssr "Average cylinder pressure calculated over defined number of combustion cycles for engine cylinder 5.  Negative range is to cover thermodynamic behavior during m…";
CM_ BO_ 2498778110 "Engine Cylinder 6 Combustion Average Information";
CM_ SG_ 2498778110 EngnClndr6AvrgCmstnDrtn "Average duration of combustion calculated over defined number of combustion cycles for engine cylinder 6 with reference to the crank angle.  Combustion duration…";
CM_ SG_ 2498778110 EngnClndr6AvrgCntrfCmstnTmng "Average timing calculated over defined number of combustion cycles for the center of combustion in engine cylinder 6 with reference to the crank angle.  Center …";
CM_ SG_ 2498778110 EngnClndr6AvrgStrtfCmstnTmng "Average start of combustion timing calculated over defined number of combustion cycles for engine cylinder 6 with reference to the crank angle.  When the combus…";
CM_ SG_ 2498778110 EngnClndr6IndtdMnEfftvPrssr "Average cylinder pressure calculated over defined number of combustion cycles for engine cylinder 6.  Negative range is to cover thermodynamic behavior during m…";
CM_ BO_ 2498778366 "Engine Cylinder 7 Combustion Average Information";
CM_ SG_ 2498778366 EngnClndr7AvrgCmstnDrtn "Average duration of combustion calculated over defined number of combustion cycles for engine cylinder 7 with reference to the crank angle.  Combustion duration…";
CM_ SG_ 2498778366 EngnClndr7AvrgCntrfCmstnTmng "Average timing calculated over defined number of combustion cycles for the center of combustion in engine cylinder 7 with reference to the crank angle.  Center …";
CM_ SG_ 2498778366 EngnClndr7AvrgStrtfCmstnTmng "Average start of combustion timing calculated over defined number of combustion cycles for engine cylinder 7 with reference to the crank angle.  When the combus…";
CM_ SG_ 2498778366 EngnClndr7IndtdMnEfftvPrssr "Average cylinder pressure calculated over defined number of combustion cycles for engine cylinder 7.  Negative range is to cover thermodynamic behavior during m…";
CM_ BO_ 2498778622 "Engine Cylinder 8 Combustion Average Information";
CM_ SG_ 2498778622 EngnClndr8AvrgCmstnDrtn "Average duration of combustion calculated over defined number of combustion cycles for engine cylinder 8 with reference to the crank angle.  Combustion duration…";
CM_ SG_ 2498778622 EngnClndr8AvrgCntrfCmstnTmng "Average timing calculated over defined number of combustion cycles for the center of combustion in engine cylinder 8 with reference to the crank angle.  Center …";
CM_ SG_ 2498778622 EngnClndr8AvrgStrtfCmstnTmng "Average start of combustion timing calculated over defined number of combustion cycles for engine cylinder 8 with reference to the crank angle.  When the combus…";
CM_ SG_ 2498778622 EngnClndr8IndtdMnEfftvPrssr "Average cylinder pressure calculated over defined number of combustion cycles for engine cylinder 8.  Negative range is to cover thermodynamic behavior during m…";
CM_ BO_ 2498778878 "Engine Cylinder 9 Combustion Average Information";
CM_ SG_ 2498778878 EngnClndr9AvrgCmstnDrtn "Average duration of combustion calculated over defined number of combustion cycles for engine cylinder 9 with reference to the crank angle.  Combustion duration…";
CM_ SG_ 2498778878 EngnClndr9AvrgCntrfCmstnTmng "Average timing calculated over defined number of combustion cycles for the center of combustion in engine cylinder 9 with reference to the crank angle.  Center …";
CM_ SG_ 2498778878 EngnClndr9AvrgStrtfCmstnTmng "Average start of combustion timing calculated over defined number of combustion cycles for engine cylinder 9 with reference to the crank angle.  When the combus…";
CM_ SG_ 2498778878 EngnClndr9IndtdMnEfftvPrssr "Average cylinder pressure calculated over defined number of combustion cycles for engine cylinder 9.  Negative range is to cover thermodynamic behavior during m…";
CM_ BO_ 2498779134 "Engine Cylinder 10 Combustion Average Information";
CM_ SG_ 2498779134 EngnClndr10AvrgCmstnDrtn "Average duration of combustion calculated over defined number of combustion cycles for engine cylinder 10 with reference to the crank angle.  Combustion duratio…";
CM_ SG_ 2498779134 EngnClndr10AvrgCntrfCmstnTmng "Average timing calculated over defined number of combustion cycles for the center of combustion in engine cylinder 10 with reference to the crank angle.  Center…";
CM_ SG_ 2498779134 EngnClndr10AvrgStrtfCmstnTmng "Average start of combustion timing calculated over defined number of combustion cycles for engine cylinder 10 with reference to the crank angle.  When the combu…";
CM_ SG_ 2498779134 EngnClndr10IndtdMnEfftvPrssr "Average cylinder pressure calculated over defined number of combustion cycles for engine cylinder 10.  Negative range is to cover thermodynamic behavior during …";
CM_ BO_ 2498779390 "Engine Cylinder 11 Combustion Average Information";
CM_ SG_ 2498779390 EngnClndr11AvrgCmstnDrtn "Average duration of combustion calculated over defined number of combustion cycles for engine cylinder 11 with reference to the crank angle.  Combustion duratio…";
CM_ SG_ 2498779390 EngnClndr11AvrgCntrfCmstnTmng "Average timing calculated over defined number of combustion cycles for the center of combustion in engine cylinder 11 with reference to the crank angle.  Center…";
CM_ SG_ 2498779390 EngnClndr11AvrgStrtfCmstnTmng "Average start of combustion timing calculated over defined number of combustion cycles for engine cylinder 11 with reference to the crank angle.  When the combu…";
CM_ SG_ 2498779390 EngnClndr11IndtdMnEfftvPrssr "Average cylinder pressure calculated over defined number of combustion cycles for engine cylinder 11.  Negative range is to cover thermodynamic behavior during …";
CM_ BO_ 2498779646 "Engine Cylinder 12 Combustion Average Information";
CM_ SG_ 2498779646 EngnClndr12AvrgCmstnDrtn "Average duration of combustion calculated over defined number of combustion cycles for engine cylinder 12 with reference to the crank angle.  Combustion duratio…";
CM_ SG_ 2498779646 EngnClndr12AvrgCntrfCmstnTmng "Average timing calculated over defined number of combustion cycles for the center of combustion in engine cylinder 12 with reference to the crank angle.  Center…";
CM_ SG_ 2498779646 EngnClndr12AvrgStrtfCmstnTmng "Average start of combustion timing calculated over defined number of combustion cycles for engine cylinder 12 with reference to the crank angle.  When the combu…";
CM_ SG_ 2498779646 EngnClndr12IndtdMnEfftvPrssr "Average cylinder pressure calculated over defined number of combustion cycles for engine cylinder 12.  Negative range is to cover thermodynamic behavior during …";
CM_ BO_ 2498779902 "Engine Cylinder 13 Combustion Average Information";
CM_ SG_ 2498779902 EngnClndr13AvrgCmstnDrtn "Average duration of combustion calculated over defined number of combustion cycles for engine cylinder 13 with reference to the crank angle.  Combustion duratio…";
CM_ SG_ 2498779902 EngnClndr13AvrgCntrfCmstnTmng "Average timing calculated over defined number of combustion cycles for the center of combustion in engine cylinder 13 with reference to the crank angle.  Center…";
CM_ SG_ 2498779902 EngnClndr13AvrgStrtfCmstnTmng "Average start of combustion timing calculated over defined number of combustion cycles for engine cylinder 13 with reference to the crank angle.  When the combu…";
CM_ SG_ 2498779902 EngnClndr13IndtdMnEfftvPrssr "Average cylinder pressure calculated over defined number of combustion cycles for engine cylinder 13.  Negative range is to cover thermodynamic behavior during …";
CM_ BO_ 2498780158 "Engine Cylinder 14 Combustion Average Information";
CM_ SG_ 2498780158 EngnClndr14AvrgCmstnDrtn "Average duration of combustion calculated over defined number of combustion cycles for engine cylinder 14 with reference to the crank angle.  Combustion duratio…";
CM_ SG_ 2498780158 EngnClndr14AvrgCntrfCmstnTmng "Average timing calculated over defined number of combustion cycles for the center of combustion in engine cylinder 14 with reference to the crank angle.  Center…";
CM_ SG_ 2498780158 EngnClndr14AvrgStrtfCmstnTmng "Average start of combustion timing calculated over defined number of combustion cycles for engine cylinder 14 with reference to the crank angle.  When the combu…";
CM_ SG_ 2498780158 EngnClndr14IndtdMnEfftvPrssr "Average cylinder pressure calculated over defined number of combustion cycles for engine cylinder 14.  Negative range is to cover thermodynamic behavior during …";
CM_ BO_ 2498780414 "Engine Cylinder 15 Combustion Average Information";
CM_ SG_ 2498780414 EngnClndr15AvrgCmstnDrtn "Average duration of combustion calculated over defined number of combustion cycles for engine cylinder 15 with reference to the crank angle.  Combustion duratio…";
CM_ SG_ 2498780414 EngnClndr15AvrgCntrfCmstnTmng "Average timing calculated over defined number of combustion cycles for the center of combustion in engine cylinder 15 with reference to the crank angle.  Center…";
CM_ SG_ 2498780414 EngnClndr15AvrgStrtfCmstnTmng "Average start of combustion timing calculated over defined number of combustion cycles for engine cylinder 15 with reference to the crank angle.  When the combu…";
CM_ SG_ 2498780414 EngnClndr15IndtdMnEfftvPrssr "Average cylinder pressure calculated over defined number of combustion cycles for engine cylinder 15.  Negative range is to cover thermodynamic behavior during …";
CM_ BO_ 2498780670 "Engine Cylinder 16 Combustion Average Information";
CM_ SG_ 2498780670 EngnClndr16AvrgCmstnDrtn "Average duration of combustion calculated over defined number of combustion cycles for engine cylinder 16 with reference to the crank angle.  Combustion duratio…";
CM_ SG_ 2498780670 EngnClndr16AvrgCntrfCmstnTmng "Average timing calculated over defined number of combustion cycles for the center of combustion in engine cylinder 16 with reference to the crank angle.  Center…";
CM_ SG_ 2498780670 EngnClndr16AvrgStrtfCmstnTmng "Average start of combustion timing calculated over defined number of combustion cycles for engine cylinder 16 with reference to the crank angle.  When the combu…";
CM_ SG_ 2498780670 EngnClndr16IndtdMnEfftvPrssr "Average cylinder pressure calculated over defined number of combustion cycles for engine cylinder 16.  Negative range is to cover thermodynamic behavior during …";
CM_ BO_ 2498780926 "Engine Cylinder 17 Combustion Average Information";
CM_ SG_ 2498780926 EngnClndr17AvrgCmstnDrtn "Average duration of combustion calculated over defined number of combustion cycles for engine cylinder 17 with reference to the crank angle.  Combustion duratio…";
CM_ SG_ 2498780926 EngnClndr17AvrgCntrfCmstnTmng "Average timing calculated over defined number of combustion cycles for the center of combustion in engine cylinder 17 with reference to the crank angle.  Center…";
CM_ SG_ 2498780926 EngnClndr17AvrgStrtfCmstnTmng "Average start of combustion timing calculated over defined number of combustion cycles for engine cylinder 17 with reference to the crank angle.  When the combu…";
CM_ SG_ 2498780926 EngnClndr17IndtdMnEfftvPrssr "Average cylinder pressure calculated over defined number of combustion cycles for engine cylinder 17.  Negative range is to cover thermodynamic behavior during …";
CM_ BO_ 2498781182 "Engine Cylinder 18 Combustion Average Information";
CM_ SG_ 2498781182 EngnClndr18AvrgCmstnDrtn "Average duration of combustion calculated over defined number of combustion cycles for engine cylinder 18 with reference to the crank angle.  Combustion duratio…";
CM_ SG_ 2498781182 EngnClndr18AvrgCntrfCmstnTmng "Average timing calculated over defined number of combustion cycles for the center of combustion in engine cylinder 18 with reference to the crank angle.  Center…";
CM_ SG_ 2498781182 EngnClndr18AvrgStrtfCmstnTmng "Average start of combustion timing calculated over defined number of combustion cycles for engine cylinder 18 with reference to the crank angle.  When the combu…";
CM_ SG_ 2498781182 EngnClndr18IndtdMnEfftvPrssr "Average cylinder pressure calculated over defined number of combustion cycles for engine cylinder 18.  Negative range is to cover thermodynamic behavior during …";
CM_ BO_ 2498781438 "Engine Cylinder 19 Combustion Average Information";
CM_ SG_ 2498781438 EngnClndr19AvrgCmstnDrtn "Average duration of combustion calculated over defined number of combustion cycles for engine cylinder 19 with reference to the crank angle.  Combustion duratio…";
CM_ SG_ 2498781438 EngnClndr19AvrgCntrfCmstnTmng "Average timing calculated over defined number of combustion cycles for the center of combustion in engine cylinder 19 with reference to the crank angle.  Center…";
CM_ SG_ 2498781438 EngnClndr19AvrgStrtfCmstnTmng "Average start of combustion timing calculated over defined number of combustion cycles for engine cylinder 19 with reference to the crank angle.  When the combu…";
CM_ SG_ 2498781438 EngnClndr19IndtdMnEfftvPrssr "Average cylinder pressure calculated over defined number of combustion cycles for engine cylinder 19.  Negative range is to cover thermodynamic behavior during …";
CM_ BO_ 2498781694 "Engine Cylinder 20 Combustion Average Information";
CM_ SG_ 2498781694 EngnClndr20AvrgCmstnDrtn "Average duration of combustion calculated over defined number of combustion cycles for engine cylinder 20 with reference to the crank angle.  Combustion duratio…";
CM_ SG_ 2498781694 EngnClndr20AvrgCntrfCmstnTmng "Average timing calculated over defined number of combustion cycles for the center of combustion in engine cylinder 20 with reference to the crank angle.  Center…";
CM_ SG_ 2498781694 EngnClndr20AvrgStrtfCmstnTmng "Average start of combustion timing calculated over defined number of combustion cycles for engine cylinder 20 with reference to the crank angle.  When the combu…";
CM_ SG_ 2498781694 EngnClndr20IndtdMnEfftvPrssr "Average cylinder pressure calculated over defined number of combustion cycles for engine cylinder 20.  Negative range is to cover thermodynamic behavior during …";
CM_ BO_ 2498825982 "Dump Truck Body Information";
CM_ SG_ 2498825982 DmpBdRsPstnRltvtRmmnddMxmm "The angular position of the dump body expressed as a percentage of the maximum recommended body raised position. 100% represents the maximum default raised posi…";
CM_ SG_ 2498825982 DumpBodyEjectorBladePosition "The dump body ejector blade is used to push material out of the dump body of a dump truck. 0% represents the fully retracted position and 100% represents the fu…";
CM_ SG_ 2498825982 DumpBodyRaiseAngle "The angular position of the dump body referenced to the vehicle chassis. 0 degrees represents the body in its resting position.…";
CM_ SG_ 2498825982 DumpBodyRollAngle "The angle between the dump body y-axis and the ground plane (i.e. rotation about the X-axis). The roll angle for a roll to the right is reported with a positive…";
CM_ BO_ 2499547902 "Cab Door Control";
CM_ SG_ 2499547902 CabDoorsLockActuationCommand "Commands cab door latch state change: lock or unlock.000b = Unlock left front cab door latch (driver door on LH steer vehicles)001b = Unlock right front cab doo…";
CM_ SG_ 2499547902 LeftFrontWindowPositionCommand "Commands position change of left front window (driver door window on left-hand steer vehicles).000b = Window move up001b = Window move down010b = Window auto up…";
CM_ SG_ 2499547902 LeftRearWindowPositionCommand "Commands position change of left rear window.000b = Window move up001b = Window move down010b = Window auto up011b = Window auto down100b = Reserved101b = Reser…";
CM_ SG_ 2499547902 MirrorLeft1HeatCommand "Command to activate heater for primary mirror on the left side (driver side for left-hand steer vehicle).  Mirror heat may be expected to latch in the on state …";
CM_ SG_ 2499547902 MirrorLeft1HorizontalCommand "Commands horizontal position change of the primary mirror on the left side (driver side for left-hand steer vehicles).00b = Move left01b = Move right10b = Reser…";
CM_ SG_ 2499547902 MirrorLeft1VerticalCommand "Commands vertical position change of the primary mirror on the left side (driver side for left-hand steer vehicles).00b = Move up01b = Move down10b = Reserved11…";
CM_ SG_ 2499547902 MirrorLeft2HeatCommand "Command to activate heater for second mirror on the left side (driver side for left-hand steer vehicle).  Mirror heat may be expected to latch in the on state u…";
CM_ SG_ 2499547902 MirrorLeft2HorizontalCommand "Commands horizontal position change of the second mirror on the left side (driver side for left-hand steer vehicles).00b = Move left01b = Move right10b = Reserv…";
CM_ SG_ 2499547902 MirrorLeft2VerticalCommand "Commands vertical position change of the second mirror on the left side (driver side for left-hand steer vehicles). 00b = Move up01b = Move down10b = Reserved11…";
CM_ SG_ 2499547902 MirrorRight1HeatCommand "Command to activate heater for primary mirror on the right side (passenger side for left-hand steer vehicle).  Mirror heat may be expected to latch in the on st…";
CM_ SG_ 2499547902 MirrorRight1HorizontalCommand "Commands horizontal position change of the primary mirror on the right side (passenger side for lefthand steer vehicles).00b = Move left01b = Move right10b = Re…";
CM_ SG_ 2499547902 MirrorRight1VerticalCommand "Commands vertical position change of the primary mirror on the right side (passenger side for lefthand steer vehicles).00b = Move up01b = Move down10b = Reserve…";
CM_ SG_ 2499547902 MirrorRight2HeatCommand "Command to activate heater for second mirror on the right side (passenger side for left-hand steer vehicle).  Mirror heat may be expected to latch in the on sta…";
CM_ SG_ 2499547902 MirrorRight2HorizontalCommand "Commands horizontal position change of the second mirror on the right side (passenger side for lefthand steer vehicles).00b = Move left01b = Move right10b = Res…";
CM_ SG_ 2499547902 MirrorRight2VerticalCommand "Commands vertical position change of the second mirror on the right side (passenger side for lefthand steer vehicles).00b = Move up01b = Move down10b = Reserved…";
CM_ SG_ 2499547902 RemoteCabDoorLockRequest "Request to the cab door lock controller from Remote Keyless Entry or or other external device to lock or unlock doors.This parameter is different from Cab Doors…";
CM_ SG_ 2499547902 RightFrontWindowPositionCommand "Commands position change of right front window (passenger door window on left-hand steer vehicles).000b = Window move up001b = Window move down010b = Window aut…";
CM_ SG_ 2499547902 RightRearWindowPositionCommand "Commands position change of the right rear window.000b = Window move up001b = Window move down010b = Window auto up011b = Window auto down100b = Reserved101b = …";
CM_ BO_ 2499548158 "Door Latch Status";
CM_ SG_ 2499548158 LeftFrontCabDoorLatchPosition "Status of the left front cab door latch (driver door for left-hand steer vehicles). Door latches may have 3 positions indicating fully open, 1st detent or ajar,…";
CM_ SG_ 2499548158 LeftRearCabDoorLatchPosition "Status of the left rear cab door latch. Door latches may have 3 positions indicating fully open, 1st detent or ajar, and 2nd detent or fully closed.000b = Door …";
CM_ SG_ 2499548158 RightFrontCabDoorLatchPosition "Status of the right front cab door latch (passenger door for left-hand steer vehicles). Door latches may have 3 positions indicating fully open, 1st detent or a…";
CM_ SG_ 2499548158 RightRearCabDoorLatchPosition "Status of the right rear cab door latch. Door latches may have 3 positions indicating fully open, 1st detent or ajar, and 2nd detent or fully closed.000b = Door…";
CM_ BO_ 2499548670 "Vehicle Electrical Power 6";
CM_ SG_ 2499548670 BatteryPotentialPowerInput3 "This parameter measures the third source of battery potential as measured at the input of the ECU/actuator etc. coming from one or more batteries, irrespective …";
CM_ SG_ 2499548670 BatteryPotentialPowerInput4 "This parameter measures the fourth source of battery potential as measured at the input of the ECU/actuator etc. coming from one or more batteries, irrespective…";
CM_ SG_ 2499548670 SLIBattery3NetCurrent "Net flow of electrical current into/out of the third battery or third set of batteries used for starting the engine, for lighting, and for ignition (SLI).…";
CM_ SG_ 2499548670 SLIBattery4NetCurrent "Net flow of electrical current into/out of the fourth battery or fourth set of batteries used for starting the engine, for lighting, and for ignition (SLI).…";
CM_ BO_ 2499548926 "Payload Temperature 2";
CM_ SG_ 2499548926 PayloadTemperature5 "Temperature of payload at measurement point 5.Measurement position is manufacturer or regulation specific.…";
CM_ BO_ 2499549182 "Payload Temperature 1";
CM_ SG_ 2499549182 PayloadTemperature1 "Temperature of payload at measurement point 1.Measurement position is manufacturer or regulation specific.…";
CM_ SG_ 2499549182 PayloadTemperature2 "Temperature of payload at measurement point 2.Measurement position is manufacturer or regulation specific.…";
CM_ SG_ 2499549182 PayloadTemperature3 "Temperature of payload at measurement point 3.Measurement position is manufacturer or regulation specific.…";
CM_ SG_ 2499549182 PayloadTemperature4 "Temperature of payload at measurement point 4.Measurement position is manufacturer or regulation specific.…";
CM_ BO_ 2499556094 "Aftertreatment 1 Particulate Sensor Information 3";
CM_ SG_ 2499556094 Atttt1PttSsHtHSdDvDstStts "The value of this parameter is not retained when power is removed from the particulate sensor.000b = Tests monitored continuously. There are no enable or pause …";
CM_ SG_ 2499556094 Atttt1PttSsHtHSdDvPFMI "Used to identify the applicable J1939-73 FMI detected in the aftertreatment particulate sensor heater high side driver by the manufacturer’s sensor control soft…";
CM_ SG_ 2499556094 Atttt1PttSsHtLwSdDvDstStts "The value of this parameter is not retained when power is removed from the particulate sensor.000b = Tests monitored continuously. There are no enable or pause …";
CM_ SG_ 2499556094 Atttt1PttSsHtLwSdDvPFMI "Used to identify the applicable J1939-73 FMI detected in the aftertreatment particulate sensor heater high side driver by the manufacturer’s sensor control soft…";
CM_ SG_ 2499556094 Atttt1PttSsHtPwSppDstStts "The value of this parameter is not retained when power is removed from the particulate sensor.000b = Tests monitored continuously. There are no enable or pause …";
CM_ SG_ 2499556094 Atttt1PttSsHtPwSppPFMI "Used to identify the applicable J1939-73 FMI detected in the aftertreatment particulate sensor heater power supply by the manufacturer’s sensor control software…";
CM_ SG_ 2499556094 Atttt1PttSsIptDstStts "The value of this parameter is not retained when power is removed from the particulate sensor.000b = Tests monitored continuously. There are no enable or pause …";
CM_ SG_ 2499556094 Atttt1PttSsIptPFMI "Used to identify the applicable J1939-73 FMI detected in the aftertreatment particulate sensor input by the manufacturer’s sensor control software in exhaust ba…";
CM_ SG_ 2499556094 Atttt1PttSsPwSppDstStts "The value of this parameter is not retained when power is removed from the particulate sensor.000b = Tests monitored continuously. There are no enable or pause …";
CM_ SG_ 2499556094 Atttt1PttSsPwSppPFMI "Used to identify the applicable J1939-73 FMI detected in the aftertreatment particulate sensor power supply by the manufacturer’s sensor control software in exh…";
CM_ BO_ 2499556350 "Engine Fuel Injector Metering Rail Pressure Information 3";
CM_ SG_ 2499556350 EngnFl1InjtrMtrngRl1DsrdPrssr "The desired pressure of fuel in the primary, or first, metering rail as delivered from the supply pump to the injector metering intake.…";
CM_ SG_ 2499556350 EngnFl1InjtrMtrngRl2DsrdPrssr "The desired pressure of fuel in metering rail 2 as delivered from the supply pump to the injector metering intake.…";
CM_ BO_ 2499556606 "Engine Fuel Injector Metering Rail Pressure Information 2";
CM_ SG_ 2499556606 EF1ItMtR1Pss1ExtddR "The pressure of fuel measured by first rail pressure sensor in the primary, or first, metering rail as delivered from the supply pump to the injector metering i…";
CM_ SG_ 2499556606 EF1ItMtR1Pss2ExtddR "The pressure of fuel measured by the second rail pressure sensor in the primary, or first, metering rail as delivered from the supply pump to the injector meter…";
CM_ SG_ 2499556606 EF1ItMtR2Pss1ExtddR "The pressure of fuel measured by first rail pressure sensor in the metering rail 2 as delivered from the supply pump to the injector metering intake.…";
CM_ SG_ 2499556606 EF1ItMtR2Pss2ExtddR "The pressure of fuel measured by second rail pressure sensor in the metering rail 2 as delivered from the supply pump to the injector metering intake.…";
CM_ BO_ 2499557118 "Gaseous Fuel Supply Valve Information";
CM_ SG_ 2499557118 EngnGssFlSpplBldVlv1Pstn "Position of bleed valve 1, which is used to control the flow of gaseous fuel through the fuel supply unit. 0% represents valve fully closed and 100% represents …";
CM_ SG_ 2499557118 EngnGssFlSpplBldVlv2Pstn "Position of bleed valve 2, which is used to control the flow of gaseous fuel through the fuel supply unit. 0% represents valve fully closed and 100% represents …";
CM_ SG_ 2499557118 EngnGssFlSpplBldVlv3Pstn "Position of bleed valve 3, which is used to control the flow of gaseous fuel through the fuel supply unit. 0% represents valve fully closed and 100% represents …";
CM_ SG_ 2499557118 EngnGssFlSpplShtffVlv1Pstn "Position of shutoff valve 1, which is used to control the flow of gaseous fuel through the fuel supply unit. 0% represents valve fully closed and 100% represent…";
CM_ SG_ 2499557118 EngnGssFlSpplShtffVlv2Pstn "Position of shutoff valve 2, which is used to control the flow of gaseous fuel through the fuel supply unit. 0% represents valve fully closed and 100% represent…";
CM_ SG_ 2499557118 InertGasSupplyValvePosition "Position of inert gas supply valve used to control the flow of inert gas into the engine to purge the system.0% represents valve fully closed and 100% represent…";
CM_ BO_ 2499557374 "Engine Oil Mist Detection Information 2";
CM_ SG_ 2499557374 EngineOilMist10Concentration "Percentage of detected oil mist in compartment 10 compared to the lower explosion limit (LEL). 100% means the measured value is on the lower explosion limit,whe…";
CM_ SG_ 2499557374 EngineOilMist9Concentration "Percentage of detected oil mist in compartment 9 compared to the lower explosion limit (LEL). 100% means the measured value is on the lower explosion limit,wher…";
CM_ BO_ 2499557630 "Engine Oil Mist Detection Information 1";
CM_ SG_ 2499557630 EngineOilMist1Concentration "Percentage of detected oil mist in compartment 1 compared to the lower explosion limit (LEL). 100% means the measured value is on the lower explosion limit, whe…";
CM_ SG_ 2499557630 EngineOilMist2Concentration "Percentage of detected oil mist in compartment 2 compared to the lower explosion limit (LEL). 100% means the measured value is on the lower explosion limit,wher…";
CM_ SG_ 2499557630 EngineOilMist3Concentration "Percentage of detected oil mist in compartment 3 compared to the lower explosion limit (LEL). 100% means the measured value is on the lower explosion limit,wher…";
CM_ SG_ 2499557630 EngineOilMist4Concentration "Percentage of detected oil mist in compartment 4 compared to the lower explosion limit (LEL). 100% means the measured value is on the lower explosion limit,wher…";
CM_ SG_ 2499557630 EngineOilMist5Concentration "Percentage of detected oil mist in compartment 5 compared to the lower explosion limit (LEL). 100% means the measured value is on the lower explosion limit,wher…";
CM_ SG_ 2499557630 EngineOilMist6Concentration "Percentage of detected oil mist in compartment 6 compared to the lower explosion limit (LEL). 100% means the measured value is on the lower explosion limit,wher…";
CM_ SG_ 2499557630 EngineOilMist7Concentration "Percentage of detected oil mist in compartment 7 compared to the lower explosion limit (LEL). 100% means the measured value is on the lower explosion limit,wher…";
CM_ SG_ 2499557630 EngineOilMist8Concentration "Percentage of detected oil mist in compartment 8 compared to the lower explosion limit (LEL). 100% means the measured value is on the lower explosion limit,wher…";
CM_ BO_ 2499557886 "Gaseous Fuel Supply Pressure 2";
CM_ SG_ 2499557886 PlntGssFlSpplOtltPrssr "Pressure of the gaseous fuel supplied from the plant room for one or more engines.  Based on the application, plant room will contain fuel tank for gas, vaporiz…";
CM_ SG_ 2499557886 PlntInrtGsSpplOtltPrssr "Pressure of the purge gas supplied to the engine. Inert gas is used to remove gaseous fuel build-up in the engines and in the fuel supply lines when gaseous fue…";
CM_ BO_ 2499558142 "Gaseous Fuel Supply Pressure 1";
CM_ SG_ 2499558142 EngnGssFlSpplPrssr2 "Second gage pressure measurement of gaseous fuel supply to fuel metering device. If only one sensor is used for gas supply pressure measurement, use SPN 159 ins…";
CM_ SG_ 2499558142 EngnGssFlSpplShtffVlv1IntkPrssr "Pressure of gaseous fuel supply measured at shutoff valve 1 in gaseous fuel supply unit. Shutoff valves are used to regulate gaseous fuel supply to engine.…";
CM_ SG_ 2499558142 EngnGssFlSpplShtffVlv2IntkPrssr "Pressure of gaseous fuel supply measured at shutoff valve 2 in gaseous fuel supply unit. Shutoff valves are used to regulate gaseous fuel supply to engine.…";
CM_ SG_ 2499558142 EngnGssFlSpplUntIntkPrssr "Pressure of gaseous fuel supply measured at the intake of gaseous fuel supply unit. Gaseous fuel valve unit contains block and bleed valves to regulate the flow…";
CM_ BO_ 2499580158 "Engine Fuel Injector Metering Rail Pressure Information 1";
CM_ SG_ 2499580158 EngnFl1InjtrMtrngRl1Prssr1 "The pressure of fuel measured by first rail pressure sensor in the primary, or first, metering rail as delivered from the supply pump to the injector metering i…";
CM_ SG_ 2499580158 EngnFl1InjtrMtrngRl1Prssr2 "The pressure of fuel measured by the second rail pressure sensor in the primary, or first, metering rail as delivered from the supply pump to the injector meter…";
CM_ SG_ 2499580158 EngnFl1InjtrMtrngRl2Prssr1 "The pressure of fuel measured by first rail pressure sensor in the metering rail 2 as delivered from the supply pump to the injector metering intake.Note:  This…";
CM_ SG_ 2499580158 EngnFl1InjtrMtrngRl2Prssr2 "The pressure of fuel measured by second rail pressure sensor in the metering rail 2 as delivered from the supply pump to the injector metering intake. Note:  Th…";
CM_ BO_ 2499582206 "Vehicle Speed Limiter";
CM_ SG_ 2499582206 SftTpSpdLmtRmnngCntnsIntrvlDstn "Indicates the remaining distance that the vehicle can continuously travel at the Soft Top Speed Limit.  This parameter will decrement while the Soft Top Speed L…";
CM_ SG_ 2499582206 SftTpSpdLmtRmnngDstn "Indicates the remaining distance that the vehicle can travel at the Soft Top Speed Limit within the larger reset window. The reset window may be distance (possi…";
CM_ SG_ 2499582206 SoftTopRatioLimitExceeded "Greenhouse Gas Regulations limit the overall distance that Soft Top Speed can be used in relation to the total distance traveled. This parameter indicates the a…";
CM_ SG_ 2499582206 SoftTopSpeedLimitActive "Indicates that the current Maximum Vehicle Speed Limit (SPN 74) has been temporarily increased to the Soft Top Speed Limit. Under certain conditions, the legal …";
CM_ SG_ 2499582206 SoftTopSpeedLimitResetDistance "This parameter will decrement as long as the vehicle is moving. When this parameter reaches 0, it will be reset to its maximum value and continue to decrement.…";
CM_ BO_ 2499583486 "Engine Timing Actuator Position Command";
CM_ SG_ 2499583486 EngnTmngAttr1PstnCmmnd "The commanded position of actuator 1 on the engine timing system by Engine Control Module.  The engine timing system has different timing positions and the timi…";
CM_ SG_ 2499583486 EngnTmngAttr2PstnCmmnd "The commanded position of actuator 2 on the engine timing system by Engine Control Module.  The engine timing system has different timing positions and the timi…";
CM_ BO_ 2499583742 "Engine Timing Actuator Position";
CM_ SG_ 2499583742 EngineTimingActuator1 "The detected position of actuator 1 on the Engine Timing System, where the system has different timing positions depending on current operating status of the en…";
CM_ SG_ 2499583742 EngineTimingActuator2 "The detected position of actuator 2 on the Engine Timing System, where the system has different timing positions depending on current operating status of the en…";
CM_ SG_ 2499583742 EngnTmngAttr1RqstdPstn "The requested position of actuator 1 on the Engine Timing System, as determined by external system such as operator, monitoring, or protection system. Requested…";
CM_ SG_ 2499583742 EngnTmngAttr2RqstdPstn "The requested position of actuator 2 on the Engine Timing System, as determined by external system such as operator, monitoring or protection system. Requested …";
CM_ BO_ 2499592190 "Electronic Transmission Controller #10";
CM_ SG_ 2499592190 TrnsmssnClth1AttrPrnt "The current modulated value for the transmission clutch 1 actuator, where 0% = no hydraulic pressure and 100% = full hydraulic pressure.…";
CM_ SG_ 2499592190 TrnsmssnClth1ClngAttrStts "Identifies the status of the actuator that cools transmission clutch 1.00b = off01b = on10b = error11b = not available…";
CM_ SG_ 2499592190 TrnsmssnClth2AttrPrnt "The current modulated value for the transmission clutch 2 actuator, where 0% = no hydraulic pressure and 100% = full hydraulic pressure.…";
CM_ SG_ 2499592190 TrnsmssnClth2ClngAttrStts "Identifies the status of the actuator that cools transmission clutch 2.00b = off01b = on10b = error11b = not available…";
CM_ SG_ 2499592190 TrnsmssnHdrlPmpAttr1Prnt "The current modulated value for the actuator that controls the transmission hydraulic pump, where 0% = no hydraulic pressure and 100% = full hydraulic pressure.…";
CM_ SG_ 2499592190 TrnsmssnHdrlPmpAttr2Prnt "The current modulated value for actuator 2 that controls the transmission hydraulic pump, where 0% = no hydraulic pressure and 100% = full hydraulic pressure.…";
CM_ SG_ 2499592190 TrnsmssnShftAttr1Prnt "The current modulated value for the transmission shift 1 actuator, where 0% = no hydraulic pressure and 100% = full hydraulic pressure.…";
CM_ SG_ 2499592190 TrnsmssnShftAttr2Prnt "The current modulated value for the transmission shift 2 actuator, where 0% = no hydraulic pressure and 100% = full hydraulic pressure.…";
CM_ SG_ 2499592190 TrnsmssnShftRl1AttrStts "Identifies the status of the actuator that moves the transmission shift rail identified as rail #1.00b = off01b = on10b = error11b = not available…";
CM_ SG_ 2499592190 TrnsmssnShftRl2AttrStts "Identifies the status of the actuator that moves the transmission shift rail identified as rail #2.00b = off01b = on10b = error11b = not available…";
CM_ SG_ 2499592190 TrnsmssnShftRl3AttrStts "Identifies the status of the actuator that moves the transmission shift rail identified as rail #3.00b = off01b = on10b = error11b = not available…";
CM_ SG_ 2499592190 TrnsmssnShftRl4AttrStts "Identifies the status of the actuator that moves the transmission shift rail identified as rail #4.00b = off01b = on10b = error11b = not available…";
CM_ SG_ 2499592190 TrnsmssnShftRl5AttrStts "Identifies the status of the actuator that moves the transmission shift rail identified as rail #5.00b = off01b = on10b = error11b = not available…";
CM_ SG_ 2499592190 TrnsmssnShftRl6AttrStts "Identifies the status of the actuator that moves the transmission shift rail identified as rail #6.00b = off01b = on10b = error11b = not available…";
CM_ BO_ 2499592446 "Electronic Transmission Controller #11";
CM_ SG_ 2499592446 TransmissionShiftRail1Position "The current position of transmission shift rail identified as rail #1.…";
CM_ SG_ 2499592446 TransmissionShiftRail2Position "The current position of transmission shift rail identified as rail #2.…";
CM_ SG_ 2499592446 TransmissionShiftRail3Position "The current position of transmission shift rail identified as rail #3.…";
CM_ SG_ 2499592446 TransmissionShiftRail4Position "The current position of transmission shift rail identified as rail #4.…";
CM_ SG_ 2499592446 TransmissionShiftRail5Position "The current position of transmission shift rail identified as rail #5.…";
CM_ SG_ 2499592446 TransmissionShiftRail6Position "The current position of transmission shift rail identified as rail #6.…";
CM_ BO_ 2499604222 "Land Leveling System Reference Elevation Data";
CM_ SG_ 2499604222 BladeElevationDeviationLeft "Indicate the blade's left elevation deviation with respect to the reference elevation.  Serves as an indication of how far the left end of the blade is above or…";
CM_ SG_ 2499604222 BladeElevationDeviationRight "Indicate the blade's right elevation deviation with respect to the reference elevation.  Serves as an indication of how far the left end of the blade is above o…";
CM_ SG_ 2499604222 BldRfrnElvtnOffstLft "Indicates the blade's left elevation offset with respect to the reference elevation.  An offset of 0 m represents no offset from the reference elevation.  A pos…";
CM_ SG_ 2499604222 BldRfrnElvtnOffstRght "Indicates the blade's right elevation offset with respect to the reference elevation.  An offset of 0 m represents no offset from the reference elevation.  A po…";
CM_ BO_ 2499604478 "Engine Fluid Level/Pressure 11";
CM_ SG_ 2499604478 EExstGsRt1OttAstPssHRst "EGR outlet absolute pressure is measured after the EGR 1 valve. See SPN 5019 for 1 byte resolution.…";
CM_ SG_ 2499604478 EFDvPssHRstExtddR "Gage pressure of fuel in system as delivered from supply pump to the injection pump. See SPN 94 for alternate resolution.See also SPN 5578 for Engine Fuel Deliv…";
CM_ SG_ 2499604478 EngnExhstGsRrltn1IntkAsltPrssr "EGR intake absolute pressure measured before the EGR 1 valve.…";
CM_ SG_ 2499604478 EngnOlPrssrHghRsltnExtnddRng "Gage pressure of oil in engine lubrication system as provided by oil pump. See SPN 100 for alternate resolution.…";
CM_ BO_ 2499607550 "Engine Manifold Actuator Position";
CM_ SG_ 2499607550 EExstMdB1FwBVvAttPst "Actual percentage of maximum Engine Exhaust Manifold Bank 1 Balance valve opening. 0% means valve is closed. 100% means maximum valve opening (full gas flow).…";
CM_ SG_ 2499607550 EExstMdB2FwBVvAttPst "Actual percentage of maximum Engine Manifold Bank 2 Balance valve opening. 0% means valve is closed. 100% means maximum valve opening (full gas flow).…";
CM_ BO_ 2499614462 "Occupant Classification System Information";
CM_ SG_ 2499614462 DrvrOpntClssftnSstmStts "State of Occupant Classification System for driver.000b = empty001b = child010b = small adult011b = adult100b = large adult101b = reserved110b = Error - Classif…";
CM_ SG_ 2499614462 OpntClssftnSstm10Stts "State of Occupant Classification System for seat position 10.00b = empty01b = occupied10b = Error - Classification cannot be determined11b = not available…";
CM_ SG_ 2499614462 OpntClssftnSstm3Stts "State of Occupant Classification System for seat position 3.00b = empty01b = occupied10b = Error - Classification cannot be determined11b = not available…";
CM_ SG_ 2499614462 OpntClssftnSstm4Stts "State of Occupant Classification System for seat position 4.00b = empty01b = occupied10b = Error - Classification cannot be determined11b = not available…";
CM_ SG_ 2499614462 OpntClssftnSstm5Stts "State of Occupant Classification System for seat position 5.00b = empty01b = occupied10b = Error - Classification cannot be determined11b = not available…";
CM_ SG_ 2499614462 OpntClssftnSstm6Stts "State of Occupant Classification System for seat position 6.00b = empty01b = occupied10b = Error - Classification cannot be determined11b = not available…";
CM_ SG_ 2499614462 OpntClssftnSstm7Stts "State of Occupant Classification System for seat position 7.00b = empty01b = occupied10b = Error - Classification cannot be determined11b = not available…";
CM_ SG_ 2499614462 OpntClssftnSstm8Stts "State of Occupant Classification System for seat position 8.00b = empty01b = occupied10b = Error - Classification cannot be determined11b = not available…";
CM_ SG_ 2499614462 OpntClssftnSstm9Stts "State of Occupant Classification System for seat position 9.00b = empty01b = occupied10b = Error - Classification cannot be determined11b = not available…";
CM_ SG_ 2499614462 PssngrOpntClssftnSstmStts "State of Occupant Classification System for passenger.000b = empty001b = child010b = small adult011b = adult100b = large adult101b = Error - Classification of o…";
CM_ BO_ 2499614718 "Beltlock and Airbag Deactivation Switch Information";
CM_ SG_ 2499614718 Beltlock10Status "State of switch used to determine if Beltlock 10 is buckled.00b = unlocked01b = locked10b = Error - Beltlock state cannot be determined11b = not available…";
CM_ SG_ 2499614718 Beltlock3Status "State of switch used to determine if Beltlock 3 is buckled.00b = unlocked01b = locked10b = Error - Beltlock state cannot be determined11b = not available…";
CM_ SG_ 2499614718 Beltlock4Status "State of switch used to determine if Beltlock 4 is buckled.00b = unlocked01b = locked10b = Error - Beltlock state cannot be determined11b = not available…";
CM_ SG_ 2499614718 Beltlock5Status "State of switch used to determine if Beltlock 5 is buckled.00b = unlocked01b = locked10b = Error - Beltlock state cannot be determined11b = not available…";
CM_ SG_ 2499614718 Beltlock6Status "State of switch used to determine if Beltlock 6 is buckled.00b = unlocked01b = locked10b = Error - Beltlock state cannot be determined11b = not available…";
CM_ SG_ 2499614718 Beltlock7Status "State of switch used to determine if Beltlock 7 is buckled.00b = unlocked01b = locked10b = Error - Beltlock state cannot be determined11b = not available…";
CM_ SG_ 2499614718 Beltlock8Status "State of switch used to determine if Beltlock 8 is buckled.00b = unlocked01b = locked10b = Error - Beltlock state cannot be determined11b = not available…";
CM_ SG_ 2499614718 Beltlock9Status "State of switch used to determine if Beltlock 9 is buckled.00b = unlocked01b = locked10b = Error - Beltlock state cannot be determined11b = not available…";
CM_ SG_ 2499614718 DriverBeltlockStatus "State of switch used to determine if Driver Beltlock is buckled.00b = unlocked01b = locked10b = Error - Beltlock state cannot be determined11b = not available…";
CM_ SG_ 2499614718 PassengerBeltlockStatus "State of switch used to determine if Passenger Beltlock is buckled.00b = unlocked01b = locked10b = Error - Beltlock state cannot be determined11b = not availabl…";
CM_ SG_ 2499614718 PssngrArgDtvtnSwthStts "State of switch used to deactivate Passenger Airbag manually.00b = passenger airbag activated01b = passenger airbag deactivated10b = Error - State of deactivati…";
CM_ BO_ 2499624702 "Aftertreatment 1 SCR Exhaust Gas Temperature 1";
CM_ SG_ 2499624702 Aftrtrtmnt1SCRIntkTmprtr "Temperature of engine combustion byproducts entering the SCR in exhaust bank 1.…";
CM_ SG_ 2499624702 Aftrtrtmnt1SCROtltTmprtr "Temperature of engine combustion byproducts leaving the SCR outlet in exhaust bank 1.…";
CM_ SG_ 2499624702 Atttt1SCRItTptPFMI "Used to identify the applicable J1939-73 FMI detected in the SCR intake temperature sensor by the manufacturer’s sensor control software in exhaust bank 1.  In …";
CM_ SG_ 2499624702 Atttt1SCROttTptPFMI "Used to identify the applicable J1939-73 FMI detected in the SCR outlet temperature sensor by the manufacturer’s sensor control software in exhaust bank 1. In t…";
CM_ BO_ 2499630078 "Engine Average Information";
CM_ SG_ 2499630078 EngineExhaustTemperatureAverage "The calculated average temperature based upon all of the engine exhaust port temperatures.  This is the average temperature based upon the exhaust port temperat…";
CM_ SG_ 2499630078 EngnExhstBnk1TmprtrAvrg "The calculated average temperature based upon all of the Bank 1 (left bank) engine exhaust port temperatures.  This is the average temperature based upon the ex…";
CM_ SG_ 2499630078 EngnExhstBnk2TmprtrAvrg "The calculated average temperature based upon all of the Bank 2 (right bank) engine exhaust port temperatures.  This is the average temperature based upon the e…";
CM_ BO_ 2499635454 "Gross Combination Vehicle Weight";
CM_ SG_ 2499635454 GrossCombinationWeight "Total weight of the truck and all the trailers with on-board scales.…";
CM_ SG_ 2499635454 NetVehicleWeightChange "Identifies the net vehicle weight change from the time of last vehicle net weight zeroing.…";
CM_ BO_ 2499635966 "Axle Group Weight";
CM_ SG_ 2499635966 AdditionalAxleGroupLocation "Location of the axle group, listed from front of the vehicle to rear.  If the value of SPN 4073 is 15, then this SPN is used to indicate the axle group referred…";
CM_ SG_ 2499635966 AxleGroupLocation "Specific axle group used in conjunction with and when communicating the axle group weight, listed from the front of the vehicle to the rear.If the value of SPN …";
CM_ SG_ 2499635966 AxleGroupWeight "Total mass imposed on the road surface by all the tires in the axle group…";
CM_ BO_ 2499641854 "EGR Cooler Bypass";
CM_ SG_ 2499641854 EExstGsRt1CBpssAttPst "The parameter gives the % open of the exhaust gas recirculation cooler bypass actuator, where 0% = Fully Closed (no gas flowing through the bypass), and 100% = …";
CM_ BO_ 2550660862 "General Purpose Valve Pressure";
CM_ SG_ 2550660862 ValveAssemblyLoadsensePressure "The maximum pressure of a valve assembly's current collective load sense pressures where a valve assembly can consist of two or more valves.…";
CM_ SG_ 2550660862 ValveAssemblySupplyPressure "Pressure of the hydraulic supply port to a valve assembly.…";
CM_ SG_ 2550660862 ValveLoadSensePressure "The maximum of the currently measured pressures of a valve's work port A and work port B.…";
CM_ SG_ 2550660862 ValvePilotPressure "Pressure of a valve's pilot supply port.…";
CM_ BO_ 2550988542 "Electronic Engine Controller 16";
CM_ SG_ 2550988542 EngineClutchEngageRequestStatus "Indicates if the engine has an external request to establish its operating conditions to be appropriate for engagement of the transmission or gearbox.00b = Engi…";
CM_ SG_ 2550988542 ReadyForClutchEngagementStatus "Indicates the engine operating conditions are appropriate for engagement of the transmission or gearbox clutch.00b = Engine Not Ready For Clutch Engagement01b =…";
CM_ SG_ 2550988542 AcceleratorPedal3Position "The ratio of actual position of the third analog engine speed/torque request input device (such as an accelerator pedal or throttle lever) to the maximum positi…";
CM_ BO_ 2557214462 "Well Stimulation Pump Sensor Calibration Command";
CM_ SG_ 2557214462 WSttPpDsPssCtStPtCd "Specifies the current discharge pressure whose calibration status is being reported. Multipoint calibration of the discharge pressure system is perfomed by incr…";
CM_ SG_ 2557214462 WSttPpStPssCtStPtCd "Specifies the current suction pressure being calibrated. Multipoint calibration of the suction pressuresystem is perfomed by increasing the pressure with up to …";
CM_ BO_ 2557345534 "Well Stimulation Pump System Configuration Command";
CM_ SG_ 2557345534 WllStmltnPmpPlngrFrngOrdr "Well stimulation pump plunger firing order0000b = Firing order 1-2-30001b = Firing order 1-5-2-3-40010b = Reserved0011b = Reserved0100b = Reserved0101b = Reserv…";
CM_ SG_ 2557345534 WllStmltnPmpRdLdHghThrshld "Rod load force at which the rod load is considered at the highest acceptable force.…";
CM_ SG_ 2557345534 WllStmltnPmpStnPrssrHghThrshld "Pressure at which the suction pressure is considered at the highest acceptable pressure.…";
CM_ SG_ 2557345534 WllStmltnPmpStnPrssrLwThrshld "Pressure at which the suction pressure is considered at the lowest acceptable pressure.…";
CM_ SG_ 2557345534 WSttPpCstSpdHTsd "Well stimulation pump crankshaft speed that has been considered to be the highest acceptable speed.…";
CM_ SG_ 2557345534 WSttPpCstSpdLwTsd "The minimum speed of Well stimulation pump crankshaft that is considered to be valid.…";
CM_ SG_ 2557345534 WSttPpDsPssHTsd "Pressure at which the discharge pressure is considered at the highest acceptable pressure.…";
CM_ SG_ 2557345534 WSttPpGBxOPssHTsd "Pressure at which the gearbox oil pressure is considered at the highest acceptable pressure.…";
CM_ SG_ 2557345534 WSttPpGBxOPssLwTsd "Pressure at which the gearbox oil pressure is considered at the lowest acceptable pressure.…";
CM_ SG_ 2557345534 WSttPpGBxOTptHTsd "Temperature at which the gearbox oil temperature is considered at the highest acceptable temperature.…";
CM_ SG_ 2557345534 WSttPpGBxOTptLwTsd "Temperature at which the gearbox oil temperature is considered at the lowest acceptable temperature.…";
CM_ BO_ 2557673214 "Oil Debris Monitor Configuration Command";
CM_ SG_ 2557673214 OlDrsMntrCnfgrtnIdntftnNmr "Identification number of the Oil Debris Monitoring (ODM) sensor being configured. Identification numbers are application specific.…";
CM_ SG_ 2557673214 OlDrsMntrFrrsBn1CntCmmnd "New starting value for total count of particles detected in Ferrous bin 1.NOTE: The value FFFFFFh indicates Do Not Change (i.e. the current count value of the O…";
CM_ SG_ 2557673214 OlDrsMntrFrrsBn2CntCmmnd "New starting value for total count of particles detected in Ferrous bin 2.NOTE: The value FFFFFFh indicates Do Not Change (i.e. the current count value of the O…";
CM_ SG_ 2557673214 OlDrsMntrFrrsBn3CntCmmnd "New starting value for total count of particles detected in Ferrous bin 3.NOTE: The value FFFFFFh indicates Do Not Change (i.e. the current count value of the O…";
CM_ SG_ 2557673214 OlDrsMntrFrrsBn4CntCmmnd "New starting value for total count of particles detected in Ferrous bin 4.NOTE: The value FFFFFFh indicates Do Not Change (i.e. the current count value of the O…";
CM_ SG_ 2557673214 OlDrsMntrFrrsBn5CntCmmnd "New starting value for total count of particles detected in Ferrous bin 5.NOTE: The value FFFFFFh indicates Do Not Change (i.e. the current count value of the O…";
CM_ SG_ 2557673214 OlDrsMntrFrrsBn6CntCmmnd "New starting value for total count of particles detected in Ferrous bin 6.NOTE: The value FFFFFFh indicates Do Not Change (i.e. the current count value of the O…";
CM_ SG_ 2557673214 OlDrsMntrNnFrrsBn1CntCmmnd "New starting value for total count of particles detected in Non-Ferrous bin 1.NOTE: The value FFFFFFh indicates Do Not Change (i.e. the current count value of t…";
CM_ SG_ 2557673214 OlDrsMntrNnFrrsBn2CntCmmnd "New starting value for total count of particles detected in Non-Ferrous bin 2.NOTE: The value FFFFFFh indicates Do Not Change (i.e. the current count value of t…";
CM_ SG_ 2557673214 OlDrsMntrNnFrrsBn3CntCmmnd "New starting value for total count of particles detected in Non-Ferrous bin 3.NOTE: The value FFFFFFh indicates Do Not Change (i.e. the current count value of t…";
CM_ SG_ 2557673214 OlDrsMntrNnFrrsBn4CntCmmnd "New starting value for total count of particles detected in Non-Ferrous bin 4.NOTE: The value FFFFFFh indicates Do Not Change (i.e. the current count value of t…";
CM_ SG_ 2557673214 OlDrsMntrNnFrrsBn5CntCmmnd "New starting value for total count of particles detected in Non-Ferrous bin 5.NOTE: The value FFFFFFh indicates Do Not Change (i.e. the current count value of t…";
CM_ SG_ 2557673214 OlDrsMntrNnFrrsBn6CntCmmnd "New starting value for total count of particles detected in Non-Ferrous bin 6.NOTE: The value FFFFFFh indicates Do Not Change (i.e. the current count value of t…";
CM_ BO_ 2557738750 "Electrified Accessory Propulsion Motor Coolant Fan 3 Command";
CM_ SG_ 2557738750 PrplsnMtrClntFn3EnlCmmnd "Enable and direction command to the Propulsion Motor Coolant Fan 3.00b = Accessory Motor Off01b = Accessory Motor On Normal/Default Direction10b = Accessory Mot…";
CM_ SG_ 2557738750 PrplsnMtrClntFn3PrntSpdCmmnd "Speed command to the Propulsion Motor Coolant Fan 3 in percentage of maximum speed.Note: Both Speed Command and Percent Speed Command cannot be used at the same…";
CM_ SG_ 2557738750 PrplsnMtrClntFn3PwrHld "Command to allow the Propulsion Motor Coolant Fan 3 to remain alive independently of the electrical enable input to the Accessory Motor.  For example, this coul…";
CM_ SG_ 2557738750 PrplsnMtrClntFn3SpdCmmnd "Speed command to the Propulsion Motor Coolant Fan 3.Note: Both Speed Command and Percent Speed Command cannot be used at the same time.  Always set the unused s…";
CM_ BO_ 2557804286 "Electrified Accessory Propulsion Motor Coolant Fan 2 Command";
CM_ SG_ 2557804286 PrplsnMtrClntFn2EnlCmmnd "Enable and direction command to the Power Motor Coolant Fan 2.00b = Accessory Motor Off01b = Accessory Motor On Normal/Default Direction10b = Accessory Motor On…";
CM_ SG_ 2557804286 PrplsnMtrClntFn2PrntSpdCmmnd "Speed command to the Propulsion Motor Coolant Fan 2 in percentage of maximum speed.Note: Both Speed Command and Percent Speed Command cannot be used at the same…";
CM_ SG_ 2557804286 PrplsnMtrClntFn2PwrHld "Command to allow the Propulsion Motor Coolant Fan 2 to remain alive independently of the electrical enable input to the Accessory Motor.  For example, this coul…";
CM_ SG_ 2557804286 PrplsnMtrClntFn2SpdCmmnd "Speed command to the Propulsion Motor Coolant Fan 2.Note: Both Speed Command and Percent Speed Command cannot be used at the same time.  Always set the unused s…";
CM_ BO_ 2557869822 "Electrified Accessory Propulsion Motor Coolant Fan 1 Command";
CM_ SG_ 2557869822 PrplsnMtrClntFn1EnlCmmnd "Enable and direction command to the Propulsion Motor Coolant Fan 1.00b = Accessory Motor Off01b = Accessory Motor On Normal/Default Direction10b = Accessory Mot…";
CM_ SG_ 2557869822 PrplsnMtrClntFn1PrntSpdCmmnd "Speed command to the Propulsion Motor Coolant Fan 1 in percentage of maximum speed.Note: Both Speed Command and Percent Speed Command cannot be used at the same…";
CM_ SG_ 2557869822 PrplsnMtrClntFn1PwrHld "Command to allow the Propulsion Motor Coolant Fan 1 to remain alive independently of the electrical enable input to the Accessory Motor.  For example, this coul…";
CM_ SG_ 2557869822 PrplsnMtrClntFn1SpdCmmnd "Speed command to the Propulsion Motor Coolant Fan 1.Note: Both Speed Command and Percent Speed Command cannot be used at the same time.  Always set the unused s…";
CM_ BO_ 2557935358 "Electrified Accessory Power Electronics Coolant Fan 3 Command";
CM_ SG_ 2557935358 PwrEltrnsClntFn3EnlCmmnd "Enable and direction command to the Power Electonics Coolant Fan 3.00b = Accessory Motor Off01b = Accessory Motor On Normal/Default Direction10b = Accessory Mot…";
CM_ SG_ 2557935358 PwrEltrnsClntFn3PrntSpdCmmnd "Speed command to the Power Electronics Coolant Fan 3 in percentage of maximum speed.Note: Both Speed Command and Percent Speed Command cannot be used at the sam…";
CM_ SG_ 2557935358 PwrEltrnsClntFn3PwrHld "Command to allow the Power Electronics Coolant Fan 3 to remain alive independently of the electrical enable input to the Accessory Motor.  For example, this cou…";
CM_ SG_ 2557935358 PwrEltrnsClntFn3SpdCmmnd "Speed command to the Power Electronics Coolant Fan 3.Note: Both Speed Command and Percent Speed Command cannot be used at the same time.  Always set the unused …";
CM_ BO_ 2558000894 "Electrified Accessory Power Electronics Coolant Fan 2 Command";
CM_ SG_ 2558000894 PwrEltrnsClntFn2EnlCmmnd "Enable and direction command to the Power Electonics Coolant Fan 2.00b = Accessory Motor Off01b = Accessory Motor On Normal/Default Direction10b = Accessory Mot…";
CM_ SG_ 2558000894 PwrEltrnsClntFn2PrntSpdCmmnd "Speed command to the Power Electronics Coolant Fan 2 in percentage of maximum speed.Note: Both Speed Command and Percent Speed Command cannot be used at the sam…";
CM_ SG_ 2558000894 PwrEltrnsClntFn2PwrHld "Command to allow the Power Electronics Coolant Fan 2 to remain alive independently of the electrical enable input to the Accessory Motor.  For example, this cou…";
CM_ SG_ 2558000894 PwrEltrnsClntFn2SpdCmmnd "Speed command to the Power Electronics Coolant Fan 2.Note: Both Speed Command and Percent Speed Command cannot be used at the same time.  Always set the unused …";
CM_ BO_ 2558066430 "Electrified Accessory Power Electronics Coolant Fan 1 Command";
CM_ SG_ 2558066430 PwrEltrnsClntFn1EnlCmmnd "Enable and direction command to the Power Electonics Coolant Fan 1.00b = Accessory Motor Off01b = Accessory Motor On Normal/Default Direction10b = Accessory Mot…";
CM_ SG_ 2558066430 PwrEltrnsClntFn1PrntSpdCmmnd "Speed command to the Power Electronics Coolant Fan 1 in percentage of maximum speed.Note: Both Speed Command and Percent Speed Command cannot be used at the sam…";
CM_ SG_ 2558066430 PwrEltrnsClntFn1PwrHld "Command to allow the Power Electronics Coolant Fan 1 to remain alive independently of the electrical enable input to the Accessory Motor.  For example, this cou…";
CM_ SG_ 2558066430 PwrEltrnsClntFn1SpdCmmnd "Speed command to the Power Electronics Coolant Fan 1.Note: Both Speed Command and Percent Speed Command cannot be used at the same time.  Always set the unused …";
CM_ BO_ 2558131966 "Electrified Accessory Propulsion Motor Oil Pump Command";
CM_ SG_ 2558131966 PropulsionMotorOilPumpPowerHold "Command to allow the Propulsion Motor Oil Pump to remain alive independently of the electrical enable input to the Accessory Motor.  For example, this could all…";
CM_ SG_ 2558131966 PrplsnMtrOlPmpEnlCmmnd "Enable and direction command to the Propulsion Motor Oil Pump.00b = Accessory Motor Off01b = Accessory Motor On Normal/Default Direction10b = Accessory Motor On…";
CM_ SG_ 2558131966 PrplsnMtrOlPmpPrntSpdCmmnd "Speed command to the Propulsion Motor Oil Pump in percentage of maximum speed.Note: Both Speed Command and Percent Speed Command cannot be used at the same time…";
CM_ SG_ 2558131966 PrplsnMtrOlPmpSpdCmmnd "Speed command to the Propulsion Motor Oil Pump. Note: Both Speed Command and Percent Speed Command cannot be used at the same time.  Always set the unused speed…";
CM_ BO_ 2558197502 "Electrified Accessory Propulsion Motor Coolant Pump Command";
CM_ SG_ 2558197502 PrplsnMtrClntPmpEnlCmmnd "Enable and direction command to the Propulsion Motor Coolant Pump.00b = Accessory Motor Off01b = Accessory Motor On Normal/Default Direction10b = Accessory Moto…";
CM_ SG_ 2558197502 PrplsnMtrClntPmpPrntSpdCmmnd "Speed command to the Propulsion Motor Coolant Pump in percentage of maximum speed.Note: Both Speed Command and Percent Speed Command cannot be used at the same …";
CM_ SG_ 2558197502 PrplsnMtrClntPmpPwrHld "Command to allow the Propulsion Motor Coolant Pump to remain alive independently of the electrical enable input to the Accessory Motor.  For example, this could…";
CM_ SG_ 2558197502 PrplsnMtrClntPmpSpdCmmnd "Speed command to the Propulsion Motor Coolant Pump. Note: Both Speed Command and Percent Speed Command cannot be used at the same time.  Always set the unused s…";
CM_ BO_ 2558263038 "Electrified Accessory Power Electronics Coolant Pump Command";
CM_ SG_ 2558263038 PwrEltrnsClntPmpEnlCmmnd "Enable and direction command to the Power Electonics Coolant Pump.00b = Accessory Motor Off01b = Accessory Motor On Normal/Default Direction10b = Accessory Moto…";
CM_ SG_ 2558263038 PwrEltrnsClntPmpPrntSpdCmmnd "Speed command to the Power Electronics Coolant Pump in percentage of maximum speed.Note: Both Speed Command and Percent Speed Command cannot be used at the same…";
CM_ SG_ 2558263038 PwrEltrnsClntPmpPwrHld "Command to allow the Power Electronics Coolant Pump to remain alive independently of the electrical enable input to the Accessory Motor.  For example, this coul…";
CM_ SG_ 2558263038 PwrEltrnsClntPmpSpdCmmnd "Speed command to the Power Electronics Coolant Pump.Note: Both Speed Command and Percent Speed Command cannot be used at the same time.  Always set the unused s…";
CM_ BO_ 2558394110 "Electrified Accessory Motor Command";
CM_ SG_ 2558394110 EltrfdAssrMtrEnlCmmnd "Enable and direction command to this electrified Accessory Motor.00b = Accessory Motor Off01b = Accessory Motor On Normal/Default Direction10b = Accessory Motor…";
CM_ SG_ 2558394110 EltrfdAssrMtrPrntSpdCmmnd "Speed command to this Electrified Accessory Motor in percentage of maximum speed.Note: Both Speed Command and Percent Speed Command cannot be used at the same t…";
CM_ SG_ 2558394110 EltrfdAssrMtrPwrHld "Command to allow this Electrified Accessory Motor to remain alive independently of the electrical enable input to the Accessory Motor.  For example, this could …";
CM_ SG_ 2558394110 EltrfdAssrMtrSpdCmmnd "Speed command to this Electrified Accessory Motor.  Note: Both Speed Command and Percent Speed Command cannot be used at the same time.  Always set the unused s…";
CM_ SG_ 2558394110 ElectrifiedAccessoryMotor1 "Indicates this instance of the Electrified Accessory Motor.  Multiple instances can be controlled with the same command PGN by setting each unique instance para…";
CM_ SG_ 2558394110 ElectrifiedAccessoryMotor2 "Indicates this instance of the Electrified Accessory Motor.  Multiple instances can be controlled with the same command PGN by setting each unique instance para…";
CM_ SG_ 2558394110 ElectrifiedAccessoryMotor3 "Indicates this instance of the Electrified Accessory Motor.  Multiple instances can be controlled with the same command PGN by setting each unique instance para…";
CM_ SG_ 2558394110 ElectrifiedAccessoryMotor4 "Indicates this instance of the Electrified Accessory Motor.  Multiple instances can be controlled with the same command PGN by setting each unique instance para…";
CM_ SG_ 2558394110 ElectrifiedAccessoryMotor5 "Indicates this instance of the Electrified Accessory Motor.  Multiple instances can be controlled with the same command PGN by setting each unique instance para…";
CM_ SG_ 2558394110 ElectrifiedAccessoryMotor6 "Indicates this instance of the Electrified Accessory Motor.  Multiple instances can be controlled with the same command PGN by setting each unique instance para…";
CM_ SG_ 2558394110 ElectrifiedAccessoryMotor7 "Indicates this instance of the Electrified Accessory Motor.  Multiple instances can be controlled with the same command PGN by setting each unique instance para…";
CM_ SG_ 2558394110 ElectrifiedAccessoryMotor8 "Indicates this instance of the Electrified Accessory Motor.  Multiple instances can be controlled with the same command PGN by setting each unique instance para…";
CM_ SG_ 2558394110 ElectrifiedAccessoryMotor9 "Indicates this instance of the Electrified Accessory Motor.  Multiple instances can be controlled with the same command PGN by setting each unique instance para…";
CM_ SG_ 2558394110 ElectrifiedAccessoryMotor10 "Indicates this instance of the Electrified Accessory Motor.  Multiple instances can be controlled with the same command PGN by setting each unique instance para…";
CM_ SG_ 2558394110 ElectrifiedAccessoryMotor11 "Indicates this instance of the Electrified Accessory Motor.  Multiple instances can be controlled with the same command PGN by setting each unique instance para…";
CM_ SG_ 2558394110 ElectrifiedAccessoryMotor12 "Indicates this instance of the Electrified Accessory Motor.  Multiple instances can be controlled with the same command PGN by setting each unique instance para…";
CM_ SG_ 2558394110 ElectrifiedAccessoryMotor13 "Indicates this instance of the Electrified Accessory Motor.  Multiple instances can be controlled with the same command PGN by setting each unique instance para…";
CM_ SG_ 2558394110 ElectrifiedAccessoryMotor14 "Indicates this instance of the Electrified Accessory Motor.  Multiple instances can be controlled with the same command PGN by setting each unique instance para…";
CM_ SG_ 2558394110 ElectrifiedAccessoryMotor15 "Indicates this instance of the Electrified Accessory Motor.  Multiple instances can be controlled with the same command PGN by setting each unique instance para…";
CM_ BO_ 2558459646 "Engine Speed Ramp Rate Boundary Request";
CM_ SG_ 2558459646 RqstdEngnSpdAlrtnRtLmt "This parameter is intended to be received by a device sending speed commands to an engine (e.g. TSC1 or proprietary command). The sending device should issue sp…";
CM_ SG_ 2558459646 RqstdEngnSpdDlrtnRtLmt "This parameter is intended to be received by a device sending speed commands to an engine (e.g. TSC1 or proprietary command). The sending device should issue sp…";
CM_ BO_ 2558525182 "Tire Sensor Identification Command";
CM_ SG_ 2558525182 NumberofTireSensors "Total count of monitored tire sensor identification numbers represented in this instance of the parameter group.…";
CM_ SG_ 2558525182 TireLocation "The location of monitored tire that corresponds with the tire sensor identification number SPN 7586. In order to specify the monitored tire by tire number, use …";
CM_ SG_ 2558525182 TireNumber "The number of the monitored tire that corresponds with the tire sensor identification number SPN 7586. In order to specify the monitored tire by location, use t…";
CM_ SG_ 2558525182 TireSensorIdentificationNumber "The identification number of tire sensor for the tire specified in the tire sensor tire number (SPN 7584) or tire sensor location (SPN 7585).…";
CM_ BO_ 2558590718 "Hybrid System Control 1";
CM_ SG_ 2558590718 ExtrnlEnrgSrCnntnDmnd "External Energy Source Connection Demand indicates how the hybrid system should engage with the external energy source that is temporarily connected to the vehi…";
CM_ SG_ 2558590718 HrdSstmPrplsnDslRqst "Indicates the Hybrid System Disable Request state.  The signal gives network controllers the ability to disable the propulsion aspect of hybrid system operation…";
CM_ SG_ 2558590718 HrdSstmPrttnOvrrdRqst "Indicates the hybrid system protection override request state.  This request allows overriding of hybrid system protection features and failure modes allowing h…";
CM_ SG_ 2558590718 HrdSstmRgnrtvBrkngDslRqst "Indicates the hybrid system regenerative braking disable request state.  This signal gives network controllers the ability to disable all regenerative braking. …";
CM_ SG_ 2558590718 HybridPropulsionModeRequest "Hybrid Propulsion Mode Request is the operator intended propulsion mode.  This parameter can be from only one source on the vehicle.  Response to this request c…";
CM_ SG_ 2558590718 HybridSystemShutdownCommand "Indicates the Hybrid System Shutdown Request state.  The signal gives network controllers the ability to disable all hybrid system functionality including propu…";
CM_ SG_ 2558590718 OperatorVehicleModeRequest "Operator Vehicle Mode Request is the operator intended vehicle mode.  This parameter can be from only one source on the vehicle.  In the case of a Diesel-Electr…";
CM_ SG_ 2558590718 StrdEnrgSrChrgDshrgRtRqst "Stored Energy Source Charge/Discharge Rate Request is used to control the rate at which the stored energy is changed in Energy Increasing or Energy Depleting mo…";
CM_ SG_ 2558590718 StrdEnrgSrStPntRqst "Stored Energy Source Set Point Request is used to set the percentage that the Stored Energy Source should be managed to by the system.A value of FBh indicates a…";
CM_ SG_ 2558590718 HVESChargeConsent "Indicates the sender’s consent to charge the system’s HVES (high-voltage energy storage) from EVSE (electric vehicle supply equipment), i.e. offboard vehicle ch…";
CM_ SG_ 2558590718 HrdPrplsnMdRqstdMxmmSpd "The requested maximum speed for the vehicle while in a Hybrid Propulsion Mode (see SPN 7889) other than Mode 1 - Stored Energy Source Sustaining.This shall be t…";
CM_ SG_ 2558590718 HrdPrplsnMdRqstdDstn "The requested distance to maintain a Hybrid Propulsion Mode (see SPN 7889) other than Mode 1 - Stored Energy Source Sustaining.When the distance is met, or a pr…";
CM_ BO_ 2558656254 "Aftertreatment System Control";
CM_ SG_ 2558656254 AftrtrtmntDslExhstFldDsrRdStts "Indicates the aftertreatment systems operating conditions are appropriate for dosing.Note: Operating conditions may include but not limited to Diesel Exhaust Fl…";
CM_ SG_ 2558656254 AftrtrtmntSstmEnlStts "Indicates that the aftertreatment system is enabled or disabled.  Enabled indicates the system will dose at regular intervals.00b = Aftertreatment System is Dis…";
CM_ SG_ 2558656254 AftrtrtmntThrmlMngmntInhtRqst "Provides state of inhibit request for Aftertreatment thermal management from external system.Aftertreatment Thermal Management indicates that the exhaust temper…";
CM_ SG_ 2558656254 RqsttPrmtDEFHdrlStffnssChk "A request to permit the DEF hydraulic stiffness check. The request continues to be broadcast until the stiffness check is finished or the corresponding permissi…";
CM_ SG_ 2558656254 RqsttPrmtSCRDsngTstInjtn "A request to permit the SCR dosing test injection. The request continues to be broadcast until the test injection is finished or the corresponding permission st…";
CM_ BO_ 2558721790 "Tire Configuration Command Information";
CM_ SG_ 2558721790 ColdInflationPressureSetting "Configurable value of the cold inflation pressure of the tire. Cold inflation pressure is the default/reference inflation pressure suggested by the manufacturer…";
CM_ SG_ 2558721790 ExtrmUndrPrssrPrntgThrshldSttng "Configurable percent deviation from the set cold inflation pressure, for the extreme under tire pressure alert.…";
CM_ SG_ 2558721790 OverTemperatureSetting "Configurable constant temperature above which an over temperature alert will trigger.…";
CM_ SG_ 2558721790 OvrPrssrPrntgThrshldSttng "Configurable percentage deviation from the set cold inflation pressure, for the over tire pressure alert.…";
CM_ SG_ 2558721790 TireLocation "The location of monitored tire on the vehicle.The high order 4 bits indicate the vehicle axle position of the tire, counting front to back on the vehicle, with …";
CM_ SG_ 2558721790 TireSensorEnableSetting "Command signal used to enable/disable the tire sensor. On receipt of this command, the tire sensor may either be enabled or disabled.00b = Off / Isolate / Disab…";
CM_ SG_ 2558721790 UndrPrssrPrntgThrshldSttng "Configurable percent deviation from the set cold inflation pressure, for the under tire pressure alert.…";
CM_ BO_ 2558787326 "Payload Calibration Information Command";
CM_ SG_ 2558787326 PayloadCorrectionFactorCommand "The payload correction factor is used to fine tune the sensor gain value.Correction factor calibration of the Payload Measurement system is performed through a …";
CM_ SG_ 2558787326 PldClrtnCmmnddWght "The true known mass of real load weight applicable for the calibration point specified in SPN 6871 and used for calibrating Payload system.Multipoint calibratio…";
CM_ SG_ 2558787326 PldClrtnStPntCmmnd "Specifies the current payload point being calibrated. The data specified in the 'Payload Calibration Commanded Weight' SPN (SPN 6872) or 'Payload Correction Fac…";
CM_ BO_ 2558852862 "Aftertreatment 1 Particulate Sensor Control";
CM_ SG_ 2558852862 Aftrtrtmnt1PrtltSnsrDwpnt "Indicates that the temperature near the particulate sensor has exceeded the dew point.00b = Dewpoint has not been reached01b = Dewpoint has been reached10b = SA…";
CM_ SG_ 2558852862 Aftrtrtmnt1PrtltSnsrExhstTmprtr "This is the temperature in the exhaust stream that is closest to the particulate sensor. This could be a calculated value or read from another sensor. The ECU t…";
CM_ SG_ 2558852862 Aftrtrtmnt1PrtltSnsrExhstVlt "Velocity of the exhaust gas near the particulate sensor.…";
CM_ SG_ 2558852862 Aftrtrtmnt1PrtltSnsrRgnrtnRqst "Another ECU would send this to request that the particulate sensor perform a regeneration of the sensor.  A request would be considered active when this paramet…";
CM_ SG_ 2558852862 Aftrtrtmnt1PrtltSnsrShtdwnRqst "Aftertreatment 1 particulate sensor shutdown request.00b = Shutdown request not active01b = Shutdown request active10b = SAE reserved11b = Not available…";
CM_ BO_ 2558918398 "Cab Message 2";
CM_ SG_ 2558918398 ActiveShiftConsoleRequest "Requests the shift console or shift selector that the operator desires to be active. See SPN 2945 (Active Shift Console Indicator) for feedback on which shift c…";
CM_ SG_ 2558918398 AftrtrtmntSstmEnlCmmnd "Request to enable Aftertreatment system.00b = De-activate Aftertreatment System01b = Activate Aftertreatment System10b = Reserved11b = Don't care/Take no Action…";
CM_ SG_ 2558918398 AttttRtESpdAwdSwt "If this parameter is 01b, then the aftertreatment control system is permitted to perform an aftertreatment regeneration, but the aftertreatment control system i…";
CM_ SG_ 2558918398 ElvtdEngnSpdAllwdSwth "Indicates the state of a switch to indicate the control system is permitted to automatically elevate the engine speed as needed for strategies such as cold mode…";
CM_ SG_ 2558918398 EngineFan2RequestedPercentSpeed "Fan speed of the second fan in the system as a ratio of the actual fan drive (current speed) to the fully engaged fan drive (maximum fan speed). A two state fan…";
CM_ SG_ 2558918398 EngineStopStartDisableCommand "Engine Stop-Start Disable Command indicates the desire to disable the engine stop-start functionality during propulsion modes. For momentary switches, this para…";
CM_ SG_ 2558918398 EngnIdlMngmntPndngEvntOvrrd "Command signal which allows the operator to override an impending engine idle management start-up or an impending engine idle management shutdown.00b = Off (not…";
CM_ SG_ 2558918398 HtExhngrDrsPrgFrSwth "Indicates the state of a switch available to the operator that forces the system to purge the debris from the heat exchanger.00b = not active01b = active10b = e…";
CM_ SG_ 2558918398 HtExhngrDrsPrgInhtSwth "Indicates the state of a switch available to the operator that will inhibit the system from purging the debris from the heat exchanger.00b = not active01b = act…";
CM_ SG_ 2558918398 PerformanceBiasSelection "Indicates the operating bias toward performance of the power source.0% Functionality is biased toward fuel economy as much as possible.50% Functionality is bias…";
CM_ SG_ 2558918398 PrdtvCrsCntrlDtvtnRqst "Indicates that the operator has requested to deactivate the predictive cruise control (PCC) function.If enabled, the PCC device may still provide notification o…";
CM_ SG_ 2558918398 PrdtvCrsCntrlEnlSwth "Indicates whether predictive cruise control (PCC) is enabled. When not enabled, the predictive cruise control does not calculate a speed offset or identify pred…";
CM_ SG_ 2558918398 PrdtvCrsCntrlMxmmNgtvOffst "Maximum speed decrease that the predictive cruise control (PCC) is allowed to request. This may be adjusted by the operator (either directly or indirectly) to t…";
CM_ SG_ 2558918398 PrdtvCrsCntrlMxmmPstvOffst "Maximum speed increase that the predictive cruise control (PCC) is allowed to request. This may be adjusted by the operator (either directly or indirectly) to t…";
CM_ SG_ 2558918398 SCROprtrIndmntOvrrdSwth "The position of the operator inducement override switch. This switch function allows the operator to override an operator inducement derate.See EU Commission di…";
CM_ SG_ 2558918398 TrnsmssnAtNtrlMnlRtrnEnlSwth "This enable switch is for optional use with interfaces using SPN 7695 [Transmission Auto-Neutral (Manual Return) Request] or another vehicle input configured fo…";
CM_ BO_ 2558983934 "Switched Power Outputs Command";
CM_ SG_ 2558983934 SwitchedPowerOutput10Command "Desired state of Switched Power Output #10. Used to set the desired state.00b = Output off01b = Output on10b = Reserved11b = Take no action…";
CM_ SG_ 2558983934 SwitchedPowerOutput11Command "Desired state of Switched Power Output #11. Used to set the desired state.00b = Output off01b = Output on10b = Reserved11b = Take no action…";
CM_ SG_ 2558983934 SwitchedPowerOutput12Command "Desired state of Switched Power Output #12. Used to set the desired state.00b = Output off01b = Output on10b = Reserved11b = Take no action…";
CM_ SG_ 2558983934 SwitchedPowerOutput13Command "Desired state of Switched Power Output #13. Used to set the desired state.00b = Output off01b = Output on10b = Reserved11b = Take no action…";
CM_ SG_ 2558983934 SwitchedPowerOutput14Command "Desired state of Switched Power Output #14. Used to set the desired state.00b = Output off01b = Output on10b = Reserved11b = Take no action…";
CM_ SG_ 2558983934 SwitchedPowerOutput15Command "Desired state of Switched Power Output #15. Used to set the desired state.00b = Output off01b = Output on10b = Reserved11b = Take no action…";
CM_ SG_ 2558983934 SwitchedPowerOutput16Command "Desired state of Switched Power Output #16. Used to set the desired state.00b = Output off01b = Output on10b = Reserved11b = Take no action…";
CM_ SG_ 2558983934 SwitchedPowerOutput17Command "Desired state of Switched Power Output #17. Used to set the desired state.00b = Output off01b = Output on10b = Reserved11b = Take no action…";
CM_ SG_ 2558983934 SwitchedPowerOutput18Command "Desired state of Switched Power Output #18. Used to set the desired state.00b = Output off01b = Output on10b = Reserved11b = Take no action…";
CM_ SG_ 2558983934 SwitchedPowerOutput19Command "Desired state of Switched Power Output #19. Used to set the desired state.00b = Output off01b = Output on10b = Reserved11b = Take no action…";
CM_ SG_ 2558983934 SwitchedPowerOutput1Command "Desired state of Switched Power Output #1. Used to set the desired state.00b = Output off01b = Output on10b = Reserved11b = Take no action…";
CM_ SG_ 2558983934 SwitchedPowerOutput20Command "Desired state of Switched Power Output #20. Used to set the desired state.00b = Output off01b = Output on10b = Reserved11b = Take no action…";
CM_ SG_ 2558983934 SwitchedPowerOutput21Command "Desired state of Switched Power Output #21. Used to set the desired state.00b = Output off01b = Output on10b = Reserved11b = Take no action…";
CM_ SG_ 2558983934 SwitchedPowerOutput22Command "Desired state of Switched Power Output #22. Used to set the desired state.00b = Output off01b = Output on10b = Reserved11b = Take no action…";
CM_ SG_ 2558983934 SwitchedPowerOutput23Command "Desired state of Switched Power Output #23. Used to set the desired state.00b = Output off01b = Output on10b = Reserved11b = Take no action…";
CM_ SG_ 2558983934 SwitchedPowerOutput24Command "Desired state of Switched Power Output #24. Used to set the desired state.00b = Output off01b = Output on10b = Reserved11b = Take no action…";
CM_ SG_ 2558983934 SwitchedPowerOutput25Command "Desired state of Switched Power Output #25. Used to set the desired state.00b = Output off01b = Output on10b = Reserved11b = Take no action…";
CM_ SG_ 2558983934 SwitchedPowerOutput26Command "Desired state of Switched Power Output #26. Used to set the desired state.00b = Output off01b = Output on10b = Reserved11b = Take no action…";
CM_ SG_ 2558983934 SwitchedPowerOutput27Command "Desired state of Switched Power Output #27. Used to set the desired state.00b = Output off01b = Output on10b = Reserved11b = Take no action…";
CM_ SG_ 2558983934 SwitchedPowerOutput28Command "Desired state of Switched Power Output #28. Used to set the desired state.00b = Output off01b = Output on10b = Reserved11b = Take no action…";
CM_ SG_ 2558983934 SwitchedPowerOutput29Command "Desired state of Switched Power Output #29. Used to set the desired state.00b = Output off01b = Output on10b = Reserved11b = Take no action…";
CM_ SG_ 2558983934 SwitchedPowerOutput2Command "Desired state of Switched Power Output #2. Used to set the desired state.00b = Output off01b = Output on10b = Reserved11b = Take no action…";
CM_ SG_ 2558983934 SwitchedPowerOutput30Command "Desired state of Switched Power Output #30. Used to set the desired state.00b = Output off01b = Output on10b = Reserved11b = Take no action…";
CM_ SG_ 2558983934 SwitchedPowerOutput31Command "Desired state of Switched Power Output #31. Used to set the desired state.00b = Output off01b = Output on10b = Reserved11b = Take no action…";
CM_ SG_ 2558983934 SwitchedPowerOutput32Command "Desired state of Switched Power Output #32. Used to set the desired state.00b = Output off01b = Output on10b = Reserved11b = Take no action…";
CM_ SG_ 2558983934 SwitchedPowerOutput3Command "Desired state of Switched Power Output #3. Used to set the desired state.00b = Output off01b = Output on10b = Reserved11b = Take no action…";
CM_ SG_ 2558983934 SwitchedPowerOutput4Command "Desired state of Switched Power Output #4. Used to set the desired state.00b = Output off01b = Output on10b = Reserved11b = Take no action…";
CM_ SG_ 2558983934 SwitchedPowerOutput5Command "Desired state of Switched Power Output #5. Used to set the desired state.00b = Output off01b = Output on10b = Reserved11b = Take no action…";
CM_ SG_ 2558983934 SwitchedPowerOutput6Command "Desired state of Switched Power Output #6. Used to set the desired state.00b = Output off01b = Output on10b = Reserved11b = Take no action…";
CM_ SG_ 2558983934 SwitchedPowerOutput7Command "Desired state of Switched Power Output #7. Used to set the desired state.00b = Output off01b = Output on10b = Reserved11b = Take no action…";
CM_ SG_ 2558983934 SwitchedPowerOutput8Command "Desired state of Switched Power Output #8. Used to set the desired state.00b = Output off01b = Output on10b = Reserved11b = Take no action…";
CM_ SG_ 2558983934 SwitchedPowerOutput9Command "Desired state of Switched Power Output #9. Used to set the desired state.00b = Output off01b = Output on10b = Reserved11b = Take no action…";
CM_ BO_ 2559049470 "Engine State Requests";
CM_ SG_ 2559049470 DesiredEngineFuelingState "Devices send this request to the engine controller to:(a) Shut off engine fueling, but remain prepared to re-start quickly by not shutting down the control syst…";
CM_ SG_ 2559049470 EngineFuelingDesiredReason "This parameter conveys the reason a device wants the engine running.This SPN is intended to be used in conjunction with Desired Engine Fueling State (SPN 5793).…";
CM_ SG_ 2559049470 EngineFuelingNotDesiredReason "This parameter conveys the reason a device wants the engine to inhibit fuelling. This SPN is intended to be used in conjunction with Desired Engine Fueling Stat…";
CM_ SG_ 2559049470 EngineGaseousFuelUsageInhibited "Used to request that the engine should not be allowed to use gaseous fuel for engine cylinder combustion. This state is relevant for dual fuel systems and would…";
CM_ SG_ 2559049470 EngineShutdownCommand "Command to shut down the engine. If this parameter is received as 01b, then the engine should behave as if the key switch was turned off. An example of how this…";
CM_ SG_ 2559049470 EngnGssFlSpplDsrdPrssr "Desired gage pressure of gaseous fuel supply to the engine.…";
CM_ SG_ 2559049470 EngnPrttnDrtOvrrdCmmnd "Command signal to override engine protection derate.This is to temporarily override an engine protection derate due to coolant temperature, oil pressure etc. Th…";
CM_ SG_ 2559049470 RequestedFuelType "Engine controller receives this request from another control module to select the type of fuel to be used for engine operation.00h = Not available - NONE01h = G…";
CM_ SG_ 2559049470 TrnsmssnIdlGvrnrFlngInht "This parameter is a command provided to the Engine Control Module (ECM) from the Transmission Control Module (TCM) to inhibit idle governor fueling in the unlik…";
CM_ BO_ 2559115006 "Radio Beacon Request";
CM_ SG_ 2559115006 RadioBeaconDirection "Indicates the function of a particular instance of the Radio Beacon Request message. The 'Beacon Request' state indicates the message is sent to a wireless tran…";
CM_ SG_ 2559115006 TransmitterID2 "The ID of the off-board transmitter that sent the incoming special beacon message received by the wireless transceiver.…";
CM_ SG_ 2559115006 UnqBnMssgIdntfrNmr "The number is used to identify a wireless message originating from a device on a particular machine. Within a beacon request message (see SPN 5755 [Radio Beacon…";
CM_ SG_ 2559115006 WirelessSignalStrength2 "The absolute received signal strength of the special beacon signal received from the off-board transmitter. The signal strength is reported as a Received Signal…";
CM_ BO_ 2559573758 "Engine Configuration Commands";
CM_ SG_ 2559573758 CtLvEPttStdwOvdCd "Overrides the engine protection shutdown functionality due to low coolant level.  00b = Disable engine protection shutdown override due to low coolant level01b …";
CM_ BO_ 2559639294 "Supplemental Fan Command";
CM_ SG_ 2559639294 SupplementalFanDirectionCommand "Direction command to the Supplemental Fan. Fan can be commanded to run forward or reverse.00b = Forward01b = Reverse10b = Reserved11b = Don't care/take no actio…";
CM_ SG_ 2559639294 SupplementalFanEnableCommand "Enable/Disable command to Supplemental Fan.00b = Disable 01b = Enable10b = Reserved 11b = Don't Care/Take no action…";
CM_ SG_ 2559639294 SupplementalFanPowerHold "Command to allow the supplemental fan controller to remain alive independently of the electrical enable input to the fan. This allows the fan controller to rema…";
CM_ SG_ 2559639294 SupplementalFanSpeedCommand "Speed command to Supplemental Fan.…";
CM_ BO_ 2559704830 "Vehicle/Chassis Lubrication System 1";
CM_ SG_ 2559704830 LrtnOprtnMdStCmmnd "Command signal to change lubrication system operational mode. The mode set command gives the operator and/or technician the ability to change the operational mo…";
CM_ SG_ 2559704830 LubricationCycleModeLockCommand "Command signal to lock or unlock the ability to change the lubrication cycle mode.  Locking the lubrication mode would prevent the changing of the lubrication c…";
CM_ SG_ 2559704830 LubricationCycleSetCommand "Command signal to change the lubrication cycle. It gives the operator or technician the ability to the change the frequency of lubrication.000b = Cycle mode # 1…";
CM_ SG_ 2559704830 LubricationPumpEnableCommand "Command signal to reset the lubrication pump.  It allows the operator and/or technician to reset the paused lubrication pump and clear lubrication system faults…";
CM_ SG_ 2559704830 LubricationTimingCycleCommand "Command signal to enable or pause the lubrication activation clock 00b = Pause01b = Enable10b = Reserved 11b = Take no action     Note:  In some vehicles or mac…";
CM_ BO_ 2559770366 "Aftertreatment 1 Hydrocarbon Doser Information 1";
CM_ SG_ 2559770366 DiagnosticStatusofHCDoser "Indicates whether an error is active in the Hydrocarbon Doser (HCD) or whether the internal cyclic system test of the HCD is presently active.  This is not inte…";
CM_ SG_ 2559770366 HCDoserInjectingStatus "Indicates whether the Hydrocarbon Doser (HCD) is presently injecting diesel fuel into the exhaust pipe.00b = Injecting not active01b = Injecting active10b = Err…";
CM_ SG_ 2559770366 HCDoserStatus "Indicates whether the HC Doser/ HC Dosing system is enabled or is waiting for regeneration.000b = HC doser disabled001b = HC doser active010b = SAE reserved011b…";
CM_ SG_ 2559770366 HydrocarbonDoserPurgingRequired "Purging of the Hydrocarbon Doser (HCD) is required.  Request could come from the HCD system.00b = Purging not required01b = Purging required - less urgent10b = …";
CM_ SG_ 2559770366 RequestedFuelMassRate "Requested fuel dosing quantity from hydrocarbon doser.…";
CM_ SG_ 2559770366 Aftertreatment1DPFHydrocarbon "Accumulated unburned fuel in the DPF.  0% = no unburned fuel in DPF, 100% = maximum recommended capacity of unburned fuel in DPF.…";
CM_ BO_ 2559901438 "Aftertreatment 1 Diesel Particulate Filter Soot Sensor Calibration";
CM_ SG_ 2559901438 Atttt1DsPttFtStMCtOst "Calibration offset for the soot Mean for Aftertreatment 1 Diesel Particulate Filter soot sensor.…";
CM_ SG_ 2559901438 Atttt1DsPttFtStStddDvtCtOst "Calibration offset for the soot standard deviation for Aftertreatment 1 Diesel Particulate Filter soot sensor.…";
CM_ BO_ 2559966974 "Aftertreatment 2 Diesel Particulate Filter Soot Sensor Calibration";
CM_ SG_ 2559966974 Atttt2DsPttFtStMCtOst "Calibration offset for the soot Mean for Aftertreatment 2 Diesel Particulate Filter soot sensor.…";
CM_ SG_ 2559966974 Atttt2DsPttFtStStddDvtCtOst "Calibration offset for the soot standard deviation for Aftertreatment 2 Diesel Particulate Filter soot sensor.…";
CM_ BO_ 2560032510 "Low Voltage Disconnect Set Operating Mode";
CM_ SG_ 2560032510 LwVltgDsnntDsrdOprtngMd "Desired Operating Mode of the LVD.  Used to issue a J1939 request to the LVD to change modes.0000b = Automatic0001b to 0011b = Reserved0100b = Manual Disconnect…";
CM_ BO_ 2560098046 "Noise Control Status";
CM_ SG_ 2560098046 CabNoiseControlStatus "This parameter returns the current status of the Cab Noise Control system.00b = Cab Noise Control System ON-Line01b = Cab Noise Control System OFF-Line10b = Err…";
CM_ SG_ 2560098046 CabNoiseControlTuningStatus "This parameter returns the current status of tuning function of the Cab Noise Control system.    When the tuning state is active, the Cab Noise Control System a…";
CM_ BO_ 2560163582 "Noise Control 1";
CM_ SG_ 2560163582 CabNoiseControlCommand "Command signal to change the state of the Cab Noise Control System to on-line or off-line00b = Take Cab Noise Control System Off Line01b = Bring Cab Noise Contr…";
CM_ SG_ 2560163582 CabNoiseControlTuningCommand "Command values for the Tuning State of the Cab Noise Control System.  The Tuning State allows the Cab Noise Control System to adjust certain system characterist…";
CM_ BO_ 2560360190 "Proprietary Method Identification";
CM_ SG_ 2560360190 DataDictionaryManufacturerCode "The J1939 Manufacturer Code (see J1939 Table B10) associated with the manufacturer who defined the proprietary communications method.  7FFh reserved for Not Ava…";
CM_ SG_ 2560360190 DataDictionaryMethod "A manufacturer defined code to define the proprietary communications method.  The structure and interpretation of the code is manufacturer specific.  This allow…";
CM_ BO_ 2560425726 "Auxiliary Input/Output Status 7";
CM_ SG_ 2560425726 AuxiliaryIOChannel15 "Identifies the current value of auxiliary input/output channels that are configured uniquely per application.…";
CM_ SG_ 2560425726 AuxiliaryIOChannel16 "Identifies the current value of auxiliary input/output channels that are configured uniquely per application.…";
CM_ SG_ 2560425726 AuxiliaryIOChannel17 "Identifies the current value of auxiliary input/output channels that are configured uniquely per application.…";
CM_ SG_ 2560425726 AuxiliaryIOChannel18 "Identifies the current value of auxiliary input/output channels that are configured uniquely per application.…";
CM_ SG_ 2560425726 AuxiliaryIOChannel19 "Identifies the current value of auxiliary input/output channels that are configured uniquely per application.…";
CM_ SG_ 2560425726 AuxiliaryIOChannel20 "Identifies the current value of auxiliary input/output channels that are configured uniquely per application.…";
CM_ SG_ 2560425726 AuxiliaryIOChannel21 "Identifies the current value of auxiliary input/output channels that are configured uniquely per application.…";
CM_ SG_ 2560425726 AuxiliaryIOChannel22 "Identifies the current value of auxiliary input/output channels that are configured uniquely per application.…";
CM_ BO_ 2560491262 "Auxiliary Input/Output Status 6";
CM_ SG_ 2560491262 AuxiliaryIOChannel10 "Identifies the current value of auxiliary input/output channels that are configured uniquely per application.…";
CM_ SG_ 2560491262 AuxiliaryIOChannel11 "Identifies the current value of auxiliary input/output channels that are configured uniquely per application.…";
CM_ SG_ 2560491262 AuxiliaryIOChannel12 "Identifies the current value of auxiliary input/output channels that are configured uniquely per application.…";
CM_ SG_ 2560491262 AuxiliaryIOChannel13 "Identifies the current value of auxiliary input/output channels that are configured uniquely per application.…";
CM_ SG_ 2560491262 AuxiliaryIOChannel14 "Identifies the current value of auxiliary input/output channels that are configured uniquely per application.…";
CM_ SG_ 2560491262 AuxiliaryIOChannel7 "Identifies the current value of auxiliary input/output channels that are configured uniquely per application.…";
CM_ SG_ 2560491262 AuxiliaryIOChannel8 "Identifies the current value of auxiliary input/output channels that are configured uniquely per application.…";
CM_ SG_ 2560491262 AuxiliaryIOChannel9 "Identifies the current value of auxiliary input/output channels that are configured uniquely per application.…";
CM_ BO_ 2561015550 "Auxiliary Input/Output Status 4";
CM_ SG_ 2561015550 AuxiliaryIO100 "Identifies the current status of auxiliary input/output functions that are configured uniquely per application.00b = Auxiliary channel off01b = Auxiliary channe…";
CM_ SG_ 2561015550 AuxiliaryIO101 "Identifies the current status of auxiliary input/output functions that are configured uniquely per application.00b = Auxiliary channel off01b = Auxiliary channe…";
CM_ SG_ 2561015550 AuxiliaryIO102 "Identifies the current status of auxiliary input/output functions that are configured uniquely per application.00b = Auxiliary channel off01b = Auxiliary channe…";
CM_ SG_ 2561015550 AuxiliaryIO103 "Identifies the current status of auxiliary input/output functions that are configured uniquely per application.00b = Auxiliary channel off01b = Auxiliary channe…";
CM_ SG_ 2561015550 AuxiliaryIO104 "Identifies the current status of auxiliary input/output functions that are configured uniquely per application.00b = Auxiliary channel off01b = Auxiliary channe…";
CM_ SG_ 2561015550 AuxiliaryIO105 "Identifies the current status of auxiliary input/output functions that are configured uniquely per application.00b = Auxiliary channel off01b = Auxiliary channe…";
CM_ SG_ 2561015550 AuxiliaryIO106 "Identifies the current status of auxiliary input/output functions that are configured uniquely per application.00b = Auxiliary channel off01b = Auxiliary channe…";
CM_ SG_ 2561015550 AuxiliaryIO107 "Identifies the current status of auxiliary input/output functions that are configured uniquely per application.00b = Auxiliary channel off01b = Auxiliary channe…";
CM_ SG_ 2561015550 AuxiliaryIO108 "Identifies the current status of auxiliary input/output functions that are configured uniquely per application.00b = Auxiliary channel off01b = Auxiliary channe…";
CM_ SG_ 2561015550 AuxiliaryIO109 "Identifies the current status of auxiliary input/output functions that are configured uniquely per application.00b = Auxiliary channel off01b = Auxiliary channe…";
CM_ SG_ 2561015550 AuxiliaryIO110 "Identifies the current status of auxiliary input/output functions that are configured uniquely per application.00b = Auxiliary channel off01b = Auxiliary channe…";
CM_ SG_ 2561015550 AuxiliaryIO111 "Identifies the current status of auxiliary input/output functions that are configured uniquely per application.00b = Auxiliary channel off01b = Auxiliary channe…";
CM_ SG_ 2561015550 AuxiliaryIO112 "Identifies the current status of auxiliary input/output functions that are configured uniquely per application.00b = Auxiliary channel off01b = Auxiliary channe…";
CM_ SG_ 2561015550 AuxiliaryIO81 "Identifies the current status of auxiliary input/output functions that are configured uniquely per application.00b = Auxiliary channel off01b = Auxiliary channe…";
CM_ SG_ 2561015550 AuxiliaryIO82 "Identifies the current status of auxiliary input/output functions that are configured uniquely per application.00b = Auxiliary channel off01b = Auxiliary channe…";
CM_ SG_ 2561015550 AuxiliaryIO83 "Identifies the current status of auxiliary input/output functions that are configured uniquely per application.00b = Auxiliary channel off01b = Auxiliary channe…";
CM_ SG_ 2561015550 AuxiliaryIO84 "Identifies the current status of auxiliary input/output functions that are configured uniquely per application.00b = Auxiliary channel off01b = Auxiliary channe…";
CM_ SG_ 2561015550 AuxiliaryIO85 "Identifies the current status of auxiliary input/output functions that are configured uniquely per application.00b = Auxiliary channel off01b = Auxiliary channe…";
CM_ SG_ 2561015550 AuxiliaryIO86 "Identifies the current status of auxiliary input/output functions that are configured uniquely per application.00b = Auxiliary channel off01b = Auxiliary channe…";
CM_ SG_ 2561015550 AuxiliaryIO87 "Identifies the current status of auxiliary input/output functions that are configured uniquely per application.00b = Auxiliary channel off01b = Auxiliary channe…";
CM_ SG_ 2561015550 AuxiliaryIO88 "Identifies the current status of auxiliary input/output functions that are configured uniquely per application.00b = Auxiliary channel off01b = Auxiliary channe…";
CM_ SG_ 2561015550 AuxiliaryIO89 "Identifies the current status of auxiliary input/output functions that are configured uniquely per application.00b = Auxiliary channel off01b = Auxiliary channe…";
CM_ SG_ 2561015550 AuxiliaryIO90 "Identifies the current status of auxiliary input/output functions that are configured uniquely per application.00b = Auxiliary channel off01b = Auxiliary channe…";
CM_ SG_ 2561015550 AuxiliaryIO91 "Identifies the current status of auxiliary input/output functions that are configured uniquely per application.00b = Auxiliary channel off01b = Auxiliary channe…";
CM_ SG_ 2561015550 AuxiliaryIO92 "Identifies the current status of auxiliary input/output functions that are configured uniquely per application.00b = Auxiliary channel off01b = Auxiliary channe…";
CM_ SG_ 2561015550 AuxiliaryIO93 "Identifies the current status of auxiliary input/output functions that are configured uniquely per application.00b = Auxiliary channel off01b = Auxiliary channe…";
CM_ SG_ 2561015550 AuxiliaryIO94 "Identifies the current status of auxiliary input/output functions that are configured uniquely per application.00b = Auxiliary channel off01b = Auxiliary channe…";
CM_ SG_ 2561015550 AuxiliaryIO95 "Identifies the current status of auxiliary input/output functions that are configured uniquely per application.00b = Auxiliary channel off01b = Auxiliary channe…";
CM_ SG_ 2561015550 AuxiliaryIO96 "Identifies the current status of auxiliary input/output functions that are configured uniquely per application.00b = Auxiliary channel off01b = Auxiliary channe…";
CM_ SG_ 2561015550 AuxiliaryIO97 "Identifies the current status of auxiliary input/output functions that are configured uniquely per application.00b = Auxiliary channel off01b = Auxiliary channe…";
CM_ SG_ 2561015550 AuxiliaryIO98 "Identifies the current status of auxiliary input/output functions that are configured uniquely per application.00b = Auxiliary channel off01b = Auxiliary channe…";
CM_ SG_ 2561015550 AuxiliaryIO99 "Identifies the current status of auxiliary input/output functions that are configured uniquely per application.00b = Auxiliary channel off01b = Auxiliary channe…";
CM_ BO_ 2561081086 "Auxiliary Input/Output Status 3";
CM_ SG_ 2561081086 AuxiliaryIO49 "Identifies the current status of auxiliary input/output functions that are configured uniquely per application.00b = Auxiliary channel off01b = Auxiliary channe…";
CM_ SG_ 2561081086 AuxiliaryIO50 "Identifies the current status of auxiliary input/output functions that are configured uniquely per application.00b = Auxiliary channel off01b = Auxiliary channe…";
CM_ SG_ 2561081086 AuxiliaryIO51 "Identifies the current status of auxiliary input/output functions that are configured uniquely per application.00b = Auxiliary channel off01b = Auxiliary channe…";
CM_ SG_ 2561081086 AuxiliaryIO52 "Identifies the current status of auxiliary input/output functions that are configured uniquely per application.00b = Auxiliary channel off01b = Auxiliary channe…";
CM_ SG_ 2561081086 AuxiliaryIO53 "Identifies the current status of auxiliary input/output functions that are configured uniquely per application.00b = Auxiliary channel off01b = Auxiliary channe…";
CM_ SG_ 2561081086 AuxiliaryIO54 "Identifies the current status of auxiliary input/output functions that are configured uniquely per application.00b = Auxiliary channel off01b = Auxiliary channe…";
CM_ SG_ 2561081086 AuxiliaryIO55 "Identifies the current status of auxiliary input/output functions that are configured uniquely per application.00b = Auxiliary channel off01b = Auxiliary channe…";
CM_ SG_ 2561081086 AuxiliaryIO56 "Identifies the current status of auxiliary input/output functions that are configured uniquely per application.00b = Auxiliary channel off01b = Auxiliary channe…";
CM_ SG_ 2561081086 AuxiliaryIO57 "Identifies the current status of auxiliary input/output functions that are configured uniquely per application.00b = Auxiliary channel off01b = Auxiliary channe…";
CM_ SG_ 2561081086 AuxiliaryIO58 "Identifies the current status of auxiliary input/output functions that are configured uniquely per application.00b = Auxiliary channel off01b = Auxiliary channe…";
CM_ SG_ 2561081086 AuxiliaryIO59 "Identifies the current status of auxiliary input/output functions that are configured uniquely per application.00b = Auxiliary channel off01b = Auxiliary channe…";
CM_ SG_ 2561081086 AuxiliaryIO60 "Identifies the current status of auxiliary input/output functions that are configured uniquely per application.00b = Auxiliary channel off01b = Auxiliary channe…";
CM_ SG_ 2561081086 AuxiliaryIO61 "Identifies the current status of auxiliary input/output functions that are configured uniquely per application.00b = Auxiliary channel off01b = Auxiliary channe…";
CM_ SG_ 2561081086 AuxiliaryIO62 "Identifies the current status of auxiliary input/output functions that are configured uniquely per application.00b = Auxiliary channel off01b = Auxiliary channe…";
CM_ SG_ 2561081086 AuxiliaryIO63 "Identifies the current status of auxiliary input/output functions that are configured uniquely per application.00b = Auxiliary channel off01b = Auxiliary channe…";
CM_ SG_ 2561081086 AuxiliaryIO64 "Identifies the current status of auxiliary input/output functions that are configured uniquely per application.00b = Auxiliary channel off01b = Auxiliary channe…";
CM_ SG_ 2561081086 AuxiliaryIO65 "Identifies the current status of auxiliary input/output functions that are configured uniquely per application.00b = Auxiliary channel off01b = Auxiliary channe…";
CM_ SG_ 2561081086 AuxiliaryIO66 "Identifies the current status of auxiliary input/output functions that are configured uniquely per application.00b = Auxiliary channel off01b = Auxiliary channe…";
CM_ SG_ 2561081086 AuxiliaryIO67 "Identifies the current status of auxiliary input/output functions that are configured uniquely per application.00b = Auxiliary channel off01b = Auxiliary channe…";
CM_ SG_ 2561081086 AuxiliaryIO68 "Identifies the current status of auxiliary input/output functions that are configured uniquely per application.00b = Auxiliary channel off01b = Auxiliary channe…";
CM_ SG_ 2561081086 AuxiliaryIO69 "Identifies the current status of auxiliary input/output functions that are configured uniquely per application.00b = Auxiliary channel off01b = Auxiliary channe…";
CM_ SG_ 2561081086 AuxiliaryIO70 "Identifies the current status of auxiliary input/output functions that are configured uniquely per application.00b = Auxiliary channel off01b = Auxiliary channe…";
CM_ SG_ 2561081086 AuxiliaryIO71 "Identifies the current status of auxiliary input/output functions that are configured uniquely per application.00b = Auxiliary channel off01b = Auxiliary channe…";
CM_ SG_ 2561081086 AuxiliaryIO72 "Identifies the current status of auxiliary input/output functions that are configured uniquely per application.00b = Auxiliary channel off01b = Auxiliary channe…";
CM_ SG_ 2561081086 AuxiliaryIO73 "Identifies the current status of auxiliary input/output functions that are configured uniquely per application.00b = Auxiliary channel off01b = Auxiliary channe…";
CM_ SG_ 2561081086 AuxiliaryIO74 "Identifies the current status of auxiliary input/output functions that are configured uniquely per application.00b = Auxiliary channel off01b = Auxiliary channe…";
CM_ SG_ 2561081086 AuxiliaryIO75 "Identifies the current status of auxiliary input/output functions that are configured uniquely per application.00b = Auxiliary channel off01b = Auxiliary channe…";
CM_ SG_ 2561081086 AuxiliaryIO76 "Identifies the current status of auxiliary input/output functions that are configured uniquely per application.00b = Auxiliary channel off01b = Auxiliary channe…";
CM_ SG_ 2561081086 AuxiliaryIO77 "Identifies the current status of auxiliary input/output functions that are configured uniquely per application.00b = Auxiliary channel off01b = Auxiliary channe…";
CM_ SG_ 2561081086 AuxiliaryIO78 "Identifies the current status of auxiliary input/output functions that are configured uniquely per application.00b = Auxiliary channel off01b = Auxiliary channe…";
CM_ SG_ 2561081086 AuxiliaryIO79 "Identifies the current status of auxiliary input/output functions that are configured uniquely per application.00b = Auxiliary channel off01b = Auxiliary channe…";
CM_ SG_ 2561081086 AuxiliaryIO80 "Identifies the current status of auxiliary input/output functions that are configured uniquely per application.00b = Auxiliary channel off01b = Auxiliary channe…";
BA_DEF_ SG_  "SPN" INT 0 524287;
BA_DEF_ BO_  "VFrameFormat" ENUM  "StandardCAN","ExtendedCAN","reserved","J1939PG";
BA_DEF_DEF_  "SPN" 0;
BA_DEF_DEF_  "VFrameFormat" "J1939PG";
BA_ "SPN" SG_ 2432541694 EngnTrhrgrCmprssrBpssAttr1Cmmnd 3470;
BA_ "SPN" SG_ 2432541694 EngnTrhrgrCmprssrBpssAttr1Pstn 3675;
BA_ "SPN" SG_ 2432541694 EngnTrhrgrCmprssrBpssAttr2Cmmnd 5369;
BA_ "SPN" SG_ 2432541694 EngnVrlGmtrTrhrgrAttr1 641;
BA_ "SPN" SG_ 2432541694 ETCpssBpssAtt1DsdPst 5366;
BA_ "SPN" SG_ 2432541694 ETCpssBpssAtt1PFMI 5367;
BA_ "SPN" SG_ 2432541694 ETCpssBpssAtt1TptStts 5368;
BA_ "SPN" SG_ 2432593918 ACCDistanceAlertSignal 1796;
BA_ "SPN" SG_ 2432593918 ACCSystemShutoffWarning 1797;
BA_ "SPN" SG_ 2432593918 ACCTargetDetected 1798;
BA_ "SPN" SG_ 2432593918 AdaptiveCruiseControlMode 1590;
BA_ "SPN" SG_ 2432593918 AdaptiveCruiseControlSetSpeed 1588;
BA_ "SPN" SG_ 2432593918 Adptvrsntrlstdstnmd 1589;
BA_ "SPN" SG_ 2432593918 Distancetoforwardvehicle 1587;
BA_ "SPN" SG_ 2432593918 ForwardCollisionWarning 5022;
BA_ "SPN" SG_ 2432593918 Roadcurvature 1591;
BA_ "SPN" SG_ 2432593918 Speedofforwardvehicle 1586;
BA_ "SPN" SG_ 2432595710 DisplayDeadbands 2577;
BA_ "SPN" SG_ 2432595710 LEDDisplayData1 1573;
BA_ "SPN" SG_ 2432595710 LEDDisplayDeadbandControl 1806;
BA_ "SPN" SG_ 2432595710 LEDDisplayModeControl 1805;
BA_ "SPN" SG_ 2432595710 LEDPatternControl 2578;
BA_ "SPN" SG_ 2498776830 EngnClndr1AvrgCmstnDrtn 6486;
BA_ "SPN" SG_ 2498776830 EngnClndr1AvrgCntrfCmstnTmng 6485;
BA_ "SPN" SG_ 2498776830 EngnClndr1AvrgStrtfCmstnTmng 6484;
BA_ "SPN" SG_ 2498776830 EngnClndr1IndtdMnEfftvPrssr 6483;
BA_ "SPN" SG_ 2498777086 EngnClndr2AvrgCmstnDrtn 6490;
BA_ "SPN" SG_ 2498777086 EngnClndr2AvrgCntrfCmstnTmng 6489;
BA_ "SPN" SG_ 2498777086 EngnClndr2AvrgStrtfCmstnTmng 6488;
BA_ "SPN" SG_ 2498777086 EngnClndr2IndtdMnEfftvPrssr 6487;
BA_ "SPN" SG_ 2498777342 EngnClndr3AvrgCmstnDrtn 6494;
BA_ "SPN" SG_ 2498777342 EngnClndr3AvrgCntrfCmstnTmng 6493;
BA_ "SPN" SG_ 2498777342 EngnClndr3AvrgStrtfCmstnTmng 6492;
BA_ "SPN" SG_ 2498777342 EngnClndr3IndtdMnEfftvPrssr 6491;
BA_ "SPN" SG_ 2498777598 EngnClndr4AvrgCmstnDrtn 6498;
BA_ "SPN" SG_ 2498777598 EngnClndr4AvrgCntrfCmstnTmng 6497;
BA_ "SPN" SG_ 2498777598 EngnClndr4AvrgStrtfCmstnTmng 6496;
BA_ "SPN" SG_ 2498777598 EngnClndr4IndtdMnEfftvPrssr 6495;
BA_ "SPN" SG_ 2498777854 EngnClndr5AvrgCmstnDrtn 6502;
BA_ "SPN" SG_ 2498777854 EngnClndr5AvrgCntrfCmstnTmng 6501;
BA_ "SPN" SG_ 2498777854 EngnClndr5AvrgStrtfCmstnTmng 6500;
BA_ "SPN" SG_ 2498777854 EngnClndr5IndtdMnEfftvPrssr 6499;
BA_ "SPN" SG_ 2498778110 EngnClndr6AvrgCmstnDrtn 6506;
BA_ "SPN" SG_ 2498778110 EngnClndr6AvrgCntrfCmstnTmng 6505;
BA_ "SPN" SG_ 2498778110 EngnClndr6AvrgStrtfCmstnTmng 6504;
BA_ "SPN" SG_ 2498778110 EngnClndr6IndtdMnEfftvPrssr 6503;
BA_ "SPN" SG_ 2498778366 EngnClndr7AvrgCmstnDrtn 6510;
BA_ "SPN" SG_ 2498778366 EngnClndr7AvrgCntrfCmstnTmng 6509;
BA_ "SPN" SG_ 2498778366 EngnClndr7AvrgStrtfCmstnTmng 6508;
BA_ "SPN" SG_ 2498778366 EngnClndr7IndtdMnEfftvPrssr 6507;
BA_ "SPN" SG_ 2498778622 EngnClndr8AvrgCmstnDrtn 6514;
BA_ "SPN" SG_ 2498778622 EngnClndr8AvrgCntrfCmstnTmng 6513;
BA_ "SPN" SG_ 2498778622 EngnClndr8AvrgStrtfCmstnTmng 6512;
BA_ "SPN" SG_ 2498778622 EngnClndr8IndtdMnEfftvPrssr 6511;
BA_ "SPN" SG_ 2498778878 EngnClndr9AvrgCmstnDrtn 6518;
BA_ "SPN" SG_ 2498778878 EngnClndr9AvrgCntrfCmstnTmng 6517;
BA_ "SPN" SG_ 2498778878 EngnClndr9AvrgStrtfCmstnTmng 6516;
BA_ "SPN" SG_ 2498778878 EngnClndr9IndtdMnEfftvPrssr 6515;
BA_ "SPN" SG_ 2498779134 EngnClndr10AvrgCmstnDrtn 6522;
BA_ "SPN" SG_ 2498779134 EngnClndr10AvrgCntrfCmstnTmng 6521;
BA_ "SPN" SG_ 2498779134 EngnClndr10AvrgStrtfCmstnTmng 6520;
BA_ "SPN" SG_ 2498779134 EngnClndr10IndtdMnEfftvPrssr 6519;
BA_ "SPN" SG_ 2498779390 EngnClndr11AvrgCmstnDrtn 6526;
BA_ "SPN" SG_ 2498779390 EngnClndr11AvrgCntrfCmstnTmng 6525;
BA_ "SPN" SG_ 2498779390 EngnClndr11AvrgStrtfCmstnTmng 6524;
BA_ "SPN" SG_ 2498779390 EngnClndr11IndtdMnEfftvPrssr 6523;
BA_ "SPN" SG_ 2498779646 EngnClndr12AvrgCmstnDrtn 6530;
BA_ "SPN" SG_ 2498779646 EngnClndr12AvrgCntrfCmstnTmng 6529;
BA_ "SPN" SG_ 2498779646 EngnClndr12AvrgStrtfCmstnTmng 6528;
BA_ "SPN" SG_ 2498779646 EngnClndr12IndtdMnEfftvPrssr 6527;
BA_ "SPN" SG_ 2498779902 EngnClndr13AvrgCmstnDrtn 6534;
BA_ "SPN" SG_ 2498779902 EngnClndr13AvrgCntrfCmstnTmng 6533;
BA_ "SPN" SG_ 2498779902 EngnClndr13AvrgStrtfCmstnTmng 6532;
BA_ "SPN" SG_ 2498779902 EngnClndr13IndtdMnEfftvPrssr 6531;
BA_ "SPN" SG_ 2498780158 EngnClndr14AvrgCmstnDrtn 6538;
BA_ "SPN" SG_ 2498780158 EngnClndr14AvrgCntrfCmstnTmng 6537;
BA_ "SPN" SG_ 2498780158 EngnClndr14AvrgStrtfCmstnTmng 6536;
BA_ "SPN" SG_ 2498780158 EngnClndr14IndtdMnEfftvPrssr 6535;
BA_ "SPN" SG_ 2498780414 EngnClndr15AvrgCmstnDrtn 6542;
BA_ "SPN" SG_ 2498780414 EngnClndr15AvrgCntrfCmstnTmng 6541;
BA_ "SPN" SG_ 2498780414 EngnClndr15AvrgStrtfCmstnTmng 6540;
BA_ "SPN" SG_ 2498780414 EngnClndr15IndtdMnEfftvPrssr 6539;
BA_ "SPN" SG_ 2498780670 EngnClndr16AvrgCmstnDrtn 6546;
BA_ "SPN" SG_ 2498780670 EngnClndr16AvrgCntrfCmstnTmng 6545;
BA_ "SPN" SG_ 2498780670 EngnClndr16AvrgStrtfCmstnTmng 6544;
BA_ "SPN" SG_ 2498780670 EngnClndr16IndtdMnEfftvPrssr 6543;
BA_ "SPN" SG_ 2498780926 EngnClndr17AvrgCmstnDrtn 6550;
BA_ "SPN" SG_ 2498780926 EngnClndr17AvrgCntrfCmstnTmng 6549;
BA_ "SPN" SG_ 2498780926 EngnClndr17AvrgStrtfCmstnTmng 6548;
BA_ "SPN" SG_ 2498780926 EngnClndr17IndtdMnEfftvPrssr 6547;
BA_ "SPN" SG_ 2498781182 EngnClndr18AvrgCmstnDrtn 6554;
BA_ "SPN" SG_ 2498781182 EngnClndr18AvrgCntrfCmstnTmng 6553;
BA_ "SPN" SG_ 2498781182 EngnClndr18AvrgStrtfCmstnTmng 6552;
BA_ "SPN" SG_ 2498781182 EngnClndr18IndtdMnEfftvPrssr 6551;
BA_ "SPN" SG_ 2498781438 EngnClndr19AvrgCmstnDrtn 6558;
BA_ "SPN" SG_ 2498781438 EngnClndr19AvrgCntrfCmstnTmng 6557;
BA_ "SPN" SG_ 2498781438 EngnClndr19AvrgStrtfCmstnTmng 6556;
BA_ "SPN" SG_ 2498781438 EngnClndr19IndtdMnEfftvPrssr 6555;
BA_ "SPN" SG_ 2498781694 EngnClndr20AvrgCmstnDrtn 6562;
BA_ "SPN" SG_ 2498781694 EngnClndr20AvrgCntrfCmstnTmng 6561;
BA_ "SPN" SG_ 2498781694 EngnClndr20AvrgStrtfCmstnTmng 6560;
BA_ "SPN" SG_ 2498781694 EngnClndr20IndtdMnEfftvPrssr 6559;
BA_ "SPN" SG_ 2498825982 DmpBdRsPstnRltvtRmmnddMxmm 8314;
BA_ "SPN" SG_ 2498825982 DumpBodyEjectorBladePosition 8315;
BA_ "SPN" SG_ 2498825982 DumpBodyRaiseAngle 8313;
BA_ "SPN" SG_ 2498825982 DumpBodyRollAngle 8312;
BA_ "SPN" SG_ 2499547902 CabDoorsLockActuationCommand 7727;
BA_ "SPN" SG_ 2499547902 LeftFrontWindowPositionCommand 7729;
BA_ "SPN" SG_ 2499547902 LeftRearWindowPositionCommand 7731;
BA_ "SPN" SG_ 2499547902 MirrorLeft1HeatCommand 7741;
BA_ "SPN" SG_ 2499547902 MirrorLeft1HorizontalCommand 7733;
BA_ "SPN" SG_ 2499547902 MirrorLeft1VerticalCommand 7734;
BA_ "SPN" SG_ 2499547902 MirrorLeft2HeatCommand 7743;
BA_ "SPN" SG_ 2499547902 MirrorLeft2HorizontalCommand 7737;
BA_ "SPN" SG_ 2499547902 MirrorLeft2VerticalCommand 7738;
BA_ "SPN" SG_ 2499547902 MirrorRight1HeatCommand 7742;
BA_ "SPN" SG_ 2499547902 MirrorRight1HorizontalCommand 7735;
BA_ "SPN" SG_ 2499547902 MirrorRight1VerticalCommand 7736;
BA_ "SPN" SG_ 2499547902 MirrorRight2HeatCommand 7744;
BA_ "SPN" SG_ 2499547902 MirrorRight2HorizontalCommand 7739;
BA_ "SPN" SG_ 2499547902 MirrorRight2VerticalCommand 7740;
BA_ "SPN" SG_ 2499547902 RemoteCabDoorLockRequest 7728;
BA_ "SPN" SG_ 2499547902 RightFrontWindowPositionCommand 7730;
BA_ "SPN" SG_ 2499547902 RightRearWindowPositionCommand 7732;
BA_ "SPN" SG_ 2499548158 LeftFrontCabDoorLatchPosition 7723;
BA_ "SPN" SG_ 2499548158 LeftRearCabDoorLatchPosition 7725;
BA_ "SPN" SG_ 2499548158 RightFrontCabDoorLatchPosition 7724;
BA_ "SPN" SG_ 2499548158 RightRearCabDoorLatchPosition 7726;
BA_ "SPN" SG_ 2499548670 BatteryPotentialPowerInput3 7712;
BA_ "SPN" SG_ 2499548670 BatteryPotentialPowerInput4 7713;
BA_ "SPN" SG_ 2499548670 SLIBattery3NetCurrent 7714;
BA_ "SPN" SG_ 2499548670 SLIBattery4NetCurrent 7715;
BA_ "SPN" SG_ 2499548926 PayloadTemperature5 7707;
BA_ "SPN" SG_ 2499549182 PayloadTemperature1 7703;
BA_ "SPN" SG_ 2499549182 PayloadTemperature2 7704;
BA_ "SPN" SG_ 2499549182 PayloadTemperature3 7705;
BA_ "SPN" SG_ 2499549182 PayloadTemperature4 7706;
BA_ "SPN" SG_ 2499556094 Atttt1PttSsHtHSdDvDstStts 7322;
BA_ "SPN" SG_ 2499556094 Atttt1PttSsHtHSdDvPFMI 7321;
BA_ "SPN" SG_ 2499556094 Atttt1PttSsHtLwSdDvDstStts 7324;
BA_ "SPN" SG_ 2499556094 Atttt1PttSsHtLwSdDvPFMI 7323;
BA_ "SPN" SG_ 2499556094 Atttt1PttSsHtPwSppDstStts 7330;
BA_ "SPN" SG_ 2499556094 Atttt1PttSsHtPwSppPFMI 7329;
BA_ "SPN" SG_ 2499556094 Atttt1PttSsIptDstStts 7326;
BA_ "SPN" SG_ 2499556094 Atttt1PttSsIptPFMI 7325;
BA_ "SPN" SG_ 2499556094 Atttt1PttSsPwSppDstStts 7328;
BA_ "SPN" SG_ 2499556094 Atttt1PttSsPwSppPFMI 7327;
BA_ "SPN" SG_ 2499556350 EngnFl1InjtrMtrngRl1DsrdPrssr 7100;
BA_ "SPN" SG_ 2499556350 EngnFl1InjtrMtrngRl2DsrdPrssr 7101;
BA_ "SPN" SG_ 2499556606 EF1ItMtR1Pss1ExtddR 7096;
BA_ "SPN" SG_ 2499556606 EF1ItMtR1Pss2ExtddR 7097;
BA_ "SPN" SG_ 2499556606 EF1ItMtR2Pss1ExtddR 7098;
BA_ "SPN" SG_ 2499556606 EF1ItMtR2Pss2ExtddR 7099;
BA_ "SPN" SG_ 2499557118 EngnGssFlSpplBldVlv1Pstn 7083;
BA_ "SPN" SG_ 2499557118 EngnGssFlSpplBldVlv2Pstn 7084;
BA_ "SPN" SG_ 2499557118 EngnGssFlSpplBldVlv3Pstn 7085;
BA_ "SPN" SG_ 2499557118 EngnGssFlSpplShtffVlv1Pstn 7081;
BA_ "SPN" SG_ 2499557118 EngnGssFlSpplShtffVlv2Pstn 7082;
BA_ "SPN" SG_ 2499557118 InertGasSupplyValvePosition 7442;
BA_ "SPN" SG_ 2499557374 EngineOilMist10Concentration 7080;
BA_ "SPN" SG_ 2499557374 EngineOilMist9Concentration 7079;
BA_ "SPN" SG_ 2499557630 EngineOilMist1Concentration 7071;
BA_ "SPN" SG_ 2499557630 EngineOilMist2Concentration 7072;
BA_ "SPN" SG_ 2499557630 EngineOilMist3Concentration 7073;
BA_ "SPN" SG_ 2499557630 EngineOilMist4Concentration 7074;
BA_ "SPN" SG_ 2499557630 EngineOilMist5Concentration 7075;
BA_ "SPN" SG_ 2499557630 EngineOilMist6Concentration 7076;
BA_ "SPN" SG_ 2499557630 EngineOilMist7Concentration 7077;
BA_ "SPN" SG_ 2499557630 EngineOilMist8Concentration 7078;
BA_ "SPN" SG_ 2499557886 PlntGssFlSpplOtltPrssr 7067;
BA_ "SPN" SG_ 2499557886 PlntInrtGsSpplOtltPrssr 7068;
BA_ "SPN" SG_ 2499558142 EngnGssFlSpplPrssr2 7063;
BA_ "SPN" SG_ 2499558142 EngnGssFlSpplShtffVlv1IntkPrssr 7065;
BA_ "SPN" SG_ 2499558142 EngnGssFlSpplShtffVlv2IntkPrssr 7066;
BA_ "SPN" SG_ 2499558142 EngnGssFlSpplUntIntkPrssr 7064;
BA_ "SPN" SG_ 2499580158 EngnFl1InjtrMtrngRl1Prssr1 6589;
BA_ "SPN" SG_ 2499580158 EngnFl1InjtrMtrngRl1Prssr2 6590;
BA_ "SPN" SG_ 2499580158 EngnFl1InjtrMtrngRl2Prssr1 6591;
BA_ "SPN" SG_ 2499580158 EngnFl1InjtrMtrngRl2Prssr2 6592;
BA_ "SPN" SG_ 2499582206 SftTpSpdLmtRmnngCntnsIntrvlDstn 6914;
BA_ "SPN" SG_ 2499582206 SftTpSpdLmtRmnngDstn 6372;
BA_ "SPN" SG_ 2499582206 SoftTopRatioLimitExceeded 6371;
BA_ "SPN" SG_ 2499582206 SoftTopSpeedLimitActive 6370;
BA_ "SPN" SG_ 2499582206 SoftTopSpeedLimitResetDistance 6373;
BA_ "SPN" SG_ 2499583486 EngnTmngAttr1PstnCmmnd 6336;
BA_ "SPN" SG_ 2499583486 EngnTmngAttr2PstnCmmnd 6337;
BA_ "SPN" SG_ 2499583742 EngineTimingActuator1 635;
BA_ "SPN" SG_ 2499583742 EngineTimingActuator2 1245;
BA_ "SPN" SG_ 2499583742 EngnTmngAttr1RqstdPstn 6334;
BA_ "SPN" SG_ 2499583742 EngnTmngAttr2RqstdPstn 6335;
BA_ "SPN" SG_ 2499592190 TrnsmssnClth1AttrPrnt 5944;
BA_ "SPN" SG_ 2499592190 TrnsmssnClth1ClngAttrStts 5949;
BA_ "SPN" SG_ 2499592190 TrnsmssnClth2AttrPrnt 5945;
BA_ "SPN" SG_ 2499592190 TrnsmssnClth2ClngAttrStts 5950;
BA_ "SPN" SG_ 2499592190 TrnsmssnHdrlPmpAttr1Prnt 5946;
BA_ "SPN" SG_ 2499592190 TrnsmssnHdrlPmpAttr2Prnt 6582;
BA_ "SPN" SG_ 2499592190 TrnsmssnShftAttr1Prnt 5947;
BA_ "SPN" SG_ 2499592190 TrnsmssnShftAttr2Prnt 5948;
BA_ "SPN" SG_ 2499592190 TrnsmssnShftRl1AttrStts 5951;
BA_ "SPN" SG_ 2499592190 TrnsmssnShftRl2AttrStts 5952;
BA_ "SPN" SG_ 2499592190 TrnsmssnShftRl3AttrStts 5953;
BA_ "SPN" SG_ 2499592190 TrnsmssnShftRl4AttrStts 5954;
BA_ "SPN" SG_ 2499592190 TrnsmssnShftRl5AttrStts 5955;
BA_ "SPN" SG_ 2499592190 TrnsmssnShftRl6AttrStts 5956;
BA_ "SPN" SG_ 2499592446 TransmissionShiftRail1Position 4218;
BA_ "SPN" SG_ 2499592446 TransmissionShiftRail2Position 4219;
BA_ "SPN" SG_ 2499592446 TransmissionShiftRail3Position 4220;
BA_ "SPN" SG_ 2499592446 TransmissionShiftRail4Position 5941;
BA_ "SPN" SG_ 2499592446 TransmissionShiftRail5Position 5942;
BA_ "SPN" SG_ 2499592446 TransmissionShiftRail6Position 5943;
BA_ "SPN" SG_ 2499604222 BladeElevationDeviationLeft 5410;
BA_ "SPN" SG_ 2499604222 BladeElevationDeviationRight 5411;
BA_ "SPN" SG_ 2499604222 BldRfrnElvtnOffstLft 5412;
BA_ "SPN" SG_ 2499604222 BldRfrnElvtnOffstRght 5413;
BA_ "SPN" SG_ 2499604478 EExstGsRt1OttAstPssHRst 5431;
BA_ "SPN" SG_ 2499604478 EFDvPssHRstExtddR 7469;
BA_ "SPN" SG_ 2499604478 EngnExhstGsRrltn1IntkAsltPrssr 5430;
BA_ "SPN" SG_ 2499604478 EngnOlPrssrHghRsltnExtnddRng 7468;
BA_ "SPN" SG_ 2499607550 EExstMdB1FwBVvAttPst 5277;
BA_ "SPN" SG_ 2499607550 EExstMdB2FwBVvAttPst 5279;
BA_ "SPN" SG_ 2499614462 DrvrOpntClssftnSstmStts 4963;
BA_ "SPN" SG_ 2499614462 OpntClssftnSstm10Stts 4972;
BA_ "SPN" SG_ 2499614462 OpntClssftnSstm3Stts 4965;
BA_ "SPN" SG_ 2499614462 OpntClssftnSstm4Stts 4966;
BA_ "SPN" SG_ 2499614462 OpntClssftnSstm5Stts 4967;
BA_ "SPN" SG_ 2499614462 OpntClssftnSstm6Stts 4968;
BA_ "SPN" SG_ 2499614462 OpntClssftnSstm7Stts 4969;
BA_ "SPN" SG_ 2499614462 OpntClssftnSstm8Stts 4970;
BA_ "SPN" SG_ 2499614462 OpntClssftnSstm9Stts 4971;
BA_ "SPN" SG_ 2499614462 PssngrOpntClssftnSstmStts 4964;
BA_ "SPN" SG_ 2499614718 Beltlock10Status 4961;
BA_ "SPN" SG_ 2499614718 Beltlock3Status 4954;
BA_ "SPN" SG_ 2499614718 Beltlock4Status 4955;
BA_ "SPN" SG_ 2499614718 Beltlock5Status 4956;
BA_ "SPN" SG_ 2499614718 Beltlock6Status 4957;
BA_ "SPN" SG_ 2499614718 Beltlock7Status 4958;
BA_ "SPN" SG_ 2499614718 Beltlock8Status 4959;
BA_ "SPN" SG_ 2499614718 Beltlock9Status 4960;
BA_ "SPN" SG_ 2499614718 DriverBeltlockStatus 4952;
BA_ "SPN" SG_ 2499614718 PassengerBeltlockStatus 4953;
BA_ "SPN" SG_ 2499614718 PssngrArgDtvtnSwthStts 4962;
BA_ "SPN" SG_ 2499624702 Aftrtrtmnt1SCRIntkTmprtr 4360;
BA_ "SPN" SG_ 2499624702 Aftrtrtmnt1SCROtltTmprtr 4363;
BA_ "SPN" SG_ 2499624702 Atttt1SCRItTptPFMI 4361;
BA_ "SPN" SG_ 2499624702 Atttt1SCROttTptPFMI 4362;
BA_ "SPN" SG_ 2499630078 EngineExhaustTemperatureAverage 4151;
BA_ "SPN" SG_ 2499630078 EngnExhstBnk1TmprtrAvrg 4153;
BA_ "SPN" SG_ 2499630078 EngnExhstBnk2TmprtrAvrg 4152;
BA_ "SPN" SG_ 2499635454 GrossCombinationWeight 417;
BA_ "SPN" SG_ 2499635454 NetVehicleWeightChange 413;
BA_ "SPN" SG_ 2499635966 AdditionalAxleGroupLocation 5935;
BA_ "SPN" SG_ 2499635966 AxleGroupLocation 4073;
BA_ "SPN" SG_ 2499635966 AxleGroupWeight 409;
BA_ "SPN" SG_ 2499641854 EExstGsRt1CBpssAttPst 3672;
BA_ "SPN" SG_ 2550660862 ValveAssemblyLoadsensePressure 4088;
BA_ "SPN" SG_ 2550660862 ValveAssemblySupplyPressure 4089;
BA_ "SPN" SG_ 2550660862 ValveLoadSensePressure 4086;
BA_ "SPN" SG_ 2550660862 ValvePilotPressure 4087;
BA_ "SPN" SG_ 2550988542 EngineClutchEngageRequestStatus 7844;
BA_ "SPN" SG_ 2550988542 ReadyForClutchEngagementStatus 7847;
BA_ "SPN" SG_ 2550988542 AcceleratorPedal3Position 28;
BA_ "SPN" SG_ 2557214462 WSttPpDsPssCtStPtCd 9198;
BA_ "SPN" SG_ 2557214462 WSttPpStPssCtStPtCd 9197;
BA_ "SPN" SG_ 2557345534 WllStmltnPmpPlngrFrngOrdr 8870;
BA_ "SPN" SG_ 2557345534 WllStmltnPmpRdLdHghThrshld 8869;
BA_ "SPN" SG_ 2557345534 WllStmltnPmpStnPrssrHghThrshld 8865;
BA_ "SPN" SG_ 2557345534 WllStmltnPmpStnPrssrLwThrshld 8864;
BA_ "SPN" SG_ 2557345534 WSttPpCstSpdHTsd 8868;
BA_ "SPN" SG_ 2557345534 WSttPpCstSpdLwTsd 8867;
BA_ "SPN" SG_ 2557345534 WSttPpDsPssHTsd 8866;
BA_ "SPN" SG_ 2557345534 WSttPpGBxOPssHTsd 8861;
BA_ "SPN" SG_ 2557345534 WSttPpGBxOPssLwTsd 8860;
BA_ "SPN" SG_ 2557345534 WSttPpGBxOTptHTsd 8863;
BA_ "SPN" SG_ 2557345534 WSttPpGBxOTptLwTsd 8862;
BA_ "SPN" SG_ 2557673214 OlDrsMntrCnfgrtnIdntftnNmr 8191;
BA_ "SPN" SG_ 2557673214 OlDrsMntrFrrsBn1CntCmmnd 8192;
BA_ "SPN" SG_ 2557673214 OlDrsMntrFrrsBn2CntCmmnd 8193;
BA_ "SPN" SG_ 2557673214 OlDrsMntrFrrsBn3CntCmmnd 8194;
BA_ "SPN" SG_ 2557673214 OlDrsMntrFrrsBn4CntCmmnd 8195;
BA_ "SPN" SG_ 2557673214 OlDrsMntrFrrsBn5CntCmmnd 8196;
BA_ "SPN" SG_ 2557673214 OlDrsMntrFrrsBn6CntCmmnd 8197;
BA_ "SPN" SG_ 2557673214 OlDrsMntrNnFrrsBn1CntCmmnd 8198;
BA_ "SPN" SG_ 2557673214 OlDrsMntrNnFrrsBn2CntCmmnd 8199;
BA_ "SPN" SG_ 2557673214 OlDrsMntrNnFrrsBn3CntCmmnd 8200;
BA_ "SPN" SG_ 2557673214 OlDrsMntrNnFrrsBn4CntCmmnd 8201;
BA_ "SPN" SG_ 2557673214 OlDrsMntrNnFrrsBn5CntCmmnd 8202;
BA_ "SPN" SG_ 2557673214 OlDrsMntrNnFrrsBn6CntCmmnd 8203;
BA_ "SPN" SG_ 2557738750 PrplsnMtrClntFn3EnlCmmnd 8063;
BA_ "SPN" SG_ 2557738750 PrplsnMtrClntFn3PrntSpdCmmnd 8066;
BA_ "SPN" SG_ 2557738750 PrplsnMtrClntFn3PwrHld 8064;
BA_ "SPN" SG_ 2557738750 PrplsnMtrClntFn3SpdCmmnd 8065;
BA_ "SPN" SG_ 2557804286 PrplsnMtrClntFn2EnlCmmnd 8051;
BA_ "SPN" SG_ 2557804286 PrplsnMtrClntFn2PrntSpdCmmnd 8054;
BA_ "SPN" SG_ 2557804286 PrplsnMtrClntFn2PwrHld 8052;
BA_ "SPN" SG_ 2557804286 PrplsnMtrClntFn2SpdCmmnd 8053;
BA_ "SPN" SG_ 2557869822 PrplsnMtrClntFn1EnlCmmnd 8039;
BA_ "SPN" SG_ 2557869822 PrplsnMtrClntFn1PrntSpdCmmnd 8042;
BA_ "SPN" SG_ 2557869822 PrplsnMtrClntFn1PwrHld 8040;
BA_ "SPN" SG_ 2557869822 PrplsnMtrClntFn1SpdCmmnd 8041;
BA_ "SPN" SG_ 2557935358 PwrEltrnsClntFn3EnlCmmnd 8027;
BA_ "SPN" SG_ 2557935358 PwrEltrnsClntFn3PrntSpdCmmnd 8030;
BA_ "SPN" SG_ 2557935358 PwrEltrnsClntFn3PwrHld 8028;
BA_ "SPN" SG_ 2557935358 PwrEltrnsClntFn3SpdCmmnd 8029;
BA_ "SPN" SG_ 2558000894 PwrEltrnsClntFn2EnlCmmnd 8015;
BA_ "SPN" SG_ 2558000894 PwrEltrnsClntFn2PrntSpdCmmnd 8018;
BA_ "SPN" SG_ 2558000894 PwrEltrnsClntFn2PwrHld 8016;
BA_ "SPN" SG_ 2558000894 PwrEltrnsClntFn2SpdCmmnd 8017;
BA_ "SPN" SG_ 2558066430 PwrEltrnsClntFn1EnlCmmnd 8003;
BA_ "SPN" SG_ 2558066430 PwrEltrnsClntFn1PrntSpdCmmnd 8006;
BA_ "SPN" SG_ 2558066430 PwrEltrnsClntFn1PwrHld 8004;
BA_ "SPN" SG_ 2558066430 PwrEltrnsClntFn1SpdCmmnd 8005;
BA_ "SPN" SG_ 2558131966 PropulsionMotorOilPumpPowerHold 7992;
BA_ "SPN" SG_ 2558131966 PrplsnMtrOlPmpEnlCmmnd 7991;
BA_ "SPN" SG_ 2558131966 PrplsnMtrOlPmpPrntSpdCmmnd 7994;
BA_ "SPN" SG_ 2558131966 PrplsnMtrOlPmpSpdCmmnd 7993;
BA_ "SPN" SG_ 2558197502 PrplsnMtrClntPmpEnlCmmnd 7979;
BA_ "SPN" SG_ 2558197502 PrplsnMtrClntPmpPrntSpdCmmnd 7982;
BA_ "SPN" SG_ 2558197502 PrplsnMtrClntPmpPwrHld 7980;
BA_ "SPN" SG_ 2558197502 PrplsnMtrClntPmpSpdCmmnd 7981;
BA_ "SPN" SG_ 2558263038 PwrEltrnsClntPmpEnlCmmnd 7967;
BA_ "SPN" SG_ 2558263038 PwrEltrnsClntPmpPrntSpdCmmnd 7970;
BA_ "SPN" SG_ 2558263038 PwrEltrnsClntPmpPwrHld 7968;
BA_ "SPN" SG_ 2558263038 PwrEltrnsClntPmpSpdCmmnd 7969;
BA_ "SPN" SG_ 2558394110 EltrfdAssrMtrEnlCmmnd 7943;
BA_ "SPN" SG_ 2558394110 EltrfdAssrMtrPrntSpdCmmnd 7946;
BA_ "SPN" SG_ 2558394110 EltrfdAssrMtrPwrHld 7944;
BA_ "SPN" SG_ 2558394110 EltrfdAssrMtrSpdCmmnd 7945;
BA_ "SPN" SG_ 2558394110 ElectrifiedAccessoryMotor1 8292;
BA_ "SPN" SG_ 2558394110 ElectrifiedAccessoryMotor2 8293;
BA_ "SPN" SG_ 2558394110 ElectrifiedAccessoryMotor3 8294;
BA_ "SPN" SG_ 2558394110 ElectrifiedAccessoryMotor4 8295;
BA_ "SPN" SG_ 2558394110 ElectrifiedAccessoryMotor5 8296;
BA_ "SPN" SG_ 2558394110 ElectrifiedAccessoryMotor6 8297;
BA_ "SPN" SG_ 2558394110 ElectrifiedAccessoryMotor7 8298;
BA_ "SPN" SG_ 2558394110 ElectrifiedAccessoryMotor8 8299;
BA_ "SPN" SG_ 2558394110 ElectrifiedAccessoryMotor9 8300;
BA_ "SPN" SG_ 2558394110 ElectrifiedAccessoryMotor10 8301;
BA_ "SPN" SG_ 2558394110 ElectrifiedAccessoryMotor11 8302;
BA_ "SPN" SG_ 2558394110 ElectrifiedAccessoryMotor12 8303;
BA_ "SPN" SG_ 2558394110 ElectrifiedAccessoryMotor13 8304;
BA_ "SPN" SG_ 2558394110 ElectrifiedAccessoryMotor14 8305;
BA_ "SPN" SG_ 2558394110 ElectrifiedAccessoryMotor15 8306;
BA_ "SPN" SG_ 2558459646 RqstdEngnSpdAlrtnRtLmt 7760;
BA_ "SPN" SG_ 2558459646 RqstdEngnSpdDlrtnRtLmt 7761;
BA_ "SPN" SG_ 2558525182 NumberofTireSensors 7583;
BA_ "SPN" SG_ 2558525182 TireLocation 7585;
BA_ "SPN" SG_ 2558525182 TireNumber 7584;
BA_ "SPN" SG_ 2558525182 TireSensorIdentificationNumber 7586;
BA_ "SPN" SG_ 2558590718 ExtrnlEnrgSrCnntnDmnd 7890;
BA_ "SPN" SG_ 2558590718 HrdSstmPrplsnDslRqst 7558;
BA_ "SPN" SG_ 2558590718 HrdSstmPrttnOvrrdRqst 7557;
BA_ "SPN" SG_ 2558590718 HrdSstmRgnrtvBrkngDslRqst 7559;
BA_ "SPN" SG_ 2558590718 HybridPropulsionModeRequest 7889;
BA_ "SPN" SG_ 2558590718 HybridSystemShutdownCommand 7560;
BA_ "SPN" SG_ 2558590718 OperatorVehicleModeRequest 7888;
BA_ "SPN" SG_ 2558590718 StrdEnrgSrChrgDshrgRtRqst 7891;
BA_ "SPN" SG_ 2558590718 StrdEnrgSrStPntRqst 7892;
BA_ "SPN" SG_ 2558590718 HVESChargeConsent 10148;
BA_ "SPN" SG_ 2558590718 HrdPrplsnMdRqstdMxmmSpd 9706;
BA_ "SPN" SG_ 2558590718 HrdPrplsnMdRqstdDstn 9707;
BA_ "SPN" SG_ 2558656254 AftrtrtmntDslExhstFldDsrRdStts 8149;
BA_ "SPN" SG_ 2558656254 AftrtrtmntSstmEnlStts 7851;
BA_ "SPN" SG_ 2558656254 AftrtrtmntThrmlMngmntInhtRqst 7331;
BA_ "SPN" SG_ 2558656254 RqsttPrmtDEFHdrlStffnssChk 7515;
BA_ "SPN" SG_ 2558656254 RqsttPrmtSCRDsngTstInjtn 7516;
BA_ "SPN" SG_ 2558721790 ColdInflationPressureSetting 6974;
BA_ "SPN" SG_ 2558721790 ExtrmUndrPrssrPrntgThrshldSttng 6976;
BA_ "SPN" SG_ 2558721790 OverTemperatureSetting 6978;
BA_ "SPN" SG_ 2558721790 OvrPrssrPrntgThrshldSttng 6977;
BA_ "SPN" SG_ 2558721790 TireLocation 6973;
BA_ "SPN" SG_ 2558721790 TireSensorEnableSetting 7587;
BA_ "SPN" SG_ 2558721790 UndrPrssrPrntgThrshldSttng 6975;
BA_ "SPN" SG_ 2558787326 PayloadCorrectionFactorCommand 6873;
BA_ "SPN" SG_ 2558787326 PldClrtnCmmnddWght 6872;
BA_ "SPN" SG_ 2558787326 PldClrtnStPntCmmnd 6871;
BA_ "SPN" SG_ 2558852862 Aftrtrtmnt1PrtltSnsrDwpnt 6784;
BA_ "SPN" SG_ 2558852862 Aftrtrtmnt1PrtltSnsrExhstTmprtr 6785;
BA_ "SPN" SG_ 2558852862 Aftrtrtmnt1PrtltSnsrExhstVlt 6829;
BA_ "SPN" SG_ 2558852862 Aftrtrtmnt1PrtltSnsrRgnrtnRqst 6783;
BA_ "SPN" SG_ 2558852862 Aftrtrtmnt1PrtltSnsrShtdwnRqst 6782;
BA_ "SPN" SG_ 2558918398 ActiveShiftConsoleRequest 8855;
BA_ "SPN" SG_ 2558918398 AftrtrtmntSstmEnlCmmnd 8148;
BA_ "SPN" SG_ 2558918398 AttttRtESpdAwdSwt 7580;
BA_ "SPN" SG_ 2558918398 ElvtdEngnSpdAllwdSwth 7579;
BA_ "SPN" SG_ 2558918398 EngineFan2RequestedPercentSpeed 6730;
BA_ "SPN" SG_ 2558918398 EngineStopStartDisableCommand 7759;
BA_ "SPN" SG_ 2558918398 EngnIdlMngmntPndngEvntOvrrd 9374;
BA_ "SPN" SG_ 2558918398 HtExhngrDrsPrgFrSwth 7034;
BA_ "SPN" SG_ 2558918398 HtExhngrDrsPrgInhtSwth 7033;
BA_ "SPN" SG_ 2558918398 PerformanceBiasSelection 6874;
BA_ "SPN" SG_ 2558918398 PrdtvCrsCntrlDtvtnRqst 7437;
BA_ "SPN" SG_ 2558918398 PrdtvCrsCntrlEnlSwth 7436;
BA_ "SPN" SG_ 2558918398 PrdtvCrsCntrlMxmmNgtvOffst 7439;
BA_ "SPN" SG_ 2558918398 PrdtvCrsCntrlMxmmPstvOffst 7438;
BA_ "SPN" SG_ 2558918398 SCROprtrIndmntOvrrdSwth 6881;
BA_ "SPN" SG_ 2558918398 TrnsmssnAtNtrlMnlRtrnEnlSwth 7694;
BA_ "SPN" SG_ 2558983934 SwitchedPowerOutput10Command 5994;
BA_ "SPN" SG_ 2558983934 SwitchedPowerOutput11Command 5993;
BA_ "SPN" SG_ 2558983934 SwitchedPowerOutput12Command 5992;
BA_ "SPN" SG_ 2558983934 SwitchedPowerOutput13Command 5999;
BA_ "SPN" SG_ 2558983934 SwitchedPowerOutput14Command 5998;
BA_ "SPN" SG_ 2558983934 SwitchedPowerOutput15Command 5997;
BA_ "SPN" SG_ 2558983934 SwitchedPowerOutput16Command 5996;
BA_ "SPN" SG_ 2558983934 SwitchedPowerOutput17Command 6003;
BA_ "SPN" SG_ 2558983934 SwitchedPowerOutput18Command 6002;
BA_ "SPN" SG_ 2558983934 SwitchedPowerOutput19Command 6001;
BA_ "SPN" SG_ 2558983934 SwitchedPowerOutput1Command 5987;
BA_ "SPN" SG_ 2558983934 SwitchedPowerOutput20Command 6000;
BA_ "SPN" SG_ 2558983934 SwitchedPowerOutput21Command 6007;
BA_ "SPN" SG_ 2558983934 SwitchedPowerOutput22Command 6006;
BA_ "SPN" SG_ 2558983934 SwitchedPowerOutput23Command 6005;
BA_ "SPN" SG_ 2558983934 SwitchedPowerOutput24Command 6004;
BA_ "SPN" SG_ 2558983934 SwitchedPowerOutput25Command 6011;
BA_ "SPN" SG_ 2558983934 SwitchedPowerOutput26Command 6010;
BA_ "SPN" SG_ 2558983934 SwitchedPowerOutput27Command 6009;
BA_ "SPN" SG_ 2558983934 SwitchedPowerOutput28Command 6008;
BA_ "SPN" SG_ 2558983934 SwitchedPowerOutput29Command 6015;
BA_ "SPN" SG_ 2558983934 SwitchedPowerOutput2Command 5986;
BA_ "SPN" SG_ 2558983934 SwitchedPowerOutput30Command 6014;
BA_ "SPN" SG_ 2558983934 SwitchedPowerOutput31Command 6013;
BA_ "SPN" SG_ 2558983934 SwitchedPowerOutput32Command 6012;
BA_ "SPN" SG_ 2558983934 SwitchedPowerOutput3Command 5985;
BA_ "SPN" SG_ 2558983934 SwitchedPowerOutput4Command 5984;
BA_ "SPN" SG_ 2558983934 SwitchedPowerOutput5Command 5991;
BA_ "SPN" SG_ 2558983934 SwitchedPowerOutput6Command 5990;
BA_ "SPN" SG_ 2558983934 SwitchedPowerOutput7Command 5989;
BA_ "SPN" SG_ 2558983934 SwitchedPowerOutput8Command 5988;
BA_ "SPN" SG_ 2558983934 SwitchedPowerOutput9Command 5995;
BA_ "SPN" SG_ 2559049470 DesiredEngineFuelingState 5793;
BA_ "SPN" SG_ 2559049470 EngineFuelingDesiredReason 7789;
BA_ "SPN" SG_ 2559049470 EngineFuelingNotDesiredReason 7855;
BA_ "SPN" SG_ 2559049470 EngineGaseousFuelUsageInhibited 6833;
BA_ "SPN" SG_ 2559049470 EngineShutdownCommand 8614;
BA_ "SPN" SG_ 2559049470 EngnGssFlSpplDsrdPrssr 6715;
BA_ "SPN" SG_ 2559049470 EngnPrttnDrtOvrrdCmmnd 9173;
BA_ "SPN" SG_ 2559049470 RequestedFuelType 6317;
BA_ "SPN" SG_ 2559049470 TrnsmssnIdlGvrnrFlngInht 7829;
BA_ "SPN" SG_ 2559115006 RadioBeaconDirection 5755;
BA_ "SPN" SG_ 2559115006 TransmitterID2 5756;
BA_ "SPN" SG_ 2559115006 UnqBnMssgIdntfrNmr 5754;
BA_ "SPN" SG_ 2559115006 WirelessSignalStrength2 5757;
BA_ "SPN" SG_ 2559573758 CtLvEPttStdwOvdCd 5565;
BA_ "SPN" SG_ 2559639294 SupplementalFanDirectionCommand 5553;
BA_ "SPN" SG_ 2559639294 SupplementalFanEnableCommand 5552;
BA_ "SPN" SG_ 2559639294 SupplementalFanPowerHold 5555;
BA_ "SPN" SG_ 2559639294 SupplementalFanSpeedCommand 5554;
BA_ "SPN" SG_ 2559704830 LrtnOprtnMdStCmmnd 5512;
BA_ "SPN" SG_ 2559704830 LubricationCycleModeLockCommand 5510;
BA_ "SPN" SG_ 2559704830 LubricationCycleSetCommand 5511;
BA_ "SPN" SG_ 2559704830 LubricationPumpEnableCommand 5513;
BA_ "SPN" SG_ 2559704830 LubricationTimingCycleCommand 5514;
BA_ "SPN" SG_ 2559770366 DiagnosticStatusofHCDoser 5508;
BA_ "SPN" SG_ 2559770366 HCDoserInjectingStatus 5507;
BA_ "SPN" SG_ 2559770366 HCDoserStatus 5506;
BA_ "SPN" SG_ 2559770366 HydrocarbonDoserPurgingRequired 5509;
BA_ "SPN" SG_ 2559770366 RequestedFuelMassRate 5505;
BA_ "SPN" SG_ 2559770366 Aftertreatment1DPFHydrocarbon 10155;
BA_ "SPN" SG_ 2559901438 Atttt1DsPttFtStMCtOst 5495;
BA_ "SPN" SG_ 2559901438 Atttt1DsPttFtStStddDvtCtOst 5496;
BA_ "SPN" SG_ 2559966974 Atttt2DsPttFtStMCtOst 5497;
BA_ "SPN" SG_ 2559966974 Atttt2DsPttFtStStddDvtCtOst 5498;
BA_ "SPN" SG_ 2560032510 LwVltgDsnntDsrdOprtngMd 5149;
BA_ "SPN" SG_ 2560098046 CabNoiseControlStatus 5059;
BA_ "SPN" SG_ 2560098046 CabNoiseControlTuningStatus 5060;
BA_ "SPN" SG_ 2560163582 CabNoiseControlCommand 5057;
BA_ "SPN" SG_ 2560163582 CabNoiseControlTuningCommand 5058;
BA_ "SPN" SG_ 2560360190 DataDictionaryManufacturerCode 4180;
BA_ "SPN" SG_ 2560360190 DataDictionaryMethod 4181;
BA_ "SPN" SG_ 2560425726 AuxiliaryIOChannel15 4170;
BA_ "SPN" SG_ 2560425726 AuxiliaryIOChannel16 4169;
BA_ "SPN" SG_ 2560425726 AuxiliaryIOChannel17 4168;
BA_ "SPN" SG_ 2560425726 AuxiliaryIOChannel18 4167;
BA_ "SPN" SG_ 2560425726 AuxiliaryIOChannel19 4174;
BA_ "SPN" SG_ 2560425726 AuxiliaryIOChannel20 4173;
BA_ "SPN" SG_ 2560425726 AuxiliaryIOChannel21 4172;
BA_ "SPN" SG_ 2560425726 AuxiliaryIOChannel22 4171;
BA_ "SPN" SG_ 2560491262 AuxiliaryIOChannel10 4159;
BA_ "SPN" SG_ 2560491262 AuxiliaryIOChannel11 4166;
BA_ "SPN" SG_ 2560491262 AuxiliaryIOChannel12 4165;
BA_ "SPN" SG_ 2560491262 AuxiliaryIOChannel13 4164;
BA_ "SPN" SG_ 2560491262 AuxiliaryIOChannel14 4163;
BA_ "SPN" SG_ 2560491262 AuxiliaryIOChannel7 4162;
BA_ "SPN" SG_ 2560491262 AuxiliaryIOChannel8 4161;
BA_ "SPN" SG_ 2560491262 AuxiliaryIOChannel9 4160;
BA_ "SPN" SG_ 2561015550 AuxiliaryIO100 3923;
BA_ "SPN" SG_ 2561015550 AuxiliaryIO101 3924;
BA_ "SPN" SG_ 2561015550 AuxiliaryIO102 3925;
BA_ "SPN" SG_ 2561015550 AuxiliaryIO103 3926;
BA_ "SPN" SG_ 2561015550 AuxiliaryIO104 3927;
BA_ "SPN" SG_ 2561015550 AuxiliaryIO105 3928;
BA_ "SPN" SG_ 2561015550 AuxiliaryIO106 3929;
BA_ "SPN" SG_ 2561015550 AuxiliaryIO107 3930;
BA_ "SPN" SG_ 2561015550 AuxiliaryIO108 3931;
BA_ "SPN" SG_ 2561015550 AuxiliaryIO109 3932;
BA_ "SPN" SG_ 2561015550 AuxiliaryIO110 3933;
BA_ "SPN" SG_ 2561015550 AuxiliaryIO111 3934;
BA_ "SPN" SG_ 2561015550 AuxiliaryIO112 3935;
BA_ "SPN" SG_ 2561015550 AuxiliaryIO81 3904;
BA_ "SPN" SG_ 2561015550 AuxiliaryIO82 3905;
BA_ "SPN" SG_ 2561015550 AuxiliaryIO83 3906;
BA_ "SPN" SG_ 2561015550 AuxiliaryIO84 3907;
BA_ "SPN" SG_ 2561015550 AuxiliaryIO85 3908;
BA_ "SPN" SG_ 2561015550 AuxiliaryIO86 3909;
BA_ "SPN" SG_ 2561015550 AuxiliaryIO87 3910;
BA_ "SPN" SG_ 2561015550 AuxiliaryIO88 3911;
BA_ "SPN" SG_ 2561015550 AuxiliaryIO89 3912;
BA_ "SPN" SG_ 2561015550 AuxiliaryIO90 3913;
BA_ "SPN" SG_ 2561015550 AuxiliaryIO91 3914;
BA_ "SPN" SG_ 2561015550 AuxiliaryIO92 3915;
BA_ "SPN" SG_ 2561015550 AuxiliaryIO93 3916;
BA_ "SPN" SG_ 2561015550 AuxiliaryIO94 3917;
BA_ "SPN" SG_ 2561015550 AuxiliaryIO95 3918;
BA_ "SPN" SG_ 2561015550 AuxiliaryIO96 3919;
BA_ "SPN" SG_ 2561015550 AuxiliaryIO97 3920;
BA_ "SPN" SG_ 2561015550 AuxiliaryIO98 3921;
BA_ "SPN" SG_ 2561015550 AuxiliaryIO99 3922;
BA_ "SPN" SG_ 2561081086 AuxiliaryIO49 3872;
BA_ "SPN" SG_ 2561081086 AuxiliaryIO50 3873;
BA_ "SPN" SG_ 2561081086 AuxiliaryIO51 3874;
BA_ "SPN" SG_ 2561081086 AuxiliaryIO52 3875;
BA_ "SPN" SG_ 2561081086 AuxiliaryIO53 3876;
BA_ "SPN" SG_ 2561081086 AuxiliaryIO54 3877;
BA_ "SPN" SG_ 2561081086 AuxiliaryIO55 3878;
BA_ "SPN" SG_ 2561081086 AuxiliaryIO56 3879;
BA_ "SPN" SG_ 2561081086 AuxiliaryIO57 3880;
BA_ "SPN" SG_ 2561081086 AuxiliaryIO58 3881;
BA_ "SPN" SG_ 2561081086 AuxiliaryIO59 3882;
BA_ "SPN" SG_ 2561081086 AuxiliaryIO60 3883;
BA_ "SPN" SG_ 2561081086 AuxiliaryIO61 3884;
BA_ "SPN" SG_ 2561081086 AuxiliaryIO62 3885;
BA_ "SPN" SG_ 2561081086 AuxiliaryIO63 3886;
BA_ "SPN" SG_ 2561081086 AuxiliaryIO64 3887;
BA_ "SPN" SG_ 2561081086 AuxiliaryIO65 3888;
BA_ "SPN" SG_ 2561081086 AuxiliaryIO66 3889;
BA_ "SPN" SG_ 2561081086 AuxiliaryIO67 3890;
BA_ "SPN" SG_ 2561081086 AuxiliaryIO68 3891;
BA_ "SPN" SG_ 2561081086 AuxiliaryIO69 3892;
BA_ "SPN" SG_ 2561081086 AuxiliaryIO70 3893;
BA_ "SPN" SG_ 2561081086 AuxiliaryIO71 3894;
BA_ "SPN" SG_ 2561081086 AuxiliaryIO72 3895;
BA_ "SPN" SG_ 2561081086 AuxiliaryIO73 3896;
BA_ "SPN" SG_ 2561081086 AuxiliaryIO74 3897;
BA_ "SPN" SG_ 2561081086 AuxiliaryIO75 3898;
BA_ "SPN" SG_ 2561081086 AuxiliaryIO76 3899;
BA_ "SPN" SG_ 2561081086 AuxiliaryIO77 3900;
BA_ "SPN" SG_ 2561081086 AuxiliaryIO78 3901;
BA_ "SPN" SG_ 2561081086 AuxiliaryIO79 3902;
BA_ "SPN" SG_ 2561081086 AuxiliaryIO80 3903;
